VERSION ""

NS_ :

BS_:

BU_: WCM4 WCM3 WCM2 WCM VPM VLM VKM VICM VECM VDM VCU_RTOS_ETH VCU_ENTRY_ETH VCU_AGVM_ETH VCU UVM UPM TIM TEST_TOOL_1 TCP_ETH TCP TCM TCCM SRR_SRR_ETH SRR_SRR SRR_SLR_ETH SRR_SLR SRR_RR SRR_RF_ETH SRR_RF SRR_LR_CR SRR_LF_ETH SRR_LF SIB SDM SCL SBZA_R SBZA_L SBM SAM_RR SAM_RF SAM_LR SAM_LF SAM_BH SADS RadioLow_ETH RadioLow RSI_RTOS_ETH RSI RDCM PTM PLCM PFCM PDR_ETH PDR PCM PA ODS2 ODS NVM MTCM_R MTCM_L MSM_RR MSM_P MSM_LR MSM_D MSB2 MSB1 MRCM_R MRCM_L MFC LRR_RR_ETH LRR_LR_ETH LRR_CF_ETH LRR LRL_CF_ETH LIB_48V LIB1 IPC_INT IPC_GP IPC ICS_Info ICCM HVAC_FP_R HVAC_FP_F HUD_CAN HDLM FPI_RTOS_ETH FPI FOPM FCM_LC FCM EPSb EPS_1 EPSRAb EPSRAa EPS EOCM_HC_Superset EOCM_HCP2 EOCM ELM ECP_X1 ECP_S2 ECP_S ECP_MC ECP_H3 ECP_H2 ECP_H1 ECP_E ECM EBCM DMS DEFC DCM CSM_ETH CSM_AV CSM CGM_OTA_ETH CGM BSM_MH BSM_HEV BSM BCM ARS ARB APA AOS AMP ALC AHS AHL_AFL ADIMb ADIMa ACP2_MCU
VAL_TABLE_ SRRRFODPB4P_VOTk8CnfdStsAuth 0 "Highly Speculative" 1 "Speculative" 2 "Confident" 3 "Highly Confident" ;
VAL_TABLE_ SRRRFODPB4P_VOTk8DynPrpStsAuth 0 "Stopped" 1 "Not Stopped" ;
VAL_TABLE_ SRRRFODPB4P_VOTk8DynPrpAuth 0 "Has Never Moved" 1 "Moving In Same Direction As Host" 2 "Moving In Opposite Direction As Host" 3 "Crossing From Left To Right" 4 "Crossing From Right To Left" ;
VAL_TABLE_ SRRRFODPB4P_VOTk8MStsAuth 0 "No Object" 1 "New Object" 2 "Latent Track Not Detected this Cycle" 3 "Measured this Cycle" ;
VAL_TABLE_ SRRRFODPB4P_VOTk8TypCnfdAuth 0 "Highly Speculative" 1 "Speculative" 2 "Confident" 3 "Highly Confident" ;
VAL_TABLE_ SRRRFODPB4P_VOTk9DynPrpStsAuth 0 "Stopped" 1 "Not Stopped" ;
VAL_TABLE_ SRRRFODPB4P_VOTk9DynPrpAuth 0 "Has Never Moved" 1 "Moving In Same Direction As Host" 2 "Moving In Opposite Direction As Host" 3 "Crossing From Left To Right" 4 "Crossing From Right To Left" ;
VAL_TABLE_ SRRRFODPB4P_VOTk9CnfdStsAuth 0 "Highly Speculative" 1 "Speculative" 2 "Confident" 3 "Highly Confident" ;
VAL_TABLE_ SRRRFODPB4P_VOTk9MStsAuth 0 "No Object" 1 "New Object" 2 "Latent Track Not Detected this Cycle" 3 "Measured this Cycle" ;
VAL_TABLE_ SRRRFODPB4P_VOTk9TypCnfdAuth 0 "Highly Speculative" 1 "Speculative" 2 "Confident" 3 "Highly Confident" ;
VAL_TABLE_ SRRRFODPB5P_IOTk10ElvtnAuth 0 "Not Elevated" 1 "Elevation Speculative" 2 "Elevation Confident" 3 "Elevation Very Confident" ;
VAL_TABLE_ SRRRFODPB5P_IOTk10CnfdStsAuth 0 "Highly Speculative" 1 "Speculative" 2 "Confident" 3 "Highly Confident" ;
VAL_TABLE_ SRRRFODPB5P_IOTk10MStsAuth 0 "No Object" 1 "New Object" 2 "Latent Track Not Detected this Cycle" 3 "Measured this Cycle" ;
VAL_TABLE_ SRRRFODPB5P_IOTk1CnfdStsAuth 0 "Highly Speculative" 1 "Speculative" 2 "Confident" 3 "Highly Confident" ;
VAL_TABLE_ SRRRFODPB5P_IOTk10TypCnfdAuth 0 "Highly Speculative" 1 "Speculative" 2 "Confident" 3 "Highly Confident" ;
VAL_TABLE_ SRRRFODPB5P_IOTk10TypAuth 0 "Unknown" 1 "Guard Rail" 2 "Tunnel" 3 "Traffic Sign" 4 "Bridge" 5 "Pole" ;
VAL_TABLE_ SRRRFODPB5P_IOTk1ElvtnAuth 0 "Not Elevated" 1 "Elevation Speculative" 2 "Elevation Confident" 3 "Elevation Very Confident" ;
VAL_TABLE_ SRRRFODPB5P_IOTk1MStsAuth 0 "No Object" 1 "New Object" 2 "Latent Track Not Detected this Cycle" 3 "Measured this Cycle" ;
VAL_TABLE_ SRRRFODPB5P_IOTk1TypAuth 0 "Unknown" 1 "Guard Rail" 2 "Tunnel" 3 "Traffic Sign" 4 "Bridge" 5 "Pole" ;
VAL_TABLE_ SRRRFODPB5P_IOTk2ElvtnAuth 0 "Not Elevated" 1 "Elevation Speculative" 2 "Elevation Confident" 3 "Elevation Very Confident" ;
VAL_TABLE_ SRRRFODPB5P_IOTk2CnfdStsAuth 0 "Highly Speculative" 1 "Speculative" 2 "Confident" 3 "Highly Confident" ;
VAL_TABLE_ SRRRFODPB5P_IOTk1TypCnfdAuth 0 "Highly Speculative" 1 "Speculative" 2 "Confident" 3 "Highly Confident" ;
VAL_TABLE_ SRRRFODPB5P_IOTk2MStsAuth 0 "No Object" 1 "New Object" 2 "Latent Track Not Detected this Cycle" 3 "Measured this Cycle" ;
VAL_TABLE_ SRRRFODPB5P_IOTk2TypCnfdAuth 0 "Highly Speculative" 1 "Speculative" 2 "Confident" 3 "Highly Confident" ;
VAL_TABLE_ SRRRFODPB5P_IOTk2TypAuth 0 "Unknown" 1 "Guard Rail" 2 "Tunnel" 3 "Traffic Sign" 4 "Bridge" 5 "Pole" ;
VAL_TABLE_ SRRRFODPB5P_IOTk3ElvtnAuth 0 "Not Elevated" 1 "Elevation Speculative" 2 "Elevation Confident" 3 "Elevation Very Confident" ;
VAL_TABLE_ SRRRFODPB5P_IOTk3CnfdStsAuth 0 "Highly Speculative" 1 "Speculative" 2 "Confident" 3 "Highly Confident" ;
VAL_TABLE_ SRRRFODPB5P_IOTk3MStsAuth 0 "No Object" 1 "New Object" 2 "Latent Track Not Detected this Cycle" 3 "Measured this Cycle" ;
VAL_TABLE_ SRRRFODPB5P_IOTk4CnfdStsAuth 0 "Highly Speculative" 1 "Speculative" 2 "Confident" 3 "Highly Confident" ;
VAL_TABLE_ SRRRFODPB5P_IOTk3TypCnfdAuth 0 "Highly Speculative" 1 "Speculative" 2 "Confident" 3 "Highly Confident" ;
VAL_TABLE_ SRRRFODPB5P_IOTk3TypAuth 0 "Unknown" 1 "Guard Rail" 2 "Tunnel" 3 "Traffic Sign" 4 "Bridge" 5 "Pole" ;
VAL_TABLE_ SRRRFODPB5P_IOTk4ElvtnAuth 0 "Not Elevated" 1 "Elevation Speculative" 2 "Elevation Confident" 3 "Elevation Very Confident" ;
VAL_TABLE_ SRRRFODPB5P_IOTk4MStsAuth 0 "No Object" 1 "New Object" 2 "Latent Track Not Detected this Cycle" 3 "Measured this Cycle" ;
VAL_TABLE_ SRRRFODPB5P_IOTk4TypAuth 0 "Unknown" 1 "Guard Rail" 2 "Tunnel" 3 "Traffic Sign" 4 "Bridge" 5 "Pole" ;
VAL_TABLE_ SRRRFODPB5P_IOTk5ElvtnAuth 0 "Not Elevated" 1 "Elevation Speculative" 2 "Elevation Confident" 3 "Elevation Very Confident" ;
VAL_TABLE_ SRRRFODPB5P_IOTk5CnfdStsAuth 0 "Highly Speculative" 1 "Speculative" 2 "Confident" 3 "Highly Confident" ;
VAL_TABLE_ SRRRFODPB5P_IOTk4TypCnfdAuth 0 "Highly Speculative" 1 "Speculative" 2 "Confident" 3 "Highly Confident" ;
VAL_TABLE_ SRRRFODPB5P_IOTk5MStsAuth 0 "No Object" 1 "New Object" 2 "Latent Track Not Detected this Cycle" 3 "Measured this Cycle" ;
VAL_TABLE_ SRRRFODPB5P_IOTk5TypCnfdAuth 0 "Highly Speculative" 1 "Speculative" 2 "Confident" 3 "Highly Confident" ;
VAL_TABLE_ SRRRFODPB5P_IOTk5TypAuth 0 "Unknown" 1 "Guard Rail" 2 "Tunnel" 3 "Traffic Sign" 4 "Bridge" 5 "Pole" ;
VAL_TABLE_ SRRRFODPB5P_IOTk6ElvtnAuth 0 "Not Elevated" 1 "Elevation Speculative" 2 "Elevation Confident" 3 "Elevation Very Confident" ;
VAL_TABLE_ SRRRFODPB5P_IOTk6CnfdStsAuth 0 "Highly Speculative" 1 "Speculative" 2 "Confident" 3 "Highly Confident" ;
VAL_TABLE_ SRRRFODPB5P_IOTk6MStsAuth 0 "No Object" 1 "New Object" 2 "Latent Track Not Detected this Cycle" 3 "Measured this Cycle" ;
VAL_TABLE_ SRRRFODPB5P_IOTk7ElvtnAuth 0 "Not Elevated" 1 "Elevation Speculative" 2 "Elevation Confident" 3 "Elevation Very Confident" ;
VAL_TABLE_ SRRRFODPB5P_IOTk7CnfdStsAuth 0 "Highly Speculative" 1 "Speculative" 2 "Confident" 3 "Highly Confident" ;
VAL_TABLE_ SRRRFODPB5P_IOTk6TypCnfdAuth 0 "Highly Speculative" 1 "Speculative" 2 "Confident" 3 "Highly Confident" ;
VAL_TABLE_ SRRRFODPB5P_IOTk6TypAuth 0 "Unknown" 1 "Guard Rail" 2 "Tunnel" 3 "Traffic Sign" 4 "Bridge" 5 "Pole" ;
VAL_TABLE_ SRRRFODPB5P_IOTk7MStsAuth 0 "No Object" 1 "New Object" 2 "Latent Track Not Detected this Cycle" 3 "Measured this Cycle" ;
VAL_TABLE_ SRRRFODPB5P_IOTk7TypAuth 0 "Unknown" 1 "Guard Rail" 2 "Tunnel" 3 "Traffic Sign" 4 "Bridge" 5 "Pole" ;
VAL_TABLE_ SRRRFODPB5P_IOTk8ElvtnAuth 0 "Not Elevated" 1 "Elevation Speculative" 2 "Elevation Confident" 3 "Elevation Very Confident" ;
VAL_TABLE_ SRRRFODPB5P_IOTk8CnfdStsAuth 0 "Highly Speculative" 1 "Speculative" 2 "Confident" 3 "Highly Confident" ;
VAL_TABLE_ SRRRFODPB5P_IOTk7TypCnfdAuth 0 "Highly Speculative" 1 "Speculative" 2 "Confident" 3 "Highly Confident" ;
VAL_TABLE_ SRRRFODPB5P_IOTk8MStsAuth 0 "No Object" 1 "New Object" 2 "Latent Track Not Detected this Cycle" 3 "Measured this Cycle" ;
VAL_TABLE_ SRRRFODPB5P_IOTk9CnfdStsAuth 0 "Highly Speculative" 1 "Speculative" 2 "Confident" 3 "Highly Confident" ;
VAL_TABLE_ SRRRFODPB5P_IOTk8TypCnfdAuth 0 "Highly Speculative" 1 "Speculative" 2 "Confident" 3 "Highly Confident" ;
VAL_TABLE_ SRRRFODPB5P_IOTk8TypAuth 0 "Unknown" 1 "Guard Rail" 2 "Tunnel" 3 "Traffic Sign" 4 "Bridge" 5 "Pole" ;
VAL_TABLE_ SRRRFODPB5P_IOTk9ElvtnAuth 0 "Not Elevated" 1 "Elevation Speculative" 2 "Elevation Confident" 3 "Elevation Very Confident" ;
VAL_TABLE_ SRRRFODPB5P_IOTk9MStsAuth 0 "No Object" 1 "New Object" 2 "Latent Track Not Detected this Cycle" 3 "Measured this Cycle" ;
VAL_TABLE_ SRRRFODPB5P_IOTk9TypAuth 0 "Unknown" 1 "Guard Rail" 2 "Tunnel" 3 "Traffic Sign" 4 "Bridge" 5 "Pole" ;
VAL_TABLE_ SRRRFODPB5P_IOTk9TypCnfdAuth 0 "Highly Speculative" 1 "Speculative" 2 "Confident" 3 "Highly Confident" ;
VAL_TABLE_ SRRRFODPB1P_ConstrArDtnCnfdAuth 0 "Highly Speculative" 1 "Speculative" 2 "Confident" 3 "Highly Confident" ;
VAL_TABLE_ SRRRFODPB1P_AcqTmStmAuth_Inv 0 "FALSE" 1 "TRUE" ;
VAL_TABLE_ SRRRFODPB1P_POTk1DynPrpAuth 0 "Has Never Moved" 1 "Has Moved But Currently Stopped" 2 "Moving In Same Direction As Host" 3 "Moving In Opposite Direction As Host" 4 "Crossing Path" ;
VAL_TABLE_ SRRRFODPB1P_POTk1CnfdStsAuth 0 "Highly Speculative" 1 "Speculative" 2 "Confident" 3 "Highly Confident" ;
VAL_TABLE_ SRRRFODPB1P_MdCmdStsAuth 0 "Not Radiating" 1 "Reporting Object Data" 2 "Not Reporting Object Data" ;
VAL_TABLE_ SRRRFODPB1P_ConstrArDtnStsAuth 0 "Not Detected" 1 "Detected" 2 "Unknown" ;
VAL_TABLE_ SRRRFODPB1P_POTk1MStsAuth 0 "No Object" 1 "New Object" 2 "Latent Track Not Detected this Cycle" 3 "Measured this Cycle" ;
VAL_TABLE_ SRRRFODPB1P_POTk2CnfdStsAuth 0 "Highly Speculative" 1 "Speculative" 2 "Confident" 3 "Highly Confident" ;
VAL_TABLE_ SRRRFODPB1P_POTk1TypCnfdAuth 0 "Highly Speculative" 1 "Speculative" 2 "Confident" 3 "Highly Confident" ;
VAL_TABLE_ SRRRFODPB1P_POTk1TypAuth 0 "Unknown" 1 "Pedestrian" 2 "Bicycle" ;
VAL_TABLE_ SRRRFODPB1P_POTk2DynPrpAuth 0 "Has Never Moved" 1 "Has Moved But Currently Stopped" 2 "Moving In Same Direction As Host" 3 "Moving In Opposite Direction As Host" 4 "Crossing Path" ;
VAL_TABLE_ SRRRFODPB1P_POTk2MStsAuth 0 "No Object" 1 "New Object" 2 "Latent Track Not Detected this Cycle" 3 "Measured this Cycle" ;
VAL_TABLE_ SRRRFODPB1P_POTk2TypCnfdAuth 0 "Highly Speculative" 1 "Speculative" 2 "Confident" 3 "Highly Confident" ;
VAL_TABLE_ SRRRFODPB1P_POTk2TypAuth 0 "Unknown" 1 "Pedestrian" 2 "Bicycle" ;
VAL_TABLE_ SRRRFODPB1P_SnsrUnvAuth 0 "FALSE" 1 "TRUE" ;
VAL_TABLE_ SRRRFODPB1P_SnsrBlckdAuth 0 "FALSE" 1 "TRUE" ;
VAL_TABLE_ SRRRFODPB1P_ServRqrdAuth 0 "FALSE" 1 "TRUE" ;
VAL_TABLE_ SRRRFODPB1P_RdTypCnfdAuth 0 "Highly Speculative" 1 "Speculative" 2 "Confident" 3 "Highly Confident" ;
VAL_TABLE_ SRRRFODPB1P_RdTypAuth 0 "Unknown" 1 "City" 2 "Secondary Road" 3 "Highway" 4 "Construction Zone Entry" 5 "Construction Zone Exit" ;
VAL_TABLE_ SRRRFODPB1P_SwpBndwdthStsAuth 0 "Mode A" 1 "Mode B" 2 "Mode C" 3 "Mode D" ;
VAL_TABLE_ SRRRFODPB1P_VOTk1DynPrpStsAuth 0 "Stopped" 1 "Not Stopped" ;
VAL_TABLE_ SRRRFODPB1P_VOTk1DynPrpAuth 0 "Has Never Moved" 1 "Moving In Same Direction As Host" 2 "Moving In Opposite Direction As Host" 3 "Crossing From Left To Right" 4 "Crossing From Right To Left" ;
VAL_TABLE_ SRRRFODPB1P_VOTk1CnfdStsAuth 0 "Highly Speculative" 1 "Speculative" 2 "Confident" 3 "Highly Confident" ;
VAL_TABLE_ SRRRFODPB1P_VOTk1MStsAuth 0 "No Object" 1 "New Object" 2 "Latent Track Not Detected this Cycle" 3 "Measured this Cycle" ;
VAL_TABLE_ SRRRFODPB1P_VOTk1TypCnfdAuth 0 "Highly Speculative" 1 "Speculative" 2 "Confident" 3 "Highly Confident" ;
VAL_TABLE_ SRRRFODPB6P_REOTk1CnfdStsAuth 0 "Highly Speculative" 1 "Speculative" 2 "Confident" 3 "Highly Confident" ;
VAL_TABLE_ SRRRFODPB6P_REOTk2CnfdStsAuth 0 "Highly Speculative" 1 "Speculative" 2 "Confident" 3 "Highly Confident" ;
VAL_TABLE_ SRRRFODPB6P_REOTk1TypCnfdAuth 0 "Highly Speculative" 1 "Speculative" 2 "Confident" 3 "Highly Confident" ;
VAL_TABLE_ SRRRFODPB6P_REOTk1TypAuth 0 "Unknown" 1 "Barriers" 2 "Guard Rails" 3 "Bridge Abutments" 4 "Edge of Road" 5 "Open Area" ;
VAL_TABLE_ SRRRFODPB6P_REOTk3CnfdStsAuth 0 "Highly Speculative" 1 "Speculative" 2 "Confident" 3 "Highly Confident" ;
VAL_TABLE_ SRRRFODPB6P_REOTk2TypCnfdAuth 0 "Highly Speculative" 1 "Speculative" 2 "Confident" 3 "Highly Confident" ;
VAL_TABLE_ SRRRFODPB6P_REOTk2TypAuth 0 "Unknown" 1 "Barriers" 2 "Guard Rails" 3 "Bridge Abutments" 4 "Edge of Road" 5 "Open Area" ;
VAL_TABLE_ SRRRFODPB6P_REOTk3TypCnfdAuth 0 "Highly Speculative" 1 "Speculative" 2 "Confident" 3 "Highly Confident" ;
VAL_TABLE_ SRRRFODPB6P_REOTk3TypAuth 0 "Unknown" 1 "Barriers" 2 "Guard Rails" 3 "Bridge Abutments" 4 "Edge of Road" 5 "Open Area" ;
VAL_TABLE_ SRRRRODPB2P_POTk3DynPrpAuth 0 "Has Never Moved" 1 "Has Moved But Currently Stopped" 2 "Moving In Same Direction As Host" 3 "Moving In Opposite Direction As Host" 4 "Crossing Path" ;
VAL_TABLE_ SRRRRODPB2P_POTk3CnfdStsAuth 0 "Highly Speculative" 1 "Speculative" 2 "Confident" 3 "Highly Confident" ;
VAL_TABLE_ SRRRRODPB2P_POTk3MStsAuth 0 "No Object" 1 "New Object" 2 "Latent Track Not Detected this Cycle" 3 "Measured this Cycle" ;
VAL_TABLE_ SRRRRODPB2P_POTk3TypCnfdAuth 0 "Highly Speculative" 1 "Speculative" 2 "Confident" 3 "Highly Confident" ;
VAL_TABLE_ SRRRRODPB2P_POTk3TypAuth 0 "Unknown" 1 "Pedestrian" 2 "Bicycle" ;
VAL_TABLE_ SRRRRODPB2P_VOTk2DynPrpStsAuth 0 "Stopped" 1 "Not Stopped" ;
VAL_TABLE_ SRRRRODPB2P_VOTk2DynPrpAuth 0 "Has Never Moved" 1 "Moving In Same Direction As Host" 2 "Moving In Opposite Direction As Host" 3 "Crossing From Left To Right" 4 "Crossing From Right To Left" ;
VAL_TABLE_ SRRRRODPB2P_VOTk2CnfdStsAuth 0 "Highly Speculative" 1 "Speculative" 2 "Confident" 3 "Highly Confident" ;
VAL_TABLE_ SRRRRODPB2P_VOTk2MStsAuth 0 "No Object" 1 "New Object" 2 "Latent Track Not Detected this Cycle" 3 "Measured this Cycle" ;
VAL_TABLE_ SRRRRODPB2P_VOTk2TypCnfdAuth 0 "Highly Speculative" 1 "Speculative" 2 "Confident" 3 "Highly Confident" ;
VAL_TABLE_ SRRRRODPB2P_VOTk3CnfdStsAuth 0 "Highly Speculative" 1 "Speculative" 2 "Confident" 3 "Highly Confident" ;
VAL_TABLE_ SRRRRODPB2P_VOTk3DynPrpStsAuth 0 "Stopped" 1 "Not Stopped" ;
VAL_TABLE_ SRRRRODPB2P_VOTk3DynPrpAuth 0 "Has Never Moved" 1 "Moving In Same Direction As Host" 2 "Moving In Opposite Direction As Host" 3 "Crossing From Left To Right" 4 "Crossing From Right To Left" ;
VAL_TABLE_ SRRRRODPB2P_VOTk3MStsAuth 0 "No Object" 1 "New Object" 2 "Latent Track Not Detected this Cycle" 3 "Measured this Cycle" ;
VAL_TABLE_ SRRRRODPB2P_VOTk3TypCnfdAuth 0 "Highly Speculative" 1 "Speculative" 2 "Confident" 3 "Highly Confident" ;
VAL_TABLE_ SRRRRODPB2P_VOTk4DynPrpStsAuth 0 "Stopped" 1 "Not Stopped" ;
VAL_TABLE_ SRRRRODPB2P_VOTk4DynPrpAuth 0 "Has Never Moved" 1 "Moving In Same Direction As Host" 2 "Moving In Opposite Direction As Host" 3 "Crossing From Left To Right" 4 "Crossing From Right To Left" ;
VAL_TABLE_ SRRRRODPB2P_VOTk4CnfdStsAuth 0 "Highly Speculative" 1 "Speculative" 2 "Confident" 3 "Highly Confident" ;
VAL_TABLE_ SRRRRODPB2P_VOTk4MStsAuth 0 "No Object" 1 "New Object" 2 "Latent Track Not Detected this Cycle" 3 "Measured this Cycle" ;
VAL_TABLE_ SRRRRODPB2P_VOTk4TypCnfdAuth 0 "Highly Speculative" 1 "Speculative" 2 "Confident" 3 "Highly Confident" ;
VAL_TABLE_ SRRRRODPB3P_POTk4DynPrpAuth 0 "Has Never Moved" 1 "Has Moved But Currently Stopped" 2 "Moving In Same Direction As Host" 3 "Moving In Opposite Direction As Host" 4 "Crossing Path" ;
VAL_TABLE_ SRRRRODPB3P_POTk4CnfdStsAuth 0 "Highly Speculative" 1 "Speculative" 2 "Confident" 3 "Highly Confident" ;
VAL_TABLE_ SRRRRODPB3P_POTk4MStsAuth 0 "No Object" 1 "New Object" 2 "Latent Track Not Detected this Cycle" 3 "Measured this Cycle" ;
VAL_TABLE_ SRRRRODPB3P_POTk4TypCnfdAuth 0 "Highly Speculative" 1 "Speculative" 2 "Confident" 3 "Highly Confident" ;
VAL_TABLE_ SRRRRODPB3P_POTk4TypAuth 0 "Unknown" 1 "Pedestrian" 2 "Bicycle" ;
VAL_TABLE_ SRRRRODPB3P_VOTk5DynPrpStsAuth 0 "Stopped" 1 "Not Stopped" ;
VAL_TABLE_ SRRRRODPB3P_VOTk5DynPrpAuth 0 "Has Never Moved" 1 "Moving In Same Direction As Host" 2 "Moving In Opposite Direction As Host" 3 "Crossing From Left To Right" 4 "Crossing From Right To Left" ;
VAL_TABLE_ SRRRRODPB3P_VOTk5CnfdStsAuth 0 "Highly Speculative" 1 "Speculative" 2 "Confident" 3 "Highly Confident" ;
VAL_TABLE_ SRRRRODPB3P_VOTk5MStsAuth 0 "No Object" 1 "New Object" 2 "Latent Track Not Detected this Cycle" 3 "Measured this Cycle" ;
VAL_TABLE_ SRRRRODPB3P_VOTk5TypCnfdAuth 0 "Highly Speculative" 1 "Speculative" 2 "Confident" 3 "Highly Confident" ;
VAL_TABLE_ SRRRRODPB3P_VOTk6CnfdStsAuth 0 "Highly Speculative" 1 "Speculative" 2 "Confident" 3 "Highly Confident" ;
VAL_TABLE_ SRRRRODPB3P_VOTk6DynPrpStsAuth 0 "Stopped" 1 "Not Stopped" ;
VAL_TABLE_ SRRRRODPB3P_VOTk6DynPrpAuth 0 "Has Never Moved" 1 "Moving In Same Direction As Host" 2 "Moving In Opposite Direction As Host" 3 "Crossing From Left To Right" 4 "Crossing From Right To Left" ;
VAL_TABLE_ SRRRRODPB3P_VOTk6MStsAuth 0 "No Object" 1 "New Object" 2 "Latent Track Not Detected this Cycle" 3 "Measured this Cycle" ;
VAL_TABLE_ SRRRRODPB3P_VOTk6TypCnfdAuth 0 "Highly Speculative" 1 "Speculative" 2 "Confident" 3 "Highly Confident" ;
VAL_TABLE_ SRRRRODPB3P_VOTk7DynPrpStsAuth 0 "Stopped" 1 "Not Stopped" ;
VAL_TABLE_ SRRRRODPB3P_VOTk7DynPrpAuth 0 "Has Never Moved" 1 "Moving In Same Direction As Host" 2 "Moving In Opposite Direction As Host" 3 "Crossing From Left To Right" 4 "Crossing From Right To Left" ;
VAL_TABLE_ SRRRRODPB3P_VOTk7CnfdStsAuth 0 "Highly Speculative" 1 "Speculative" 2 "Confident" 3 "Highly Confident" ;
VAL_TABLE_ SRRRRODPB3P_VOTk7MStsAuth 0 "No Object" 1 "New Object" 2 "Latent Track Not Detected this Cycle" 3 "Measured this Cycle" ;
VAL_TABLE_ SRRRRODPB3P_VOTk7TypCnfdAuth 0 "Highly Speculative" 1 "Speculative" 2 "Confident" 3 "Highly Confident" ;
VAL_TABLE_ SRRRRODPB4P_POTk5DynPrpAuth 0 "Has Never Moved" 1 "Has Moved But Currently Stopped" 2 "Moving In Same Direction As Host" 3 "Moving In Opposite Direction As Host" 4 "Crossing Path" ;
VAL_TABLE_ SRRRRODPB4P_POTk5CnfdStsAuth 0 "Highly Speculative" 1 "Speculative" 2 "Confident" 3 "Highly Confident" ;
VAL_TABLE_ SRRRRODPB4P_POTk5MStsAuth 0 "No Object" 1 "New Object" 2 "Latent Track Not Detected this Cycle" 3 "Measured this Cycle" ;
VAL_TABLE_ SRRRRODPB4P_POTk5TypCnfdAuth 0 "Highly Speculative" 1 "Speculative" 2 "Confident" 3 "Highly Confident" ;
VAL_TABLE_ SRRRRODPB4P_POTk5TypAuth 0 "Unknown" 1 "Pedestrian" 2 "Bicycle" ;
VAL_TABLE_ SRRRRODPB4P_VOTk10DynPrpStsAuth 0 "Stopped" 1 "Not Stopped" ;
VAL_TABLE_ SRRRRODPB4P_VOTk10DynPrpAuth 0 "Has Never Moved" 1 "Moving In Same Direction As Host" 2 "Moving In Opposite Direction As Host" 3 "Crossing From Left To Right" 4 "Crossing From Right To Left" ;
VAL_TABLE_ SRRRRODPB4P_VOTk10CnfdStsAuth 0 "Highly Speculative" 1 "Speculative" 2 "Confident" 3 "Highly Confident" ;
VAL_TABLE_ SRRRRODPB4P_VOTk10MStsAuth 0 "No Object" 1 "New Object" 2 "Latent Track Not Detected this Cycle" 3 "Measured this Cycle" ;
VAL_TABLE_ SRRRRODPB4P_VOTk10TypCnfdAuth 0 "Highly Speculative" 1 "Speculative" 2 "Confident" 3 "Highly Confident" ;
VAL_TABLE_ SRRRRODPB4P_VOTk8CnfdStsAuth 0 "Highly Speculative" 1 "Speculative" 2 "Confident" 3 "Highly Confident" ;
VAL_TABLE_ SRRRRODPB4P_VOTk8DynPrpStsAuth 0 "Stopped" 1 "Not Stopped" ;
VAL_TABLE_ SRRRRODPB4P_VOTk8DynPrpAuth 0 "Has Never Moved" 1 "Moving In Same Direction As Host" 2 "Moving In Opposite Direction As Host" 3 "Crossing From Left To Right" 4 "Crossing From Right To Left" ;
VAL_TABLE_ SRRRRODPB4P_VOTk8MStsAuth 0 "No Object" 1 "New Object" 2 "Latent Track Not Detected this Cycle" 3 "Measured this Cycle" ;
VAL_TABLE_ SRRRRODPB4P_VOTk8TypCnfdAuth 0 "Highly Speculative" 1 "Speculative" 2 "Confident" 3 "Highly Confident" ;
VAL_TABLE_ SRRRRODPB4P_VOTk9DynPrpStsAuth 0 "Stopped" 1 "Not Stopped" ;
VAL_TABLE_ SRRRRODPB4P_VOTk9DynPrpAuth 0 "Has Never Moved" 1 "Moving In Same Direction As Host" 2 "Moving In Opposite Direction As Host" 3 "Crossing From Left To Right" 4 "Crossing From Right To Left" ;
VAL_TABLE_ SRRRRODPB4P_VOTk9CnfdStsAuth 0 "Highly Speculative" 1 "Speculative" 2 "Confident" 3 "Highly Confident" ;
VAL_TABLE_ SRRRRODPB4P_VOTk9MStsAuth 0 "No Object" 1 "New Object" 2 "Latent Track Not Detected this Cycle" 3 "Measured this Cycle" ;
VAL_TABLE_ SRRRRODPB4P_VOTk9TypCnfdAuth 0 "Highly Speculative" 1 "Speculative" 2 "Confident" 3 "Highly Confident" ;
VAL_TABLE_ SRRRRODPB5P_IOTk10ElvtnAuth 0 "Not Elevated" 1 "Elevation Speculative" 2 "Elevation Confident" 3 "Elevation Very Confident" ;
VAL_TABLE_ SRRRRODPB5P_IOTk10CnfdStsAuth 0 "Highly Speculative" 1 "Speculative" 2 "Confident" 3 "Highly Confident" ;
VAL_TABLE_ SRRRRODPB5P_IOTk10MStsAuth 0 "No Object" 1 "New Object" 2 "Latent Track Not Detected this Cycle" 3 "Measured this Cycle" ;
VAL_TABLE_ SRRRRODPB5P_IOTk1CnfdStsAuth 0 "Highly Speculative" 1 "Speculative" 2 "Confident" 3 "Highly Confident" ;
VAL_TABLE_ SRRRRODPB5P_IOTk10TypCnfdAuth 0 "Highly Speculative" 1 "Speculative" 2 "Confident" 3 "Highly Confident" ;
VAL_TABLE_ SRRRRODPB5P_IOTk10TypAuth 0 "Unknown" 1 "Guard Rail" 2 "Tunnel" 3 "Traffic Sign" 4 "Bridge" 5 "Pole" ;
VAL_TABLE_ SRRRRODPB5P_IOTk1ElvtnAuth 0 "Not Elevated" 1 "Elevation Speculative" 2 "Elevation Confident" 3 "Elevation Very Confident" ;
VAL_TABLE_ SRRRRODPB5P_IOTk1MStsAuth 0 "No Object" 1 "New Object" 2 "Latent Track Not Detected this Cycle" 3 "Measured this Cycle" ;
VAL_TABLE_ SRRRRODPB5P_IOTk1TypAuth 0 "Unknown" 1 "Guard Rail" 2 "Tunnel" 3 "Traffic Sign" 4 "Bridge" 5 "Pole" ;
VAL_TABLE_ SRRRRODPB5P_IOTk2ElvtnAuth 0 "Not Elevated" 1 "Elevation Speculative" 2 "Elevation Confident" 3 "Elevation Very Confident" ;
VAL_TABLE_ SRRRRODPB5P_IOTk2CnfdStsAuth 0 "Highly Speculative" 1 "Speculative" 2 "Confident" 3 "Highly Confident" ;
VAL_TABLE_ SRRRRODPB5P_IOTk1TypCnfdAuth 0 "Highly Speculative" 1 "Speculative" 2 "Confident" 3 "Highly Confident" ;
VAL_TABLE_ SRRRRODPB5P_IOTk2MStsAuth 0 "No Object" 1 "New Object" 2 "Latent Track Not Detected this Cycle" 3 "Measured this Cycle" ;
VAL_TABLE_ SRRRRODPB5P_IOTk2TypCnfdAuth 0 "Highly Speculative" 1 "Speculative" 2 "Confident" 3 "Highly Confident" ;
VAL_TABLE_ SRRRRODPB5P_IOTk2TypAuth 0 "Unknown" 1 "Guard Rail" 2 "Tunnel" 3 "Traffic Sign" 4 "Bridge" 5 "Pole" ;
VAL_TABLE_ SRRRRODPB5P_IOTk3ElvtnAuth 0 "Not Elevated" 1 "Elevation Speculative" 2 "Elevation Confident" 3 "Elevation Very Confident" ;
VAL_TABLE_ SRRRRODPB5P_IOTk3CnfdStsAuth 0 "Highly Speculative" 1 "Speculative" 2 "Confident" 3 "Highly Confident" ;
VAL_TABLE_ SRRRRODPB5P_IOTk3MStsAuth 0 "No Object" 1 "New Object" 2 "Latent Track Not Detected this Cycle" 3 "Measured this Cycle" ;
VAL_TABLE_ SRRRRODPB5P_IOTk4CnfdStsAuth 0 "Highly Speculative" 1 "Speculative" 2 "Confident" 3 "Highly Confident" ;
VAL_TABLE_ SRRRRODPB5P_IOTk3TypCnfdAuth 0 "Highly Speculative" 1 "Speculative" 2 "Confident" 3 "Highly Confident" ;
VAL_TABLE_ SRRRRODPB5P_IOTk3TypAuth 0 "Unknown" 1 "Guard Rail" 2 "Tunnel" 3 "Traffic Sign" 4 "Bridge" 5 "Pole" ;
VAL_TABLE_ SRRRRODPB5P_IOTk4ElvtnAuth 0 "Not Elevated" 1 "Elevation Speculative" 2 "Elevation Confident" 3 "Elevation Very Confident" ;
VAL_TABLE_ SRRRRODPB5P_IOTk4MStsAuth 0 "No Object" 1 "New Object" 2 "Latent Track Not Detected this Cycle" 3 "Measured this Cycle" ;
VAL_TABLE_ SRRRRODPB5P_IOTk4TypAuth 0 "Unknown" 1 "Guard Rail" 2 "Tunnel" 3 "Traffic Sign" 4 "Bridge" 5 "Pole" ;
VAL_TABLE_ SRRRRODPB5P_IOTk5ElvtnAuth 0 "Not Elevated" 1 "Elevation Speculative" 2 "Elevation Confident" 3 "Elevation Very Confident" ;
VAL_TABLE_ SRRRRODPB5P_IOTk5CnfdStsAuth 0 "Highly Speculative" 1 "Speculative" 2 "Confident" 3 "Highly Confident" ;
VAL_TABLE_ SRRRRODPB5P_IOTk4TypCnfdAuth 0 "Highly Speculative" 1 "Speculative" 2 "Confident" 3 "Highly Confident" ;
VAL_TABLE_ SRRRRODPB5P_IOTk5MStsAuth 0 "No Object" 1 "New Object" 2 "Latent Track Not Detected this Cycle" 3 "Measured this Cycle" ;
VAL_TABLE_ SRRRRODPB5P_IOTk5TypCnfdAuth 0 "Highly Speculative" 1 "Speculative" 2 "Confident" 3 "Highly Confident" ;
VAL_TABLE_ SRRRRODPB5P_IOTk5TypAuth 0 "Unknown" 1 "Guard Rail" 2 "Tunnel" 3 "Traffic Sign" 4 "Bridge" 5 "Pole" ;
VAL_TABLE_ SRRRRODPB5P_IOTk6ElvtnAuth 0 "Not Elevated" 1 "Elevation Speculative" 2 "Elevation Confident" 3 "Elevation Very Confident" ;
VAL_TABLE_ SRRRRODPB5P_IOTk6CnfdStsAuth 0 "Highly Speculative" 1 "Speculative" 2 "Confident" 3 "Highly Confident" ;
VAL_TABLE_ SRRRRODPB5P_IOTk6MStsAuth 0 "No Object" 1 "New Object" 2 "Latent Track Not Detected this Cycle" 3 "Measured this Cycle" ;
VAL_TABLE_ SRRRRODPB5P_IOTk7ElvtnAuth 0 "Not Elevated" 1 "Elevation Speculative" 2 "Elevation Confident" 3 "Elevation Very Confident" ;
VAL_TABLE_ SRRRRODPB5P_IOTk7CnfdStsAuth 0 "Highly Speculative" 1 "Speculative" 2 "Confident" 3 "Highly Confident" ;
VAL_TABLE_ SRRRRODPB5P_IOTk6TypCnfdAuth 0 "Highly Speculative" 1 "Speculative" 2 "Confident" 3 "Highly Confident" ;
VAL_TABLE_ SRRRRODPB5P_IOTk6TypAuth 0 "Unknown" 1 "Guard Rail" 2 "Tunnel" 3 "Traffic Sign" 4 "Bridge" 5 "Pole" ;
VAL_TABLE_ SRRRRODPB5P_IOTk7MStsAuth 0 "No Object" 1 "New Object" 2 "Latent Track Not Detected this Cycle" 3 "Measured this Cycle" ;
VAL_TABLE_ SRRRRODPB5P_IOTk7TypAuth 0 "Unknown" 1 "Guard Rail" 2 "Tunnel" 3 "Traffic Sign" 4 "Bridge" 5 "Pole" ;
VAL_TABLE_ SRRRRODPB5P_IOTk8ElvtnAuth 0 "Not Elevated" 1 "Elevation Speculative" 2 "Elevation Confident" 3 "Elevation Very Confident" ;
VAL_TABLE_ SRRRRODPB5P_IOTk8CnfdStsAuth 0 "Highly Speculative" 1 "Speculative" 2 "Confident" 3 "Highly Confident" ;
VAL_TABLE_ SRRRRODPB5P_IOTk7TypCnfdAuth 0 "Highly Speculative" 1 "Speculative" 2 "Confident" 3 "Highly Confident" ;
VAL_TABLE_ SRRRRODPB5P_IOTk8MStsAuth 0 "No Object" 1 "New Object" 2 "Latent Track Not Detected this Cycle" 3 "Measured this Cycle" ;
VAL_TABLE_ SRRRRODPB5P_IOTk9CnfdStsAuth 0 "Highly Speculative" 1 "Speculative" 2 "Confident" 3 "Highly Confident" ;
VAL_TABLE_ SRRRRODPB5P_IOTk8TypCnfdAuth 0 "Highly Speculative" 1 "Speculative" 2 "Confident" 3 "Highly Confident" ;
VAL_TABLE_ SRRRRODPB5P_IOTk8TypAuth 0 "Unknown" 1 "Guard Rail" 2 "Tunnel" 3 "Traffic Sign" 4 "Bridge" 5 "Pole" ;
VAL_TABLE_ SRRRRODPB5P_IOTk9ElvtnAuth 0 "Not Elevated" 1 "Elevation Speculative" 2 "Elevation Confident" 3 "Elevation Very Confident" ;
VAL_TABLE_ SRRRRODPB5P_IOTk9MStsAuth 0 "No Object" 1 "New Object" 2 "Latent Track Not Detected this Cycle" 3 "Measured this Cycle" ;
VAL_TABLE_ SRRRRODPB5P_IOTk9TypAuth 0 "Unknown" 1 "Guard Rail" 2 "Tunnel" 3 "Traffic Sign" 4 "Bridge" 5 "Pole" ;
VAL_TABLE_ SRRRRODPB5P_IOTk9TypCnfdAuth 0 "Highly Speculative" 1 "Speculative" 2 "Confident" 3 "Highly Confident" ;
VAL_TABLE_ SRRRRODPB1P_ConstrArDtnCnfdAuth 0 "Highly Speculative" 1 "Speculative" 2 "Confident" 3 "Highly Confident" ;
VAL_TABLE_ SRRRRODPB1P_AcqTmStmAuth_Inv 0 "FALSE" 1 "TRUE" ;
VAL_TABLE_ SRRRRODPB1P_POTk1DynPrpAuth 0 "Has Never Moved" 1 "Has Moved But Currently Stopped" 2 "Moving In Same Direction As Host" 3 "Moving In Opposite Direction As Host" 4 "Crossing Path" ;
VAL_TABLE_ SRRRRODPB1P_POTk1CnfdStsAuth 0 "Highly Speculative" 1 "Speculative" 2 "Confident" 3 "Highly Confident" ;
VAL_TABLE_ SRRRRODPB1P_MdCmdStsAuth 0 "Not Radiating" 1 "Reporting Object Data" 2 "Not Reporting Object Data" ;
VAL_TABLE_ SRRRRODPB1P_ConstrArDtnStsAuth 0 "Not Detected" 1 "Detected" 2 "Unknown" ;
VAL_TABLE_ SRRRRODPB1P_POTk1MStsAuth 0 "No Object" 1 "New Object" 2 "Latent Track Not Detected this Cycle" 3 "Measured this Cycle" ;
VAL_TABLE_ SRRRRODPB1P_POTk2CnfdStsAuth 0 "Highly Speculative" 1 "Speculative" 2 "Confident" 3 "Highly Confident" ;
VAL_TABLE_ SRRRRODPB1P_POTk1TypCnfdAuth 0 "Highly Speculative" 1 "Speculative" 2 "Confident" 3 "Highly Confident" ;
VAL_TABLE_ SRRRRODPB1P_POTk1TypAuth 0 "Unknown" 1 "Pedestrian" 2 "Bicycle" ;
VAL_TABLE_ SRRRRODPB1P_POTk2DynPrpAuth 0 "Has Never Moved" 1 "Has Moved But Currently Stopped" 2 "Moving In Same Direction As Host" 3 "Moving In Opposite Direction As Host" 4 "Crossing Path" ;
VAL_TABLE_ SRRRRODPB1P_POTk2MStsAuth 0 "No Object" 1 "New Object" 2 "Latent Track Not Detected this Cycle" 3 "Measured this Cycle" ;
VAL_TABLE_ SRRRRODPB1P_POTk2TypCnfdAuth 0 "Highly Speculative" 1 "Speculative" 2 "Confident" 3 "Highly Confident" ;
VAL_TABLE_ SRRRRODPB1P_POTk2TypAuth 0 "Unknown" 1 "Pedestrian" 2 "Bicycle" ;
VAL_TABLE_ SRRRRODPB1P_SnsrUnvAuth 0 "FALSE" 1 "TRUE" ;
VAL_TABLE_ SRRRRODPB1P_SnsrBlckdAuth 0 "FALSE" 1 "TRUE" ;
VAL_TABLE_ SRRRRODPB1P_ServRqrdAuth 0 "FALSE" 1 "TRUE" ;
VAL_TABLE_ SRRRRODPB1P_RdTypCnfdAuth 0 "Highly Speculative" 1 "Speculative" 2 "Confident" 3 "Highly Confident" ;
VAL_TABLE_ SRRRRODPB1P_RdTypAuth 0 "Unknown" 1 "City" 2 "Secondary Road" 3 "Highway" 4 "Construction Zone Entry" 5 "Construction Zone Exit" ;
VAL_TABLE_ SRRRRODPB1P_SwpBndwdthStsAuth 0 "Mode A" 1 "Mode B" 2 "Mode C" 3 "Mode D" ;
VAL_TABLE_ SRRRRODPB1P_VOTk1DynPrpStsAuth 0 "Stopped" 1 "Not Stopped" ;
VAL_TABLE_ SRRRRODPB1P_VOTk1DynPrpAuth 0 "Has Never Moved" 1 "Moving In Same Direction As Host" 2 "Moving In Opposite Direction As Host" 3 "Crossing From Left To Right" 4 "Crossing From Right To Left" ;
VAL_TABLE_ SRRRRODPB1P_VOTk1CnfdStsAuth 0 "Highly Speculative" 1 "Speculative" 2 "Confident" 3 "Highly Confident" ;
VAL_TABLE_ SRRRRODPB1P_VOTk1MStsAuth 0 "No Object" 1 "New Object" 2 "Latent Track Not Detected this Cycle" 3 "Measured this Cycle" ;
VAL_TABLE_ SRRRRODPB1P_VOTk1TypCnfdAuth 0 "Highly Speculative" 1 "Speculative" 2 "Confident" 3 "Highly Confident" ;
VAL_TABLE_ SRRRRODPB6P_REOTk1CnfdStsAuth 0 "Highly Speculative" 1 "Speculative" 2 "Confident" 3 "Highly Confident" ;
VAL_TABLE_ SRRRRODPB6P_REOTk2CnfdStsAuth 0 "Highly Speculative" 1 "Speculative" 2 "Confident" 3 "Highly Confident" ;
VAL_TABLE_ SRRRRODPB6P_REOTk1TypCnfdAuth 0 "Highly Speculative" 1 "Speculative" 2 "Confident" 3 "Highly Confident" ;
VAL_TABLE_ SRRRRODPB6P_REOTk1TypAuth 0 "Unknown" 1 "Barriers" 2 "Guard Rails" 3 "Bridge Abutments" 4 "Edge of Road" 5 "Open Area" ;
VAL_TABLE_ SRRRRODPB6P_REOTk3CnfdStsAuth 0 "Highly Speculative" 1 "Speculative" 2 "Confident" 3 "Highly Confident" ;
VAL_TABLE_ SRRRRODPB6P_REOTk2TypCnfdAuth 0 "Highly Speculative" 1 "Speculative" 2 "Confident" 3 "Highly Confident" ;
VAL_TABLE_ SRRRRODPB6P_REOTk2TypAuth 0 "Unknown" 1 "Barriers" 2 "Guard Rails" 3 "Bridge Abutments" 4 "Edge of Road" 5 "Open Area" ;
VAL_TABLE_ SRRRRODPB6P_REOTk3TypCnfdAuth 0 "Highly Speculative" 1 "Speculative" 2 "Confident" 3 "Highly Confident" ;
VAL_TABLE_ SRRRRODPB6P_REOTk3TypAuth 0 "Unknown" 1 "Barriers" 2 "Guard Rails" 3 "Bridge Abutments" 4 "Edge of Road" 5 "Open Area" ;
VAL_TABLE_ SRRSLRODPB2P_POTk3DynPrpAuth 0 "Has Never Moved" 1 "Has Moved But Currently Stopped" 2 "Moving In Same Direction As Host" 3 "Moving In Opposite Direction As Host" 4 "Crossing Path" ;
VAL_TABLE_ SRRSLRODPB2P_POTk3CnfdStsAuth 0 "Highly Speculative" 1 "Speculative" 2 "Confident" 3 "Highly Confident" ;
VAL_TABLE_ SRRSLRODPB2P_POTk3MStsAuth 0 "No Object" 1 "New Object" 2 "Latent Track Not Detected this Cycle" 3 "Measured this Cycle" ;
VAL_TABLE_ SRRSLRODPB2P_POTk3TypCnfdAuth 0 "Highly Speculative" 1 "Speculative" 2 "Confident" 3 "Highly Confident" ;
VAL_TABLE_ SRRSLRODPB2P_POTk3TypAuth 0 "Unknown" 1 "Pedestrian" 2 "Bicycle" ;
VAL_TABLE_ SRRSLRODPB2P_VOTk2DynPrpStsAuth 0 "Stopped" 1 "Not Stopped" ;
VAL_TABLE_ SRRSLRODPB2P_VOTk2DynPrpAuth 0 "Has Never Moved" 1 "Moving In Same Direction As Host" 2 "Moving In Opposite Direction As Host" 3 "Crossing From Left To Right" 4 "Crossing From Right To Left" ;
VAL_TABLE_ SRRSLRODPB2P_VOTk2CnfdStsAuth 0 "Highly Speculative" 1 "Speculative" 2 "Confident" 3 "Highly Confident" ;
VAL_TABLE_ SRRSLRODPB2P_VOTk2MStsAuth 0 "No Object" 1 "New Object" 2 "Latent Track Not Detected this Cycle" 3 "Measured this Cycle" ;
VAL_TABLE_ SRRSLRODPB2P_VOTk2TypCnfdAuth 0 "Highly Speculative" 1 "Speculative" 2 "Confident" 3 "Highly Confident" ;
VAL_TABLE_ SRRSLRODPB2P_VOTk3CnfdStsAuth 0 "Highly Speculative" 1 "Speculative" 2 "Confident" 3 "Highly Confident" ;
VAL_TABLE_ SRRSLRODPB2P_VOTk3DynPrpStsAuth 0 "Stopped" 1 "Not Stopped" ;
VAL_TABLE_ SRRSLRODPB2P_VOTk3DynPrpAuth 0 "Has Never Moved" 1 "Moving In Same Direction As Host" 2 "Moving In Opposite Direction As Host" 3 "Crossing From Left To Right" 4 "Crossing From Right To Left" ;
VAL_TABLE_ SRRSLRODPB2P_VOTk3MStsAuth 0 "No Object" 1 "New Object" 2 "Latent Track Not Detected this Cycle" 3 "Measured this Cycle" ;
VAL_TABLE_ SRRSLRODPB2P_VOTk3TypCnfdAuth 0 "Highly Speculative" 1 "Speculative" 2 "Confident" 3 "Highly Confident" ;
VAL_TABLE_ SRRSLRODPB2P_VOTk4DynPrpStsAuth 0 "Stopped" 1 "Not Stopped" ;
VAL_TABLE_ SRRSLRODPB2P_VOTk4DynPrpAuth 0 "Has Never Moved" 1 "Moving In Same Direction As Host" 2 "Moving In Opposite Direction As Host" 3 "Crossing From Left To Right" 4 "Crossing From Right To Left" ;
VAL_TABLE_ SRRSLRODPB2P_VOTk4CnfdStsAuth 0 "Highly Speculative" 1 "Speculative" 2 "Confident" 3 "Highly Confident" ;
VAL_TABLE_ SRRSLRODPB2P_VOTk4MStsAuth 0 "No Object" 1 "New Object" 2 "Latent Track Not Detected this Cycle" 3 "Measured this Cycle" ;
VAL_TABLE_ SRRSLRODPB2P_VOTk4TypCnfdAuth 0 "Highly Speculative" 1 "Speculative" 2 "Confident" 3 "Highly Confident" ;
VAL_TABLE_ SRRSLRODPB3P_POTk4DynPrpAuth 0 "Has Never Moved" 1 "Has Moved But Currently Stopped" 2 "Moving In Same Direction As Host" 3 "Moving In Opposite Direction As Host" 4 "Crossing Path" ;
VAL_TABLE_ SRRSLRODPB3P_POTk4CnfdStsAuth 0 "Highly Speculative" 1 "Speculative" 2 "Confident" 3 "Highly Confident" ;
VAL_TABLE_ SRRSLRODPB3P_POTk4MStsAuth 0 "No Object" 1 "New Object" 2 "Latent Track Not Detected this Cycle" 3 "Measured this Cycle" ;
VAL_TABLE_ SRRSLRODPB3P_POTk4TypCnfdAuth 0 "Highly Speculative" 1 "Speculative" 2 "Confident" 3 "Highly Confident" ;
VAL_TABLE_ SRRSLRODPB3P_POTk4TypAuth 0 "Unknown" 1 "Pedestrian" 2 "Bicycle" ;
VAL_TABLE_ SRRSLRODPB3P_VOTk5DynPrpStsAuth 0 "Stopped" 1 "Not Stopped" ;
VAL_TABLE_ SRRSLRODPB3P_VOTk5DynPrpAuth 0 "Has Never Moved" 1 "Moving In Same Direction As Host" 2 "Moving In Opposite Direction As Host" 3 "Crossing From Left To Right" 4 "Crossing From Right To Left" ;
VAL_TABLE_ SRRSLRODPB3P_VOTk5CnfdStsAuth 0 "Highly Speculative" 1 "Speculative" 2 "Confident" 3 "Highly Confident" ;
VAL_TABLE_ SRRSLRODPB3P_VOTk5MStsAuth 0 "No Object" 1 "New Object" 2 "Latent Track Not Detected this Cycle" 3 "Measured this Cycle" ;
VAL_TABLE_ SRRSLRODPB3P_VOTk5TypCnfdAuth 0 "Highly Speculative" 1 "Speculative" 2 "Confident" 3 "Highly Confident" ;
VAL_TABLE_ SRRSLRODPB3P_VOTk6CnfdStsAuth 0 "Highly Speculative" 1 "Speculative" 2 "Confident" 3 "Highly Confident" ;
VAL_TABLE_ SRRSLRODPB3P_VOTk6DynPrpStsAuth 0 "Stopped" 1 "Not Stopped" ;
VAL_TABLE_ SRRSLRODPB3P_VOTk6DynPrpAuth 0 "Has Never Moved" 1 "Moving In Same Direction As Host" 2 "Moving In Opposite Direction As Host" 3 "Crossing From Left To Right" 4 "Crossing From Right To Left" ;
VAL_TABLE_ SRRSLRODPB3P_VOTk6MStsAuth 0 "No Object" 1 "New Object" 2 "Latent Track Not Detected this Cycle" 3 "Measured this Cycle" ;
VAL_TABLE_ SRRSLRODPB3P_VOTk6TypCnfdAuth 0 "Highly Speculative" 1 "Speculative" 2 "Confident" 3 "Highly Confident" ;
VAL_TABLE_ SRRSLRODPB3P_VOTk7DynPrpStsAuth 0 "Stopped" 1 "Not Stopped" ;
VAL_TABLE_ SRRSLRODPB3P_VOTk7DynPrpAuth 0 "Has Never Moved" 1 "Moving In Same Direction As Host" 2 "Moving In Opposite Direction As Host" 3 "Crossing From Left To Right" 4 "Crossing From Right To Left" ;
VAL_TABLE_ SRRSLRODPB3P_VOTk7CnfdStsAuth 0 "Highly Speculative" 1 "Speculative" 2 "Confident" 3 "Highly Confident" ;
VAL_TABLE_ SRRSLRODPB3P_VOTk7MStsAuth 0 "No Object" 1 "New Object" 2 "Latent Track Not Detected this Cycle" 3 "Measured this Cycle" ;
VAL_TABLE_ SRRSLRODPB3P_VOTk7TypCnfdAuth 0 "Highly Speculative" 1 "Speculative" 2 "Confident" 3 "Highly Confident" ;
VAL_TABLE_ SRRSLRODPB4P_POTk5DynPrpAuth 0 "Has Never Moved" 1 "Has Moved But Currently Stopped" 2 "Moving In Same Direction As Host" 3 "Moving In Opposite Direction As Host" 4 "Crossing Path" ;
VAL_TABLE_ SRRSLRODPB4P_POTk5CnfdStsAuth 0 "Highly Speculative" 1 "Speculative" 2 "Confident" 3 "Highly Confident" ;
VAL_TABLE_ SRRSLRODPB4P_POTk5MStsAuth 0 "No Object" 1 "New Object" 2 "Latent Track Not Detected this Cycle" 3 "Measured this Cycle" ;
VAL_TABLE_ SRRSLRODPB4P_POTk5TypCnfdAuth 0 "Highly Speculative" 1 "Speculative" 2 "Confident" 3 "Highly Confident" ;
VAL_TABLE_ SRRSLRODPB4P_POTk5TypAuth 0 "Unknown" 1 "Pedestrian" 2 "Bicycle" ;
VAL_TABLE_ SRRSLRODPB4P_VOTk10DynPrpStAuth 0 "Stopped" 1 "Not Stopped" ;
VAL_TABLE_ SRRSLRODPB4P_VOTk10DynPrpAuth 0 "Has Never Moved" 1 "Moving In Same Direction As Host" 2 "Moving In Opposite Direction As Host" 3 "Crossing From Left To Right" 4 "Crossing From Right To Left" ;
VAL_TABLE_ SRRSLRODPB4P_VOTk10CnfdStsAuth 0 "Highly Speculative" 1 "Speculative" 2 "Confident" 3 "Highly Confident" ;
VAL_TABLE_ SRRSLRODPB4P_VOTk10MStsAuth 0 "No Object" 1 "New Object" 2 "Latent Track Not Detected this Cycle" 3 "Measured this Cycle" ;
VAL_TABLE_ SRRSLRODPB4P_VOTk10TypCnfdAuth 0 "Highly Speculative" 1 "Speculative" 2 "Confident" 3 "Highly Confident" ;
VAL_TABLE_ SRRSLRODPB4P_VOTk8CnfdStsAuth 0 "Highly Speculative" 1 "Speculative" 2 "Confident" 3 "Highly Confident" ;
VAL_TABLE_ SRRSLRODPB4P_VOTk8DynPrpStsAuth 0 "Stopped" 1 "Not Stopped" ;
VAL_TABLE_ SRRSLRODPB4P_VOTk8DynPrpAuth 0 "Has Never Moved" 1 "Moving In Same Direction As Host" 2 "Moving In Opposite Direction As Host" 3 "Crossing From Left To Right" 4 "Crossing From Right To Left" ;
VAL_TABLE_ SRRSLRODPB4P_VOTk8MStsAuth 0 "No Object" 1 "New Object" 2 "Latent Track Not Detected this Cycle" 3 "Measured this Cycle" ;
VAL_TABLE_ SRRSLRODPB4P_VOTk8TypCnfdAuth 0 "Highly Speculative" 1 "Speculative" 2 "Confident" 3 "Highly Confident" ;
VAL_TABLE_ SRRSLRODPB4P_VOTk9DynPrpStsAuth 0 "Stopped" 1 "Not Stopped" ;
VAL_TABLE_ SRRSLRODPB4P_VOTk9DynPrpAuth 0 "Has Never Moved" 1 "Moving In Same Direction As Host" 2 "Moving In Opposite Direction As Host" 3 "Crossing From Left To Right" 4 "Crossing From Right To Left" ;
VAL_TABLE_ SRRSLRODPB4P_VOTk9CnfdStsAuth 0 "Highly Speculative" 1 "Speculative" 2 "Confident" 3 "Highly Confident" ;
VAL_TABLE_ SRRSLRODPB4P_VOTk9MStsAuth 0 "No Object" 1 "New Object" 2 "Latent Track Not Detected this Cycle" 3 "Measured this Cycle" ;
VAL_TABLE_ SRRSLRODPB4P_VOTk9TypCnfdAuth 0 "Highly Speculative" 1 "Speculative" 2 "Confident" 3 "Highly Confident" ;
VAL_TABLE_ SRRSLRODPB5P_IOTk10ElvtnAuth 0 "Not Elevated Elevation" 1 "Speculative Elevation" 2 "Confident Elevation" 3 "Very Confident" ;
VAL_TABLE_ SRRSLRODPB5P_IOTk10CnfdStsAuth 0 "Highly Speculative" 1 "Speculative" 2 "Confident" 3 "Highly Confident" ;
VAL_TABLE_ SRRSLRODPB5P_IOTk10MStsAuth 0 "No Object" 1 "New Object" 2 "Latent Track Not Detected this Cycle" 3 "Measured this Cycle" ;
VAL_TABLE_ SRRSLRODPB5P_IOTk1CnfdStsAuth 0 "Highly Speculative" 1 "Speculative" 2 "Confident" 3 "Highly Confident" ;
VAL_TABLE_ SRRSLRODPB5P_IOTk10TypCnfdAuth 0 "Highly Speculative" 1 "Speculative" 2 "Confident" 3 "Highly Confident" ;
VAL_TABLE_ SRRSLRODPB5P_IOTk10TypAuth 0 "Unknown" 1 "Guard Rail" 2 "Tunnel" 3 "Traffic Sign" 4 "Bridge" 5 "Pole" ;
VAL_TABLE_ SRRSLRODPB5P_IOTk1ElvtnAuth 0 "Not Elevated Elevation" 1 "Speculative Elevation" 2 "Confident Elevation" 3 "Very Confident" ;
VAL_TABLE_ SRRSLRODPB5P_IOTk1MStsAuth 0 "No Object" 1 "New Object" 2 "Latent Track Not Detected this Cycle" 3 "Measured this Cycle" ;
VAL_TABLE_ SRRSLRODPB5P_IOTk1TypAuth 0 "Unknown" 1 "Guard Rail" 2 "Tunnel" 3 "Traffic Sign" 4 "Bridge" 5 "Pole" ;
VAL_TABLE_ SRRSLRODPB5P_IOTk2ElvtnAuth 0 "Not Elevated Elevation" 1 "Speculative Elevation" 2 "Confident Elevation" 3 "Very Confident" ;
VAL_TABLE_ SRRSLRODPB5P_IOTk2CnfdStsAuth 0 "Highly Speculative" 1 "Speculative" 2 "Confident" 3 "Highly Confident" ;
VAL_TABLE_ SRRSLRODPB5P_IOTk1TypCnfdAuth 0 "Highly Speculative" 1 "Speculative" 2 "Confident" 3 "Highly Confident" ;
VAL_TABLE_ SRRSLRODPB5P_IOTk2MStsAuth 0 "No Object" 1 "New Object" 2 "Latent Track Not Detected this Cycle" 3 "Measured this Cycle" ;
VAL_TABLE_ SRRSLRODPB5P_IOTk2TypCnfdAuth 0 "Highly Speculative" 1 "Speculative" 2 "Confident" 3 "Highly Confident" ;
VAL_TABLE_ SRRSLRODPB5P_IOTk2TypAuth 0 "Unknown" 1 "Guard Rail" 2 "Tunnel" 3 "Traffic Sign" 4 "Bridge" 5 "Pole" ;
VAL_TABLE_ SRRSLRODPB5P_IOTk3ElvtnAuth 0 "Not Elevated Elevation" 1 "Speculative Elevation" 2 "Confident Elevation" 3 "Very Confident" ;
VAL_TABLE_ SRRSLRODPB5P_IOTk3CnfdStsAuth 0 "Highly Speculative" 1 "Speculative" 2 "Confident" 3 "Highly Confident" ;
VAL_TABLE_ SRRSLRODPB5P_IOTk3MStsAuth 0 "No Object" 1 "New Object" 2 "Latent Track Not Detected this Cycle" 3 "Measured this Cycle" ;
VAL_TABLE_ SRRSLRODPB5P_IOTk4CnfdStsAuth 0 "Highly Speculative" 1 "Speculative" 2 "Confident" 3 "Highly Confident" ;
VAL_TABLE_ SRRSLRODPB5P_IOTk3TypCnfdAuth 0 "Highly Speculative" 1 "Speculative" 2 "Confident" 3 "Highly Confident" ;
VAL_TABLE_ SRRSLRODPB5P_IOTk3TypAuth 0 "Unknown" 1 "Guard Rail" 2 "Tunnel" 3 "Traffic Sign" 4 "Bridge" 5 "Pole" ;
VAL_TABLE_ SRRSLRODPB5P_IOTk4ElvtnAuth 0 "Not Elevated Elevation" 1 "Speculative Elevation" 2 "Confident Elevation" 3 "Very Confident" ;
VAL_TABLE_ SRRSLRODPB5P_IOTk4MStsAuth 0 "No Object" 1 "New Object" 2 "Latent Track Not Detected this Cycle" 3 "Measured this Cycle" ;
VAL_TABLE_ SRRSLRODPB5P_IOTk4TypAuth 0 "Unknown" 1 "Guard Rail" 2 "Tunnel" 3 "Traffic Sign" 4 "Bridge" 5 "Pole" ;
VAL_TABLE_ SRRSLRODPB5P_IOTk5ElvtnAuth 0 "Not Elevated Elevation" 1 "Speculative Elevation" 2 "Confident Elevation" 3 "Very Confident" ;
VAL_TABLE_ SRRSLRODPB5P_IOTk5CnfdStsAuth 0 "Highly Speculative" 1 "Speculative" 2 "Confident" 3 "Highly Confident" ;
VAL_TABLE_ SRRSLRODPB5P_IOTk4TypCnfdAuth 0 "Highly Speculative" 1 "Speculative" 2 "Confident" 3 "Highly Confident" ;
VAL_TABLE_ SRRSLRODPB5P_IOTk5MStsAuth 0 "No Object" 1 "New Object" 2 "Latent Track Not Detected this Cycle" 3 "Measured this Cycle" ;
VAL_TABLE_ SRRSLRODPB5P_IOTk5TypCnfdAuth 0 "Highly Speculative" 1 "Speculative" 2 "Confident" 3 "Highly Confident" ;
VAL_TABLE_ SRRSLRODPB5P_IOTk5TypAuth 0 "Unknown" 1 "Guard Rail" 2 "Tunnel" 3 "Traffic Sign" 4 "Bridge" 5 "Pole" ;
VAL_TABLE_ SRRSLRODPB5P_IOTk6ElvtnAuth 0 "Not Elevated Elevation" 1 "Speculative Elevation" 2 "Confident Elevation" 3 "Very Confident" ;
VAL_TABLE_ SRRSLRODPB5P_IOTk6CnfdStsAuth 0 "Highly Speculative" 1 "Speculative" 2 "Confident" 3 "Highly Confident" ;
VAL_TABLE_ SRRSLRODPB5P_IOTk6MStsAuth 0 "No Object" 1 "New Object" 2 "Latent Track Not Detected this Cycle" 3 "Measured this Cycle" ;
VAL_TABLE_ SRRSLRODPB5P_IOTk7ElvtnAuth 0 "Not Elevated Elevation" 1 "Speculative Elevation" 2 "Confident Elevation" 3 "Very Confident" ;
VAL_TABLE_ SRRSLRODPB5P_IOTk7CnfdStsAuth 0 "Highly Speculative" 1 "Speculative" 2 "Confident" 3 "Highly Confident" ;
VAL_TABLE_ SRRSLRODPB5P_IOTk6TypCnfdAuth 0 "Highly Speculative" 1 "Speculative" 2 "Confident" 3 "Highly Confident" ;
VAL_TABLE_ SRRSLRODPB5P_IOTk6TypAuth 0 "Unknown" 1 "Guard Rail" 2 "Tunnel" 3 "Traffic Sign" 4 "Bridge" 5 "Pole" ;
VAL_TABLE_ SRRSLRODPB5P_IOTk7MStsAuth 0 "No Object" 1 "New Object" 2 "Latent Track Not Detected this Cycle" 3 "Measured this Cycle" ;
VAL_TABLE_ SRRSLRODPB5P_IOTk7TypAuth 0 "Unknown" 1 "Guard Rail" 2 "Tunnel" 3 "Traffic Sign" 4 "Bridge" 5 "Pole" ;
VAL_TABLE_ SRRSLRODPB5P_IOTk8ElvtnAuth 0 "Not Elevated Elevation" 1 "Speculative Elevation" 2 "Confident Elevation" 3 "Very Confident" ;
VAL_TABLE_ SRRSLRODPB5P_IOTk8CnfdStsAuth 0 "Highly Speculative" 1 "Speculative" 2 "Confident" 3 "Highly Confident" ;
VAL_TABLE_ SRRSLRODPB5P_IOTk7TypCnfdAuth 0 "Highly Speculative" 1 "Speculative" 2 "Confident" 3 "Highly Confident" ;
VAL_TABLE_ SRRSLRODPB5P_IOTk8MStsAuth 0 "No Object" 1 "New Object" 2 "Latent Track Not Detected this Cycle" 3 "Measured this Cycle" ;
VAL_TABLE_ SRRSLRODPB5P_IOTk9CnfdStsAuth 0 "Highly Speculative" 1 "Speculative" 2 "Confident" 3 "Highly Confident" ;
VAL_TABLE_ SRRSLRODPB5P_IOTk8TypCnfdAuth 0 "Highly Speculative" 1 "Speculative" 2 "Confident" 3 "Highly Confident" ;
VAL_TABLE_ SRRSLRODPB5P_IOTk8TypAuth 0 "Unknown" 1 "Guard Rail" 2 "Tunnel" 3 "Traffic Sign" 4 "Bridge" 5 "Pole" ;
VAL_TABLE_ SRRSLRODPB5P_IOTk9ElvtnAuth 0 "Not Elevated Elevation" 1 "Speculative Elevation" 2 "Confident Elevation" 3 "Very Confident" ;
VAL_TABLE_ SRRSLRODPB5P_IOTk9MStsAuth 0 "No Object" 1 "New Object" 2 "Latent Track Not Detected this Cycle" 3 "Measured this Cycle" ;
VAL_TABLE_ SRRSLRODPB5P_IOTk9TypAuth 0 "Unknown" 1 "Guard Rail" 2 "Tunnel" 3 "Traffic Sign" 4 "Bridge" 5 "Pole" ;
VAL_TABLE_ SRRSLRODPB5P_IOTk9TypCnfdAuth 0 "Highly Speculative" 1 "Speculative" 2 "Confident" 3 "Highly Confident" ;
VAL_TABLE_ SRRSLRODPB1P_CnstrArDtnCnfdAuth 0 "Highly Speculative" 1 "Speculative" 2 "Confident" 3 "Highly Confident" ;
VAL_TABLE_ SRRSLRODPB1P_AcqTmStmAuth_Inv 0 "FALSE" 1 "TRUE" ;
VAL_TABLE_ SRRSLRODPB1P_POTk1DynPrpAuth 0 "Has Never Moved" 1 "Has Moved But Currently Stopped" 2 "Moving In Same Direction As Host" 3 "Moving In Opposite Direction As Host" 4 "Crossing Path" ;
VAL_TABLE_ SRRSLRODPB1P_POTk1CnfdStsAuth 0 "Highly Speculative" 1 "Speculative" 2 "Confident" 3 "Highly Confident" ;
VAL_TABLE_ SRRSLRODPB1P_MdCmdStsAuth 0 "Not Radiating" 1 "Reporting Object Data" 2 "Not Reporting Object Data" ;
VAL_TABLE_ SRRSLRODPB1P_CnstrArDtnStsAuth 0 "Not Detected" 1 "Detected" 2 "Unknown" ;
VAL_TABLE_ SRRSLRODPB1P_POTk1MStsAuth 0 "No Object" 1 "New Object" 2 "Latent Track Not Detected this Cycle" 3 "Measured this Cycle" ;
VAL_TABLE_ SRRSLRODPB1P_POTk2CnfdStsAuth 0 "Highly Speculative" 1 "Speculative" 2 "Confident" 3 "Highly Confident" ;
VAL_TABLE_ SRRSLRODPB1P_POTk1TypCnfdAuth 0 "Highly Speculative" 1 "Speculative" 2 "Confident" 3 "Highly Confident" ;
VAL_TABLE_ SRRSLRODPB1P_POTk1TypAuth 0 "Unknown" 1 "Pedestrian" 2 "Bicycle" ;
VAL_TABLE_ SRRSLRODPB1P_POTk2DynPrpAuth 0 "Has Never Moved" 1 "Has Moved But Currently Stopped" 2 "Moving In Same Direction As Host" 3 "Moving In Opposite Direction As Host" 4 "Crossing Path" ;
VAL_TABLE_ SRRSLRODPB1P_POTk2MStsAuth 0 "No Object" 1 "New Object" 2 "Latent Track Not Detected this Cycle" 3 "Measured this Cycle" ;
VAL_TABLE_ SRRSLRODPB1P_POTk2TypCnfdAuth 0 "Highly Speculative" 1 "Speculative" 2 "Confident" 3 "Highly Confident" ;
VAL_TABLE_ SRRSLRODPB1P_POTk2TypAuth 0 "Unknown" 1 "Pedestrian" 2 "Bicycle" ;
VAL_TABLE_ SRRSLRODPB1P_SnsrUnvAuth 0 "FALSE" 1 "TRUE" ;
VAL_TABLE_ SRRSLRODPB1P_SnsrBlckdAuth 0 "FALSE" 1 "TRUE" ;
VAL_TABLE_ SRRSLRODPB1P_ServRqrdAuth 0 "FALSE" 1 "TRUE" ;
VAL_TABLE_ SRRSLRODPB1P_RdTypCnfdAuth 0 "Highly Speculative" 1 "Speculative" 2 "Confident" 3 "Highly Confident" ;
VAL_TABLE_ SRRSLRODPB1P_RdTypAuth 0 "Unknown" 1 "City" 2 "Secondary Road" 3 "Highway" 4 "Construction" 5 "Zone Entry" 6 "Construction" 7 "Zone Exit" ;
VAL_TABLE_ SRRSLRODPB1P_SwpBndwdthStsAuth 0 "Mode A" 1 "Mode B" 2 "Mode C" 3 "Mode D" ;
VAL_TABLE_ SRRSLRODPB1P_VOTk1DynPrpStsAuth 0 "Stopped" 1 "Not Stopped" ;
VAL_TABLE_ SRRSLRODPB1P_VOTk1DynPrpAuth 0 "Has Never Moved" 1 "Moving In Same Direction As Host" 2 "Moving In Opposite Direction As Host" 3 "Crossing From Left To Right" 4 "Crossing From Right To Left" ;
VAL_TABLE_ SRRSLRODPB1P_VOTk1CnfdStsAuth 0 "Highly Speculative" 1 "Speculative" 2 "Confident" 3 "Highly Confident" ;
VAL_TABLE_ SRRSLRODPB1P_VOTk1MStsAuth 0 "No Object" 1 "New Object" 2 "Latent Track Not Detected this Cycle" 3 "Measured this Cycle" ;
VAL_TABLE_ SRRSLRODPB1P_VOTk1TypCnfdAuth 0 "Highly Speculative" 1 "Speculative" 2 "Confident" 3 "Highly Confident" ;
VAL_TABLE_ SRRSLRODPB6P_REOTk1CnfdStsAuth 0 "Highly Speculative" 1 "Speculative" 2 "Confident" 3 "Highly Confident" ;
VAL_TABLE_ SRRSLRODPB6P_REOTk2CnfdStsAuth 0 "Highly Speculative" 1 "Speculative" 2 "Confident" 3 "Highly Confident" ;
VAL_TABLE_ SRRSLRODPB6P_REOTk1TypCnfdAuth 0 "Highly Speculative" 1 "Speculative" 2 "Confident" 3 "Highly Confident" ;
VAL_TABLE_ SRRSLRODPB6P_REOTk1TypAuth 0 "Unknown" 1 "Barriers" 2 "Guard Rails" 3 "Bridge Abutments" 4 "Edge of Road" 5 "Open Area" ;
VAL_TABLE_ SRRSLRODPB6P_REOTk3CnfdStsAuth 0 "Highly Speculative" 1 "Speculative" 2 "Confident" 3 "Highly Confident" ;
VAL_TABLE_ SRRSLRODPB6P_REOTk2TypCnfdAuth 0 "Highly Speculative" 1 "Speculative" 2 "Confident" 3 "Highly Confident" ;
VAL_TABLE_ SRRSLRODPB6P_REOTk2TypAuth 0 "Unknown" 1 "Barriers" 2 "Guard Rails" 3 "Bridge Abutments" 4 "Edge of Road" 5 "Open Area" ;
VAL_TABLE_ SRRSLRODPB6P_REOTk3TypCnfdAuth 0 "Highly Speculative" 1 "Speculative" 2 "Confident" 3 "Highly Confident" ;
VAL_TABLE_ SRRSLRODPB6P_REOTk3TypAuth 0 "Unknown" 1 "Barriers" 2 "Guard Rails" 3 "Bridge Abutments" 4 "Edge of Road" 5 "Open Area" ;
VAL_TABLE_ SRRSRRODPB2P_POTk3DynPrpAuth 0 "Has Never Moved" 1 "Has Moved But Currently Stopped" 2 "Moving In Same Direction As Host" 3 "Moving In Opposite Direction As Host" 4 "Crossing Path" ;
VAL_TABLE_ SRRSRRODPB2P_POTk3CnfdStsAuth 0 "Highly Speculative" 1 "Speculative" 2 "Confident" 3 "Highly Confident" ;
VAL_TABLE_ SRRSRRODPB2P_POTk3MStsAuth 0 "No Object" 1 "New Object" 2 "Latent Track Not Detected this Cycle" 3 "Measured this Cycle" ;
VAL_TABLE_ SRRSRRODPB2P_POTk3TypCnfdAuth 0 "Highly Speculative" 1 "Speculative" 2 "Confident" 3 "Highly Confident" ;
VAL_TABLE_ SRRSRRODPB2P_POTk3TypAuth 0 "Unknown" 1 "Pedestrian" 2 "Bicycle" ;
VAL_TABLE_ SRRSRRODPB2P_VOTk2DynPrpStsAuth 0 "Stopped" 1 "Not Stopped" ;
VAL_TABLE_ SRRSRRODPB2P_VOTk2DynPrpAuth 0 "Has Never Moved" 1 "Moving In Same Direction As Host" 2 "Moving In Opposite Direction As Host" 3 "Crossing From Left To Right" 4 "Crossing From Right To Left" ;
VAL_TABLE_ SRRSRRODPB2P_VOTk2CnfdStsAuth 0 "Highly Speculative" 1 "Speculative" 2 "Confident" 3 "Highly Confident" ;
VAL_TABLE_ SRRSRRODPB2P_VOTk2MStsAuth 0 "No Object" 1 "New Object" 2 "Latent Track Not Detected this Cycle" 3 "Measured this Cycle" ;
VAL_TABLE_ SRRSRRODPB2P_VOTk2TypCnfdAuth 0 "Highly Speculative" 1 "Speculative" 2 "Confident" 3 "Highly Confident" ;
VAL_TABLE_ SRRSRRODPB2P_VOTk3CnfdStsAuth 0 "Highly Speculative" 1 "Speculative" 2 "Confident" 3 "Highly Confident" ;
VAL_TABLE_ SRRSRRODPB2P_VOTk3DynPrpStsAuth 0 "Stopped" 1 "Not Stopped" ;
VAL_TABLE_ SRRSRRODPB2P_VOTk3DynPrpAuth 0 "Has Never Moved" 1 "Moving In Same Direction As Host" 2 "Moving In Opposite Direction As Host" 3 "Crossing From Left To Right" 4 "Crossing From Right To Left" ;
VAL_TABLE_ SRRSRRODPB2P_VOTk3MStsAuth 0 "No Object" 1 "New Object" 2 "Latent Track Not Detected this Cycle" 3 "Measured this Cycle" ;
VAL_TABLE_ SRRSRRODPB2P_VOTk3TypCnfdAuth 0 "Highly Speculative" 1 "Speculative" 2 "Confident" 3 "Highly Confident" ;
VAL_TABLE_ SRRSRRODPB2P_VOTk4DynPrpStsAuth 0 "Stopped" 1 "Not Stopped" ;
VAL_TABLE_ SRRSRRODPB2P_VOTk4DynPrpAuth 0 "Has Never Moved" 1 "Moving In Same Direction As Host" 2 "Moving In Opposite Direction As Host" 3 "Crossing From Left To Right" 4 "Crossing From Right To Left" ;
VAL_TABLE_ SRRSRRODPB2P_VOTk4CnfdStsAuth 0 "Highly Speculative" 1 "Speculative" 2 "Confident" 3 "Highly Confident" ;
VAL_TABLE_ SRRSRRODPB2P_VOTk4MStsAuth 0 "No Object" 1 "New Object" 2 "Latent Track Not Detected this Cycle" 3 "Measured this Cycle" ;
VAL_TABLE_ SRRSRRODPB2P_VOTk4TypCnfdAuth 0 "Highly Speculative" 1 "Speculative" 2 "Confident" 3 "Highly Confident" ;
VAL_TABLE_ SRRSRRODPB3P_POTk4DynPrpAuth 0 "Has Never Moved" 1 "Has Moved But Currently Stopped" 2 "Moving In Same Direction As Host" 3 "Moving In Opposite Direction As Host" 4 "Crossing Path" ;
VAL_TABLE_ SRRSRRODPB3P_POTk4CnfdStsAuth 0 "Highly Speculative" 1 "Speculative" 2 "Confident" 3 "Highly Confident" ;
VAL_TABLE_ SRRSRRODPB3P_POTk4MStsAuth 0 "No Object" 1 "New Object" 2 "Latent Track Not Detected this Cycle" 3 "Measured this Cycle" ;
VAL_TABLE_ SRRSRRODPB3P_POTk4TypCnfdAuth 0 "Highly Speculative" 1 "Speculative" 2 "Confident" 3 "Highly Confident" ;
VAL_TABLE_ SRRSRRODPB3P_POTk4TypAuth 0 "Unknown" 1 "Pedestrian" 2 "Bicycle" ;
VAL_TABLE_ SRRSRRODPB3P_VOTk5DynPrpStsAuth 0 "Stopped" 1 "Not Stopped" ;
VAL_TABLE_ SRRSRRODPB3P_VOTk5DynPrpAuth 0 "Has Never Moved" 1 "Moving In Same Direction As Host" 2 "Moving In Opposite Direction As Host" 3 "Crossing From Left To Right" 4 "Crossing From Right To Left" ;
VAL_TABLE_ SRRSRRODPB3P_VOTk5CnfdStsAuth 0 "Highly Speculative" 1 "Speculative" 2 "Confident" 3 "Highly Confident" ;
VAL_TABLE_ SRRSRRODPB3P_VOTk5MStsAuth 0 "No Object" 1 "New Object" 2 "Latent Track Not Detected this Cycle" 3 "Measured this Cycle" ;
VAL_TABLE_ SRRSRRODPB3P_VOTk5TypCnfdAuth 0 "Highly Speculative" 1 "Speculative" 2 "Confident" 3 "Highly Confident" ;
VAL_TABLE_ SRRSRRODPB3P_VOTk6CnfdStsAuth 0 "Highly Speculative" 1 "Speculative" 2 "Confident" 3 "Highly Confident" ;
VAL_TABLE_ SRRSRRODPB3P_VOTk6DynPrpStsAuth 0 "Stopped" 1 "Not Stopped" ;
VAL_TABLE_ SRRSRRODPB3P_VOTk6DynPrpAuth 0 "Has Never Moved" 1 "Moving In Same Direction As Host" 2 "Moving In Opposite Direction As Host" 3 "Crossing From Left To Right" 4 "Crossing From Right To Left" ;
VAL_TABLE_ SRRSRRODPB3P_VOTk6MStsAuth 0 "No Object" 1 "New Object" 2 "Latent Track Not Detected this Cycle" 3 "Measured this Cycle" ;
VAL_TABLE_ SRRSRRODPB3P_VOTk6TypCnfdAuth 0 "Highly Speculative" 1 "Speculative" 2 "Confident" 3 "Highly Confident" ;
VAL_TABLE_ SRRSRRODPB3P_VOTk7DynPrpStsAuth 0 "Stopped" 1 "Not Stopped" ;
VAL_TABLE_ SRRSRRODPB3P_VOTk7DynPrpAuth 0 "Has Never Moved" 1 "Moving In Same Direction As Host" 2 "Moving In Opposite Direction As Host" 3 "Crossing From Left To Right" 4 "Crossing From Right To Left" ;
VAL_TABLE_ SRRSRRODPB3P_VOTk7CnfdStsAuth 0 "Highly Speculative" 1 "Speculative" 2 "Confident" 3 "Highly Confident" ;
VAL_TABLE_ SRRSRRODPB3P_VOTk7MStsAuth 0 "No Object" 1 "New Object" 2 "Latent Track Not Detected this Cycle" 3 "Measured this Cycle" ;
VAL_TABLE_ SRRSRRODPB3P_VOTk7TypCnfdAuth 0 "Highly Speculative" 1 "Speculative" 2 "Confident" 3 "Highly Confident" ;
VAL_TABLE_ SRRSRRODPB4P_POTk5DynPrpAuth 0 "Has Never Moved" 1 "Has Moved But Currently Stopped" 2 "Moving In Same Direction As Host" 3 "Moving In Opposite Direction As Host" 4 "Crossing Path" ;
VAL_TABLE_ SRRSRRODPB4P_POTk5CnfdStsAuth 0 "Highly Speculative" 1 "Speculative" 2 "Confident" 3 "Highly Confident" ;
VAL_TABLE_ SRRSRRODPB4P_POTk5MStsAuth 0 "No Object" 1 "New Object" 2 "Latent Track Not Detected this Cycle" 3 "Measured this Cycle" ;
VAL_TABLE_ SRRSRRODPB4P_POTk5TypCnfdAuth 0 "Highly Speculative" 1 "Speculative" 2 "Confident" 3 "Highly Confident" ;
VAL_TABLE_ SRRSRRODPB4P_POTk5TypAuth 0 "Unknown" 1 "Pedestrian" 2 "Bicycle" ;
VAL_TABLE_ SRRSRRODPB4P_VOTk10DynPrpStAuth 0 "Stopped" 1 "Not Stopped" ;
VAL_TABLE_ SRRSRRODPB4P_VOTk10DynPrpAuth 0 "Has Never Moved" 1 "Moving In Same Direction As Host" 2 "Moving In Opposite Direction As Host" 3 "Crossing From Left To Right" 4 "Crossing From Right To Left" ;
VAL_TABLE_ SRRSRRODPB4P_VOTk10CnfdStsAuth 0 "Highly Speculative" 1 "Speculative" 2 "Confident" 3 "Highly Confident" ;
VAL_TABLE_ SRRSRRODPB4P_VOTk10MStsAuth 0 "No Object" 1 "New Object" 2 "Latent Track Not Detected this Cycle" 3 "Measured this Cycle" ;
VAL_TABLE_ SRRSRRODPB4P_VOTk10TypCnfdAuth 0 "Highly Speculative" 1 "Speculative" 2 "Confident" 3 "Highly Confident" ;
VAL_TABLE_ SRRSRRODPB4P_VOTk8CnfdStsAuth 0 "Highly Speculative" 1 "Speculative" 2 "Confident" 3 "Highly Confident" ;
VAL_TABLE_ SRRSRRODPB4P_VOTk8DynPrpStsAuth 0 "Stopped" 1 "Not Stopped" ;
VAL_TABLE_ SRRSRRODPB4P_VOTk8DynPrpAuth 0 "Has Never Moved" 1 "Moving In Same Direction As Host" 2 "Moving In Opposite Direction As Host" 3 "Crossing From Left To Right" 4 "Crossing From Right To Left" ;
VAL_TABLE_ SRRSRRODPB4P_VOTk8MStsAuth 0 "No Object" 1 "New Object" 2 "Latent Track Not Detected this Cycle" 3 "Measured this Cycle" ;
VAL_TABLE_ SRRSRRODPB4P_VOTk8TypCnfdAuth 0 "Highly Speculative" 1 "Speculative" 2 "Confident" 3 "Highly Confident" ;
VAL_TABLE_ SRRSRRODPB4P_VOTk9DynPrpStsAuth 0 "Stopped" 1 "Not Stopped" ;
VAL_TABLE_ SRRSRRODPB4P_VOTk9DynPrpAuth 0 "Has Never Moved" 1 "Moving In Same Direction As Host" 2 "Moving In Opposite Direction As Host" 3 "Crossing From Left To Right" 4 "Crossing From Right To Left" ;
VAL_TABLE_ SRRSRRODPB4P_VOTk9CnfdStsAuth 0 "Highly Speculative" 1 "Speculative" 2 "Confident" 3 "Highly Confident" ;
VAL_TABLE_ SRRSRRODPB4P_VOTk9MStsAuth 0 "No Object" 1 "New Object" 2 "Latent Track Not Detected this Cycle" 3 "Measured this Cycle" ;
VAL_TABLE_ SRRSRRODPB4P_VOTk9TypCnfdAuth 0 "Highly Speculative" 1 "Speculative" 2 "Confident" 3 "Highly Confident" ;
VAL_TABLE_ SRRSRRODPB5P_IOTk10ElvtnAuth 0 "Not Elevated Elevation" 1 "Speculative Elevation" 2 "Confident Elevation" 3 "Very Confident" ;
VAL_TABLE_ SRRSRRODPB5P_IOTk10CnfdStsAuth 0 "Highly Speculative" 1 "Speculative" 2 "Confident" 3 "Highly Confident" ;
VAL_TABLE_ SRRSRRODPB5P_IOTk10MStsAuth 0 "No Object" 1 "New Object" 2 "Latent Track Not Detected this Cycle" 3 "Measured this Cycle" ;
VAL_TABLE_ SRRSRRODPB5P_IOTk1CnfdStsAuth 0 "Highly Speculative" 1 "Speculative" 2 "Confident" 3 "Highly Confident" ;
VAL_TABLE_ SRRSRRODPB5P_IOTk10TypCnfdAuth 0 "Highly Speculative" 1 "Speculative" 2 "Confident" 3 "Highly Confident" ;
VAL_TABLE_ SRRSRRODPB5P_IOTk10TypAuth 0 "Unknown" 1 "Guard Rail" 2 "Tunnel" 3 "Traffic Sign" 4 "Bridge" 5 "Pole" ;
VAL_TABLE_ SRRSRRODPB5P_IOTk1ElvtnAuth 0 "Not Elevated Elevation" 1 "Speculative Elevation" 2 "Confident Elevation" 3 "Very Confident" ;
VAL_TABLE_ SRRSRRODPB5P_IOTk1MStsAuth 0 "No Object" 1 "New Object" 2 "Latent Track Not Detected this Cycle" 3 "Measured this Cycle" ;
VAL_TABLE_ SRRSRRODPB5P_IOTk1TypAuth 0 "Unknown" 1 "Guard Rail" 2 "Tunnel" 3 "Traffic Sign" 4 "Bridge" 5 "Pole" ;
VAL_TABLE_ SRRSRRODPB5P_IOTk2ElvtnAuth 0 "Not Elevated Elevation" 1 "Speculative Elevation" 2 "Confident Elevation" 3 "Very Confident" ;
VAL_TABLE_ SRRSRRODPB5P_IOTk2CnfdStsAuth 0 "Highly Speculative" 1 "Speculative" 2 "Confident" 3 "Highly Confident" ;
VAL_TABLE_ SRRSRRODPB5P_IOTk1TypCnfdAuth 0 "Highly Speculative" 1 "Speculative" 2 "Confident" 3 "Highly Confident" ;
VAL_TABLE_ SRRSRRODPB5P_IOTk2MStsAuth 0 "No Object" 1 "New Object" 2 "Latent Track Not Detected this Cycle" 3 "Measured this Cycle" ;
VAL_TABLE_ SRRSRRODPB5P_IOTk2TypCnfdAuth 0 "Highly Speculative" 1 "Speculative" 2 "Confident" 3 "Highly Confident" ;
VAL_TABLE_ SRRSRRODPB5P_IOTk2TypAuth 0 "Unknown" 1 "Guard Rail" 2 "Tunnel" 3 "Traffic Sign" 4 "Bridge" 5 "Pole" ;
VAL_TABLE_ SRRSRRODPB5P_IOTk3ElvtnAuth 0 "Not Elevated Elevation" 1 "Speculative Elevation" 2 "Confident Elevation" 3 "Very Confident" ;
VAL_TABLE_ SRRSRRODPB5P_IOTk3CnfdStsAuth 0 "Highly Speculative" 1 "Speculative" 2 "Confident" 3 "Highly Confident" ;
VAL_TABLE_ SRRSRRODPB5P_IOTk3MStsAuth 0 "No Object" 1 "New Object" 2 "Latent Track Not Detected this Cycle" 3 "Measured this Cycle" ;
VAL_TABLE_ SRRSRRODPB5P_IOTk4CnfdStsAuth 0 "Highly Speculative" 1 "Speculative" 2 "Confident" 3 "Highly Confident" ;
VAL_TABLE_ SRRSRRODPB5P_IOTk3TypCnfdAuth 0 "Highly Speculative" 1 "Speculative" 2 "Confident" 3 "Highly Confident" ;
VAL_TABLE_ SRRSRRODPB5P_IOTk3TypAuth 0 "Unknown" 1 "Guard Rail" 2 "Tunnel" 3 "Traffic Sign" 4 "Bridge" 5 "Pole" ;
VAL_TABLE_ SRRSRRODPB5P_IOTk4ElvtnAuth 0 "Not Elevated Elevation" 1 "Speculative Elevation" 2 "Confident Elevation" 3 "Very Confident" ;
VAL_TABLE_ SRRSRRODPB5P_IOTk4MStsAuth 0 "No Object" 1 "New Object" 2 "Latent Track Not Detected this Cycle" 3 "Measured this Cycle" ;
VAL_TABLE_ SRRSRRODPB5P_IOTk4TypAuth 0 "Unknown" 1 "Guard Rail" 2 "Tunnel" 3 "Traffic Sign" 4 "Bridge" 5 "Pole" ;
VAL_TABLE_ SRRSRRODPB5P_IOTk5ElvtnAuth 0 "Not Elevated Elevation" 1 "Speculative Elevation" 2 "Confident Elevation" 3 "Very Confident" ;
VAL_TABLE_ SRRSRRODPB5P_IOTk5CnfdStsAuth 0 "Highly Speculative" 1 "Speculative" 2 "Confident" 3 "Highly Confident" ;
VAL_TABLE_ SRRSRRODPB5P_IOTk4TypCnfdAuth 0 "Highly Speculative" 1 "Speculative" 2 "Confident" 3 "Highly Confident" ;
VAL_TABLE_ SRRSRRODPB5P_IOTk5MStsAuth 0 "No Object" 1 "New Object" 2 "Latent Track Not Detected this Cycle" 3 "Measured this Cycle" ;
VAL_TABLE_ SRRSRRODPB5P_IOTk5TypCnfdAuth 0 "Highly Speculative" 1 "Speculative" 2 "Confident" 3 "Highly Confident" ;
VAL_TABLE_ SRRSRRODPB5P_IOTk5TypAuth 0 "Unknown" 1 "Guard Rail" 2 "Tunnel" 3 "Traffic Sign" 4 "Bridge" 5 "Pole" ;
VAL_TABLE_ SRRSRRODPB5P_IOTk6ElvtnAuth 0 "Not Elevated Elevation" 1 "Speculative Elevation" 2 "Confident Elevation" 3 "Very Confident" ;
VAL_TABLE_ SRRSRRODPB5P_IOTk6CnfdStsAuth 0 "Highly Speculative" 1 "Speculative" 2 "Confident" 3 "Highly Confident" ;
VAL_TABLE_ SRRSRRODPB5P_IOTk6MStsAuth 0 "No Object" 1 "New Object" 2 "Latent Track Not Detected this Cycle" 3 "Measured this Cycle" ;
VAL_TABLE_ SRRSRRODPB5P_IOTk7ElvtnAuth 0 "Not Elevated Elevation" 1 "Speculative Elevation" 2 "Confident Elevation" 3 "Very Confident" ;
VAL_TABLE_ SRRSRRODPB5P_IOTk7CnfdStsAuth 0 "Highly Speculative" 1 "Speculative" 2 "Confident" 3 "Highly Confident" ;
VAL_TABLE_ SRRSRRODPB5P_IOTk6TypCnfdAuth 0 "Highly Speculative" 1 "Speculative" 2 "Confident" 3 "Highly Confident" ;
VAL_TABLE_ SRRSRRODPB5P_IOTk6TypAuth 0 "Unknown" 1 "Guard Rail" 2 "Tunnel" 3 "Traffic Sign" 4 "Bridge" 5 "Pole" ;
VAL_TABLE_ SRRSRRODPB5P_IOTk7MStsAuth 0 "No Object" 1 "New Object" 2 "Latent Track Not Detected this Cycle" 3 "Measured this Cycle" ;
VAL_TABLE_ SRRSRRODPB5P_IOTk7TypAuth 0 "Unknown" 1 "Guard Rail" 2 "Tunnel" 3 "Traffic Sign" 4 "Bridge" 5 "Pole" ;
VAL_TABLE_ SRRSRRODPB5P_IOTk8ElvtnAuth 0 "Not Elevated Elevation" 1 "Speculative Elevation" 2 "Confident Elevation" 3 "Very Confident" ;
VAL_TABLE_ SRRSRRODPB5P_IOTk8CnfdStsAuth 0 "Highly Speculative" 1 "Speculative" 2 "Confident" 3 "Highly Confident" ;
VAL_TABLE_ SRRSRRODPB5P_IOTk7TypCnfdAuth 0 "Highly Speculative" 1 "Speculative" 2 "Confident" 3 "Highly Confident" ;
VAL_TABLE_ SRRSRRODPB5P_IOTk8MStsAuth 0 "No Object" 1 "New Object" 2 "Latent Track Not Detected this Cycle" 3 "Measured this Cycle" ;
VAL_TABLE_ SRRSRRODPB5P_IOTk9CnfdStsAuth 0 "Highly Speculative" 1 "Speculative" 2 "Confident" 3 "Highly Confident" ;
VAL_TABLE_ SRRSRRODPB5P_IOTk8TypCnfdAuth 0 "Highly Speculative" 1 "Speculative" 2 "Confident" 3 "Highly Confident" ;
VAL_TABLE_ SRRSRRODPB5P_IOTk8TypAuth 0 "Unknown" 1 "Guard Rail" 2 "Tunnel" 3 "Traffic Sign" 4 "Bridge" 5 "Pole" ;
VAL_TABLE_ SRRSRRODPB5P_IOTk9ElvtnAuth 0 "Not Elevated Elevation" 1 "Speculative Elevation" 2 "Confident Elevation" 3 "Very Confident" ;
VAL_TABLE_ SRRSRRODPB5P_IOTk9MStsAuth 0 "No Object" 1 "New Object" 2 "Latent Track Not Detected this Cycle" 3 "Measured this Cycle" ;
VAL_TABLE_ SRRSRRODPB5P_IOTk9TypAuth 0 "Unknown" 1 "Guard Rail" 2 "Tunnel" 3 "Traffic Sign" 4 "Bridge" 5 "Pole" ;
VAL_TABLE_ SRRSRRODPB5P_IOTk9TypCnfdAuth 0 "Highly Speculative" 1 "Speculative" 2 "Confident" 3 "Highly Confident" ;
VAL_TABLE_ SRRSRRODPB1P_CnstrArDtnCnfdAuth 0 "Highly Speculative" 1 "Speculative" 2 "Confident" 3 "Highly Confident" ;
VAL_TABLE_ SRRSRRODPB1P_AcqTmStmAuth_Inv 0 "FALSE" 1 "TRUE" ;
VAL_TABLE_ SRRSRRODPB1P_POTk1DynPrpAuth 0 "Has Never Moved" 1 "Has Moved But Currently Stopped" 2 "Moving In Same Direction As Host" 3 "Moving In Opposite Direction As Host" 4 "Crossing Path" ;
VAL_TABLE_ SRRSRRODPB1P_POTk1CnfdStsAuth 0 "Highly Speculative" 1 "Speculative" 2 "Confident" 3 "Highly Confident" ;
VAL_TABLE_ SRRSRRODPB1P_MdCmdStsAuth 0 "Not Radiating" 1 "Reporting Object Data" 2 "Not Reporting Object Data" ;
VAL_TABLE_ SRRSRRODPB1P_CnstrArDtnStsAuth 0 "Not Detected" 1 "Detected" 2 "Unknown" ;
VAL_TABLE_ SRRSRRODPB1P_POTk1MStsAuth 0 "No Object" 1 "New Object" 2 "Latent Track Not Detected this Cycle" 3 "Measured this Cycle" ;
VAL_TABLE_ SRRSRRODPB1P_POTk2CnfdStsAuth 0 "Highly Speculative" 1 "Speculative" 2 "Confident" 3 "Highly Confident" ;
VAL_TABLE_ SRRSRRODPB1P_POTk1TypCnfdAuth 0 "Highly Speculative" 1 "Speculative" 2 "Confident" 3 "Highly Confident" ;
VAL_TABLE_ SRRSRRODPB1P_POTk1TypAuth 0 "Unknown" 1 "Pedestrian" 2 "Bicycle" ;
VAL_TABLE_ SRRSRRODPB1P_POTk2DynPrpAuth 0 "Has Never Moved" 1 "Has Moved But Currently Stopped" 2 "Moving In Same Direction As Host" 3 "Moving In Opposite Direction As Host" 4 "Crossing Path" ;
VAL_TABLE_ SRRSRRODPB1P_POTk2MStsAuth 0 "No Object" 1 "New Object" 2 "Latent Track Not Detected this Cycle" 3 "Measured this Cycle" ;
VAL_TABLE_ SRRSRRODPB1P_POTk2TypCnfdAuth 0 "Highly Speculative" 1 "Speculative" 2 "Confident" 3 "Highly Confident" ;
VAL_TABLE_ SRRSRRODPB1P_POTk2TypAuth 0 "Unknown" 1 "Pedestrian" 2 "Bicycle" ;
VAL_TABLE_ SRRSRRODPB1P_SnsrUnvAuth 0 "FALSE" 1 "TRUE" ;
VAL_TABLE_ SRRSRRODPB1P_SnsrBlckdAuth 0 "FALSE" 1 "TRUE" ;
VAL_TABLE_ SRRSRRODPB1P_ServRqrdAuth 0 "FALSE" 1 "TRUE" ;
VAL_TABLE_ SRRSRRODPB1P_RdTypCnfdAuth 0 "Highly Speculative" 1 "Speculative" 2 "Confident" 3 "Highly Confident" ;
VAL_TABLE_ SRRSRRODPB1P_RdTypAuth 0 "Unknown" 1 "City" 2 "Secondary Road" 3 "Highway" 4 "Construction" 5 "Zone Entry" 6 "Construction" 7 "Zone Exit" ;
VAL_TABLE_ SRRSRRODPB1P_SwpBndwdthStsAuth 0 "Mode A" 1 "Mode B" 2 "Mode C" 3 "Mode D" ;
VAL_TABLE_ SRRSRRODPB1P_VOTk1DynPrpStsAuth 0 "Stopped" 1 "Not Stopped" ;
VAL_TABLE_ SRRSRRODPB1P_VOTk1DynPrpAuth 0 "Has Never Moved" 1 "Moving In Same Direction As Host" 2 "Moving In Opposite Direction As Host" 3 "Crossing From Left To Right" 4 "Crossing From Right To Left" ;
VAL_TABLE_ SRRSRRODPB1P_VOTk1CnfdStsAuth 0 "Highly Speculative" 1 "Speculative" 2 "Confident" 3 "Highly Confident" ;
VAL_TABLE_ SRRSRRODPB1P_VOTk1MStsAuth 0 "No Object" 1 "New Object" 2 "Latent Track Not Detected this Cycle" 3 "Measured this Cycle" ;
VAL_TABLE_ SRRSRRODPB1P_VOTk1TypCnfdAuth 0 "Highly Speculative" 1 "Speculative" 2 "Confident" 3 "Highly Confident" ;
VAL_TABLE_ SRRSRRODPB6P_REOTk1CnfdStsAuth 0 "Highly Speculative" 1 "Speculative" 2 "Confident" 3 "Highly Confident" ;
VAL_TABLE_ SRRSRRODPB6P_REOTk2CnfdStsAuth 0 "Highly Speculative" 1 "Speculative" 2 "Confident" 3 "Highly Confident" ;
VAL_TABLE_ SRRSRRODPB6P_REOTk1TypCnfdAuth 0 "Highly Speculative" 1 "Speculative" 2 "Confident" 3 "Highly Confident" ;
VAL_TABLE_ SRRSRRODPB6P_REOTk1TypAuth 0 "Unknown" 1 "Barriers" 2 "Guard Rails" 3 "Bridge Abutments" 4 "Edge of Road" 5 "Open Area" ;
VAL_TABLE_ SRRSRRODPB6P_REOTk3CnfdStsAuth 0 "Highly Speculative" 1 "Speculative" 2 "Confident" 3 "Highly Confident" ;
VAL_TABLE_ SRRSRRODPB6P_REOTk2TypCnfdAuth 0 "Highly Speculative" 1 "Speculative" 2 "Confident" 3 "Highly Confident" ;
VAL_TABLE_ SRRSRRODPB6P_REOTk2TypAuth 0 "Unknown" 1 "Barriers" 2 "Guard Rails" 3 "Bridge Abutments" 4 "Edge of Road" 5 "Open Area" ;
VAL_TABLE_ SRRSRRODPB6P_REOTk3TypCnfdAuth 0 "Highly Speculative" 1 "Speculative" 2 "Confident" 3 "Highly Confident" ;
VAL_TABLE_ SRRSRRODPB6P_REOTk3TypAuth 0 "Unknown" 1 "Barriers" 2 "Guard Rails" 3 "Bridge Abutments" 4 "Edge of Road" 5 "Open Area" ;
VAL_TABLE_ SRR_LF_CAN8_ClscCANHrtBtActv 0 "FALSE" 1 "TRUE" ;
VAL_TABLE_ SRR_LR_CR_CAN8_ClscCANHrtBtActv 0 "FALSE" 1 "TRUE" ;
VAL_TABLE_ SRR_RF_CAN8_ClscCANHrtBtActv 0 "FALSE" 1 "TRUE" ;
VAL_TABLE_ SRR_RR_CAN8_ClscCANHrtBtActv 0 "FALSE" 1 "TRUE" ;
VAL_TABLE_ SRR_SLR_CAN8_ClscCANHrtBtActv 0 "FALSE" 1 "TRUE" ;
VAL_TABLE_ SRR_SRR_CAN8_ClscCANHrtBtActv 0 "FALSE" 1 "TRUE" ;
VAL_TABLE_ SLVFSP_SpdLimVsnFsdSpdUntAuth 0 "km/h" 1 "mph" ;
VAL_TABLE_ SLVFSP_SpdLimVsnFsdSpdNwDtdAuth 0 "FALSE" 1 "TRUE" ;
VAL_TABLE_ SLVFSP_SpdLimVsnFsdSpdAuth_DuD 0 "FALSE" 1 "TRUE" ;
VAL_TABLE_ SGI2P_AirSpnsnRdHghtLwrActnAuth 0 "None" 1 "Slow" 2 "Medium (Exhaust)" 3 "Fast" ;
VAL_TABLE_ SGI2P_AirSpnsnRdHghtActvAxlAuth 0 "None" 1 "Front" 2 "Rear" 3 "Both" 4 "Pending" ;
VAL_TABLE_ SGI2P_AirSpnsnRdHghtActlStsAuth 0 "Faulted" 1 "Entry/Exit" 2 "Lowered 3" 3 "Lowered 2" 4 "Lowered 1" 5 "Showroom" 6 "Normal" 7 "Raised 1" 8 "Raised 2" 9 "Raised 3" 10 "Cargo" 11 "Trailer Low" 12 "Trailer High" 13 "Car Show" ;
VAL_TABLE_ SGI2P_AirSpnsnRdHghtTgtStsAuth 0 "Faulted" 1 "Entry/Exit" 2 "Lowered 3" 3 "Lowered 2" 4 "Lowered 1" 5 "Showroom" 6 "Normal" 7 "Raised 1" 8 "Raised 2" 9 "Raised 3" 10 "Cargo" 11 "Trailer Low" 12 "Trailer High" 13 "Car Show" ;
VAL_TABLE_ SGI2P_AirSpnsnRdHghtRseActnAuth 0 "None" 1 "Slow(i.e. compressor)" 2 "Medium (i.e. Boost)" 3 "Fast (i.e. Reservoir)" ;
VAL_TABLE_ FsdLoclzdRdTyp 0 "Unknown" 1 "Limited Access Road" 2 "Not Limited Access Road" ;
VAL_TABLE_ UODPFrtEchoAcqTmStm_Inv 0 "FALSE" 1 "TRUE" ;
VAL_TABLE_ UODPFrtSnsr1EchoSnsrMode 0 "Unknown" 1 "Transmit Receive" 2 "Receive" ;
VAL_TABLE_ UODPFrtSnsr1EchoSnsrDatUsg 0 "Don't Use Data" 1 "Use Data" ;
VAL_TABLE_ UODPFrtSnsr2EchoSnsrMode 0 "Unknown" 1 "Transmit Receive" 2 "Receive" ;
VAL_TABLE_ UODPFrtSnsr2EchoSnsrDatUsg 0 "Don't Use Data" 1 "Use Data" ;
VAL_TABLE_ UODPFrtSnsr3EchoSnsrMode 0 "Unknown" 1 "Transmit Receive" 2 "Receive" ;
VAL_TABLE_ UODPFrtSnsr3EchoSnsrDatUsg 0 "Don't Use Data" 1 "Use Data" ;
VAL_TABLE_ UODPFrtSnsr4EchoSnsrMode 0 "Unknown" 1 "Transmit Receive" 2 "Receive" ;
VAL_TABLE_ UODPFrtSnsr4EchoSnsrDatUsg 0 "Don't Use Data" 1 "Use Data" ;
VAL_TABLE_ UODPFrtSnsr5EchoSnsrMode 0 "Unknown" 1 "Transmit Receive" 2 "Receive" ;
VAL_TABLE_ UODPFrtSnsr5EchoSnsrDatUsg 0 "Don't Use Data" 1 "Use Data" ;
VAL_TABLE_ UODPFrtModSts 0 "Unknown" 1 "Internal Failure" 2 "External Failure" 3 "Environmental Disablement" 4 "Unavailable" 5 "Functioning" ;
VAL_TABLE_ UODPSnsAutoPrkAval 0 "FALSE" 1 "TRUE" ;
VAL_TABLE_ UODPFrtSnsr6EchoSnsrMode 0 "Unknown" 1 "Transmit Receive" 2 "Receive" ;
VAL_TABLE_ UODPFrtSnsr6EchoSnsrDatUsg 0 "Don't Use Data" 1 "Use Data" ;
VAL_TABLE_ UODPRrEchoAcqTmStm_Inv 0 "FALSE" 1 "TRUE" ;
VAL_TABLE_ UODPRrSnsr1EchoSnsrMode 0 "Unknown" 1 "Transmit Receive" 2 "Receive" ;
VAL_TABLE_ UODPRrSnsr1EchoSnsrDatUsg 0 "Don't Use Data" 1 "Use Data" ;
VAL_TABLE_ UODPRrSnsr2EchoSnsrMode 0 "Unknown" 1 "Transmit Receive" 2 "Receive" ;
VAL_TABLE_ UODPRrSnsr2EchoSnsrDatUsg 0 "Don't Use Data" 1 "Use Data" ;
VAL_TABLE_ UODPRrSnsr3EchoSnsrMode 0 "Unknown" 1 "Transmit Receive" 2 "Receive" ;
VAL_TABLE_ UODPRrSnsr3EchoSnsrDatUsg 0 "Don't Use Data" 1 "Use Data" ;
VAL_TABLE_ UODPRrSnsr4EchoSnsrMode 0 "Unknown" 1 "Transmit Receive" 2 "Receive" ;
VAL_TABLE_ UODPRrSnsr4EchoSnsrDatUsg 0 "Don't Use Data" 1 "Use Data" ;
VAL_TABLE_ UODPRrSnsr5EchoSnsrMode 0 "Unknown" 1 "Transmit Receive" 2 "Receive" ;
VAL_TABLE_ UODPRrSnsr5EchoSnsrDatUsg 0 "Don't Use Data" 1 "Use Data" ;
VAL_TABLE_ UODPRrModSts 0 "Unknown" 1 "Internal Failure" 2 "External Failure" 3 "Environmental Disablement" 4 "Unavailable" 5 "Functioning" ;
VAL_TABLE_ UODPRrSnsr6EchoSnsrMode 0 "Unknown" 1 "Transmit Receive" 2 "Receive" ;
VAL_TABLE_ UODPRrSnsr6EchoSnsrDatUsg 0 "Don't Use Data" 1 "Use Data" ;
VAL_TABLE_ UODPLoclzdObj10Hght 0 "Unknown" 1 "Traversable" 2 "High Object" 3 "Low Object" ;
VAL_TABLE_ UODPLoclzdObj1Hght 0 "Unknown" 1 "Traversable" 2 "High Object" 3 "Low Object" ;
VAL_TABLE_ UODPLoclzdObj2Hght 0 "Unknown" 1 "Traversable" 2 "High Object" 3 "Low Object" ;
VAL_TABLE_ UODPLoclzdObj3Hght 0 "Unknown" 1 "Traversable" 2 "High Object" 3 "Low Object" ;
VAL_TABLE_ UODPLoclzdObj4Hght 0 "Unknown" 1 "Traversable" 2 "High Object" 3 "Low Object" ;
VAL_TABLE_ UODPLoclzdObj5Hght 0 "Unknown" 1 "Traversable" 2 "High Object" 3 "Low Object" ;
VAL_TABLE_ UODPLoclzdObj6Hght 0 "Unknown" 1 "Traversable" 2 "High Object" 3 "Low Object" ;
VAL_TABLE_ UODPLoclzdObj7Hght 0 "Unknown" 1 "Traversable" 2 "High Object" 3 "Low Object" ;
VAL_TABLE_ UODPLoclzdObj8Hght 0 "Unknown" 1 "Traversable" 2 "High Object" 3 "Low Object" ;
VAL_TABLE_ UODPLoclzdObj9Hght 0 "Unknown" 1 "Traversable" 2 "High Object" 3 "Low Object" ;
VAL_TABLE_ UODPLoclzdObj10Typ 0 "No Object" 1 "Straight 0 Corner" 2 "Straight 1 Corner" 3 "Straight 2 Corners" 4 "Point" 5 "Curbstone" ;
VAL_TABLE_ UODPLoclzdObj1Typ 0 "No Object" 1 "Straight 0 Corner" 2 "Straight 1 Corner" 3 "Straight 2 Corners" 4 "Point" 5 "Curbstone" ;
VAL_TABLE_ UODPLoclzdObj2Typ 0 "No Object" 1 "Straight 0 Corner" 2 "Straight 1 Corner" 3 "Straight 2 Corners" 4 "Point" 5 "Curbstone" ;
VAL_TABLE_ UODPLoclzdObj3Typ 0 "No Object" 1 "Straight 0 Corner" 2 "Straight 1 Corner" 3 "Straight 2 Corners" 4 "Point" 5 "Curbstone" ;
VAL_TABLE_ UODPLoclzdObj4Typ 0 "No Object" 1 "Straight 0 Corner" 2 "Straight 1 Corner" 3 "Straight 2 Corners" 4 "Point" 5 "Curbstone" ;
VAL_TABLE_ UODPLoclzdObj5Typ 0 "No Object" 1 "Straight 0 Corner" 2 "Straight 1 Corner" 3 "Straight 2 Corners" 4 "Point" 5 "Curbstone" ;
VAL_TABLE_ UODPLoclzdObj6Typ 0 "No Object" 1 "Straight 0 Corner" 2 "Straight 1 Corner" 3 "Straight 2 Corners" 4 "Point" 5 "Curbstone" ;
VAL_TABLE_ UODPLoclzdObj7Typ 0 "No Object" 1 "Straight 0 Corner" 2 "Straight 1 Corner" 3 "Straight 2 Corners" 4 "Point" 5 "Curbstone" ;
VAL_TABLE_ UODPLoclzdObj8Typ 0 "No Object" 1 "Straight 0 Corner" 2 "Straight 1 Corner" 3 "Straight 2 Corners" 4 "Point" 5 "Curbstone" ;
VAL_TABLE_ UODPLoclzdObj9Typ 0 "No Object" 1 "Straight 0 Corner" 2 "Straight 1 Corner" 3 "Straight 2 Corners" 4 "Point" 5 "Curbstone" ;
VAL_TABLE_ SuprRmtPrkFirngModeReq 0 "Unknown" 1 "Mode 1" 2 "Mode 2" 3 "Mode 3" 4 "Mode 4" 5 "Custom Mode" ;
VAL_TABLE_ AutoPrkUltrsncObjSnsActvnReqd 0 "FALSE" 1 "TRUE" ;
VAL_TABLE_ SRRLRCRODPTrObjStatInfo 0 "Off" 1 "Passive" 2 "Active" 3 "Restricted" 4 "Invalid" ;
VAL_TABLE_ SRRLRCRODPTOPDtnPrblty_Inv 0 "FALSE" 1 "TRUE" ;
VAL_TABLE_ SRRLRCRODPTOEExistPrblty_Inv 0 "FALSE" 1 "TRUE" ;
VAL_TABLE_ SRRLRCRODPTODVhFrtAxVhHtch_Inv 0 "FALSE" 1 "TRUE" ;
VAL_TABLE_ SRRLRCRODPTODTrHtchTrFrt_Inv 0 "FALSE" 1 "TRUE" ;
VAL_TABLE_ SRRLRCRODPTODTrHtchTrAx_Inv 0 "FALSE" 1 "TRUE" ;
VAL_TABLE_ SRRLRCRODPTrAtchdInfo 0 "Not Attached" 1 "Attached" 2 "Unknown" 3 "Invalid" ;
VAL_TABLE_ SRRLRCRODPTrObjExtrnInfo_Inv 0 "FALSE" 1 "TRUE" ;
VAL_TABLE_ SRRLRCRODPTOVYawRate_Inv 0 "FALSE" 1 "TRUE" ;
VAL_TABLE_ SRRLRCRODPTOVWdth_Inv 0 "FALSE" 1 "TRUE" ;
VAL_TABLE_ SRRLRCRODPTOVOrntn_Inv 0 "FALSE" 1 "TRUE" ;
VAL_TABLE_ SRRLRCRODPTOVLgth_Inv 0 "FALSE" 1 "TRUE" ;
VAL_TABLE_ SRRLRCRODPTOVDVhFrtAxVhHtch_Inv 0 "FALSE" 1 "TRUE" ;
VAL_TABLE_ SRRLRCRODPTOVDTrHtchTrFrt_Inv 0 "FALSE" 1 "TRUE" ;
VAL_TABLE_ SRRLRCRODPTOVDTrHtchTrAx_Inv 0 "FALSE" 1 "TRUE" ;
VAL_TABLE_ SRRLRCRODPTrObjYawRate_Inv 0 "FALSE" 1 "TRUE" ;
VAL_TABLE_ SRRLRCRODPTrObjWdth_Inv 0 "FALSE" 1 "TRUE" ;
VAL_TABLE_ SRRLRCRODPTrObjQlty_Inv 0 "FALSE" 1 "TRUE" ;
VAL_TABLE_ SRRLRCRODPTrObjOrntn_Inv 0 "FALSE" 1 "TRUE" ;
VAL_TABLE_ SRRLRCRODPTrObjLgth_Inv 0 "FALSE" 1 "TRUE" ;
VAL_TABLE_ SRRSLRODPTrObjStatInfo 0 "Off" 1 "Passive" 2 "Active" 3 "Restricted" 4 "Invalid" ;
VAL_TABLE_ SRRSLRODPTOPDtnPrblty_Inv 0 "FALSE" 1 "TRUE" ;
VAL_TABLE_ SRRSLRODPTOEExistPrblty_Inv 0 "FALSE" 1 "TRUE" ;
VAL_TABLE_ SRRSLRODPTODVhFrtAxVhHtch_Inv 0 "FALSE" 1 "TRUE" ;
VAL_TABLE_ SRRSLRODPTODTrHtchTrFrt_Inv 0 "FALSE" 1 "TRUE" ;
VAL_TABLE_ SRRSLRODPTODTrHtchTrAx_Inv 0 "FALSE" 1 "TRUE" ;
VAL_TABLE_ SRRSLRODPTrAtchdInfo 0 "Not Attached" 1 "Attached" 2 "Unknown" 3 "Invalid" ;
VAL_TABLE_ SRRSLRODPTrObjExtrnInfo_Inv 0 "FALSE" 1 "TRUE" ;
VAL_TABLE_ SRRSLRODPTOVYawRate_Inv 0 "FALSE" 1 "TRUE" ;
VAL_TABLE_ SRRSLRODPTOVWdth_Inv 0 "FALSE" 1 "TRUE" ;
VAL_TABLE_ SRRSLRODPTOVOrntn_Inv 0 "FALSE" 1 "TRUE" ;
VAL_TABLE_ SRRSLRODPTOVLgth_Inv 0 "FALSE" 1 "TRUE" ;
VAL_TABLE_ SRRSLRODPTOVDVhFrtAxVhHtch_Inv 0 "FALSE" 1 "TRUE" ;
VAL_TABLE_ SRRSLRODPTOVDTrHtchTrFrt_Inv 0 "FALSE" 1 "TRUE" ;
VAL_TABLE_ SRRSLRODPTOVDTrHtchTrAx_Inv 0 "FALSE" 1 "TRUE" ;
VAL_TABLE_ SRRSLRODPTrObjYawRate_Inv 0 "FALSE" 1 "TRUE" ;
VAL_TABLE_ SRRSLRODPTrObjWdth_Inv 0 "FALSE" 1 "TRUE" ;
VAL_TABLE_ SRRSLRODPTrObjQlty_Inv 0 "FALSE" 1 "TRUE" ;
VAL_TABLE_ SRRSLRODPTrObjOrntn_Inv 0 "FALSE" 1 "TRUE" ;
VAL_TABLE_ SRRSLRODPTrObjLgth_Inv 0 "FALSE" 1 "TRUE" ;
VAL_TABLE_ SRRSRRODPTrObjStatInfo 0 "Off" 1 "Passive" 2 "Active" 3 "Restricted" 4 "Invalid" ;
VAL_TABLE_ SRRSRRODPTOPDtnPrblty_Inv 0 "FALSE" 1 "TRUE" ;
VAL_TABLE_ SRRSRRODPTOEExistPrblty_Inv 0 "FALSE" 1 "TRUE" ;
VAL_TABLE_ SRRSRRODPTODVhFrtAxVhHtch_Inv 0 "FALSE" 1 "TRUE" ;
VAL_TABLE_ SRRSRRODPTODTrHtchTrFrt_Inv 0 "FALSE" 1 "TRUE" ;
VAL_TABLE_ SRRSRRODPTODTrHtchTrAx_Inv 0 "FALSE" 1 "TRUE" ;
VAL_TABLE_ SRRSRRODPTrAtchdInfo 0 "Not Attached" 1 "Attached" 2 "Unknown" 3 "Invalid" ;
VAL_TABLE_ SRRSRRODPTrObjExtrnInfo_Inv 0 "FALSE" 1 "TRUE" ;
VAL_TABLE_ SRRSRRODPTOVYawRate_Inv 0 "FALSE" 1 "TRUE" ;
VAL_TABLE_ SRRSRRODPTOVWdth_Inv 0 "FALSE" 1 "TRUE" ;
VAL_TABLE_ SRRSRRODPTOVOrntn_Inv 0 "FALSE" 1 "TRUE" ;
VAL_TABLE_ SRRSRRODPTOVLgth_Inv 0 "FALSE" 1 "TRUE" ;
VAL_TABLE_ SRRSRRODPTOVDVhFrtAxVhHtch_Inv 0 "FALSE" 1 "TRUE" ;
VAL_TABLE_ SRRSRRODPTOVDTrHtchTrFrt_Inv 0 "FALSE" 1 "TRUE" ;
VAL_TABLE_ SRRSRRODPTOVDTrHtchTrAx_Inv 0 "FALSE" 1 "TRUE" ;
VAL_TABLE_ SRRSRRODPTrObjYawRate_Inv 0 "FALSE" 1 "TRUE" ;
VAL_TABLE_ SRRSRRODPTrObjWdth_Inv 0 "FALSE" 1 "TRUE" ;
VAL_TABLE_ SRRSRRODPTrObjQlty_Inv 0 "FALSE" 1 "TRUE" ;
VAL_TABLE_ SRRSRRODPTrObjOrntn_Inv 0 "FALSE" 1 "TRUE" ;
VAL_TABLE_ SRRSRRODPTrObjLgth_Inv 0 "FALSE" 1 "TRUE" ;
VAL_TABLE_ SRRRRODPTrObjStatInfo 0 "Off" 1 "Passive" 2 "Active" 3 "Restricted" 4 "Invalid" ;
VAL_TABLE_ SRRRRODPTOPDtnPrblty_Inv 0 "FALSE" 1 "TRUE" ;
VAL_TABLE_ SRRRRODPTOEExistPrblty_Inv 0 "FALSE" 1 "TRUE" ;
VAL_TABLE_ SRRRRODPTODVhFrtAxVhHtch_Inv 0 "FALSE" 1 "TRUE" ;
VAL_TABLE_ SRRRRODPTODTrHtchTrFrt_Inv 0 "FALSE" 1 "TRUE" ;
VAL_TABLE_ SRRRRODPTODTrHtchTrAx_Inv 0 "FALSE" 1 "TRUE" ;
VAL_TABLE_ SRRRRODPTrAtchdInfo 0 "Not Attached" 1 "Attached" 2 "Unknown" 3 "Invalid" ;
VAL_TABLE_ SRRRRODPTrObjExtrnInfo_Inv 0 "FALSE" 1 "TRUE" ;
VAL_TABLE_ SRRRRODPTOVYawRate_Inv 0 "FALSE" 1 "TRUE" ;
VAL_TABLE_ SRRRRODPTOVWdth_Inv 0 "FALSE" 1 "TRUE" ;
VAL_TABLE_ SRRRRODPTOVOrntn_Inv 0 "FALSE" 1 "TRUE" ;
VAL_TABLE_ SRRRRODPTOVLgth_Inv 0 "FALSE" 1 "TRUE" ;
VAL_TABLE_ SRRRRODPTOVDVhFrtAxVhHtch_Inv 0 "FALSE" 1 "TRUE" ;
VAL_TABLE_ SRRRRODPTOVDTrHtchTrFrt_Inv 0 "FALSE" 1 "TRUE" ;
VAL_TABLE_ SRRRRODPTOVDTrHtchTrAx_Inv 0 "FALSE" 1 "TRUE" ;
VAL_TABLE_ SRRRRODPTrObjYawRate_Inv 0 "FALSE" 1 "TRUE" ;
VAL_TABLE_ SRRRRODPTrObjWdth_Inv 0 "FALSE" 1 "TRUE" ;
VAL_TABLE_ SRRRRODPTrObjQlty_Inv 0 "FALSE" 1 "TRUE" ;
VAL_TABLE_ SRRRRODPTrObjOrntn_Inv 0 "FALSE" 1 "TRUE" ;
VAL_TABLE_ SRRRRODPTrObjLgth_Inv 0 "FALSE" 1 "TRUE" ;
VAL_TABLE_ DIATMNP_DrvrIntdAxlTqMnAuth_Inv 0 "FALSE" 1 "TRUE" ;
VAL_TABLE_ DIATMXP_DrvrIntdAxlTqMxAuth_Inv 0 "FALSE" 1 "TRUE" ;
VAL_TABLE_ DITP_DrvrIntndAxlTrqAuth_Inv 0 "FALSE" 1 "TRUE" ;
VAL_TABLE_ VMI1P_AccelPedOvrrdActvAuth 0 "FALSE" 1 "TRUE" ;
VAL_TABLE_ VMI1P_AccelActlPstnAuth_Inv 0 "FALSE" 1 "TRUE" ;
VAL_TABLE_ VMI1P_VehTopSpdLimModeActvAuth 0 "FALSE" 1 "TRUE" ;
VAL_TABLE_ VehSpdAvgNDrvn_Inv 0 "FALSE" 1 "TRUE" ;
VAL_TABLE_ EGI3P_CnvtTpSpLimRspTypAuth 0 "Inactive" 1 "Faulted" 2 "Safety_woBrake" 3 "Safety_wBrake" 4 "OBD" 5 "nonOBD" 6 "Legislated" ;
VAL_TABLE_ PSP_PrkNeutSwStatAuth_Inv 0 "FALSE" 1 "TRUE" ;
VAL_TABLE_ PSP_PrkNeutSwStatAuth 0 "Park/Neutral" 1 "Not Park/Neutral" ;
VAL_TABLE_ PSP_EngRnngAuth 0 "FALSE" 1 "TRUE" ;
VAL_TABLE_ PSP_ClchBtmTrvlAchvdAuth_Inv 0 "FALSE" 1 "TRUE" ;
VAL_TABLE_ PSP_ClchBtmTrvlAchvdAuth 0 "FALSE" 1 "TRUE" ;
VAL_TABLE_ PSP_VehTheftImbChlgRespStsAuth 0 "Undetermined" 1 "Pass" 2 "Fail" ;
VAL_TABLE_ PSP_RmtVehStrtEngRnngAuth 0 "FALSE" 1 "TRUE" ;
VAL_TABLE_ PSP_PwrtrnCrnkAbrtdAuth 0 "FALSE" 1 "TRUE" ;
VAL_TABLE_ PSP_PrplSysStlActvAuth 0 "FALSE" 1 "TRUE" ;
VAL_TABLE_ PSP_PrplSysActvAuth 0 "FALSE" 1 "TRUE" ;
VAL_TABLE_ PrplBrkThrotOvrrdReqd 0 "FALSE" 1 "TRUE" ;
VAL_TABLE_ TGIP_TrnsEgdPrFlwStAuth 0 "Unavailable" 1 "No Powerflow" 2 "Drive Engaged" 3 "Reverse Engaged" ;
VAL_TABLE_ TARSP_TransActlRngAuth_Inv 0 "FALSE" 1 "TRUE" ;
VAL_TABLE_ TARSP_TransActlRngAuth_DuD 0 "FALSE" 1 "TRUE" ;
VAL_TABLE_ TARSP_TransActlRngAuth 0 "Unknown Position" 1 "Park Position" 2 "Between Park and Reverse" 3 "Reverse Position" 4 "Between Reverse and Neutral" 5 "Neutral Position" 6 "Between Neutral and First Drive Position" 7 "First Drive Position" 8 "Between First and Second Drive Position" 9 "Second Drive Position" 10 "Between Second and Third Position" 11 "Third Drive Position" 12 "Between Third and Fourth Position" 13 "Fourth Drive Position" ;
VAL_TABLE_ TRDP_TrnsPkRgDgLtFltAuth 0 "FALSE" 1 "TRUE" ;
VAL_TABLE_ TRDP_TrnsPkRgDgCtFltAuth 0 "FALSE" 1 "TRUE" ;
VAL_TABLE_ TRDP_TrnsNtRgDgLtFltAuth 0 "FALSE" 1 "TRUE" ;
VAL_TABLE_ TRDP_TrnsNtRgDgCtFltAuth 0 "FALSE" 1 "TRUE" ;
VAL_TABLE_ TRDP_TrnsFwDrvRDLFltAuth 0 "FALSE" 1 "TRUE" ;
VAL_TABLE_ TRDP_TrnsFwDrvRDCFltAuth 0 "FALSE" 1 "TRUE" ;
VAL_TABLE_ TGIP_TrnsEgdPrFlwStAuth_Inv 0 "FALSE" 1 "TRUE" ;
VAL_TABLE_ TSP_TmpDrvrShfCtlActvAuth 0 "FALSE" 1 "TRUE" ;
VAL_TABLE_ TSP_ElecRngSeltnInDrvActvAuth 0 "FALSE" 1 "TRUE" ;
VAL_TABLE_ TRDP_TrnsRvRgDgLtFltAuth 0 "FALSE" 1 "TRUE" ;
VAL_TABLE_ TRDP_TrnsRvRgDgCtFltAuth 0 "FALSE" 1 "TRUE" ;
VAL_TABLE_ LatAccelSnsrCorrStsAuth 0 "Unknown" 1 "NA" 2 "Correlated" 3 "Uncorellated" ;
VAL_TABLE_ LatAccelAuth_Inv 0 "FALSE" 1 "TRUE" ;
VAL_TABLE_ LongAccelAuth_Inv 0 "FALSE" 1 "TRUE" ;
VAL_TABLE_ VehAccelCalAuth 0 "FALSE" 1 "TRUE" ;
VAL_TABLE_ LongAccelSnsrCorrStsAuth 0 "Unknown" 1 "NA" 2 "Correlated" 3 "Uncorellated" ;
VAL_TABLE_ YRP_RollRateAuth_Inv 0 "FALSE" 1 "TRUE" ;
VAL_TABLE_ YRP_RollRateAuth_DuD 0 "FALSE" 1 "TRUE" ;
VAL_TABLE_ YawRateAuth_DuD 0 "FALSE" 1 "TRUE" ;
VAL_TABLE_ YawRateCorrAuth 0 "Unknown" 1 "NA" 2 "Correlated" 3 "Uncorellated" ;
VAL_TABLE_ YawRateAuth_Inv 0 "FALSE" 1 "TRUE" ;
VAL_TABLE_ VehAccelAuth_DuD 0 "FALSE" 1 "TRUE" ;
VAL_TABLE_ RIP_PreRelAllwdAuth 0 "FALSE" 1 "TRUE" ;
VAL_TABLE_ RIP_ElecStrgColUnlckAllwdAuth 0 "FALSE" 1 "TRUE" ;
VAL_TABLE_ BGI1P_RmtVehStrtReqAuth 0 "FALSE" 1 "TRUE" ;
VAL_TABLE_ BGI1P_RmtStrtStsAuth 0 "Inactive" 1 "Active" ;
VAL_TABLE_ SPMP_PriRunCrnkCmdActvAuth 0 "FALSE" 1 "TRUE" ;
VAL_TABLE_ RIP_StrtStopIgnSwPrssdAuth 0 "FALSE" 1 "TRUE" ;
VAL_TABLE_ RIP_StrtStopIgnSwPrssdAuth_Inv 0 "FALSE" 1 "TRUE" ;
VAL_TABLE_ SPMP_SysPwrModeAuth_Inv 0 "FALSE" 1 "TRUE" ;
VAL_TABLE_ SPMP_SysPwrModeAuth 0 "Off" 1 "Accessory" 2 "Run" 3 "Start Request" 4 "Propulsion" ;
VAL_TABLE_ SPMP_PriRunCrnkCmdActvAuth_Inv 0 "FALSE" 1 "TRUE" ;
VAL_TABLE_ SRRLRCODPIOTk10TypAuth 0 "Unknown" 1 "Guard Rail" 2 "Tunnel" 3 "Traffic Sign" 4 "Bridge" 5 "Pole" ;
VAL_TABLE_ SRRLRCODPIOTk1TypAuth 0 "Unknown" 1 "Guard Rail" 2 "Tunnel" 3 "Traffic Sign" 4 "Bridge" 5 "Pole" ;
VAL_TABLE_ SRRLRCODPIOTk2TypAuth 0 "Unknown" 1 "Guard Rail" 2 "Tunnel" 3 "Traffic Sign" 4 "Bridge" 5 "Pole" ;
VAL_TABLE_ SRRLRCODPIOTk3TypAuth 0 "Unknown" 1 "Guard Rail" 2 "Tunnel" 3 "Traffic Sign" 4 "Bridge" 5 "Pole" ;
VAL_TABLE_ SRRLRCODPIOTk4TypAuth 0 "Unknown" 1 "Guard Rail" 2 "Tunnel" 3 "Traffic Sign" 4 "Bridge" 5 "Pole" ;
VAL_TABLE_ SRRLRCODPIOTk5TypAuth 0 "Unknown" 1 "Guard Rail" 2 "Tunnel" 3 "Traffic Sign" 4 "Bridge" 5 "Pole" ;
VAL_TABLE_ SRRLRCODPIOTk6TypAuth 0 "Unknown" 1 "Guard Rail" 2 "Tunnel" 3 "Traffic Sign" 4 "Bridge" 5 "Pole" ;
VAL_TABLE_ SRRLRCODPIOTk7TypAuth 0 "Unknown" 1 "Guard Rail" 2 "Tunnel" 3 "Traffic Sign" 4 "Bridge" 5 "Pole" ;
VAL_TABLE_ SRRLRCODPIOTk8TypAuth 0 "Unknown" 1 "Guard Rail" 2 "Tunnel" 3 "Traffic Sign" 4 "Bridge" 5 "Pole" ;
VAL_TABLE_ SRRLRCODPIOTk9TypAuth 0 "Unknown" 1 "Guard Rail" 2 "Tunnel" 3 "Traffic Sign" 4 "Bridge" 5 "Pole" ;
VAL_TABLE_ SRRLRCODPPOTk1DynPrpAuth 0 "Has Never Moved" 1 "Has Moved But Currently Stopped" 2 "Moving In Same Direction As Host" 3 "Moving In Opposite Direction As Host" 4 "Crossing Path" ;
VAL_TABLE_ SRRLRCODPPOTk2DynPrpAuth 0 "Has Never Moved" 1 "Has Moved But Currently Stopped" 2 "Moving In Same Direction As Host" 3 "Moving In Opposite Direction As Host" 4 "Crossing Path" ;
VAL_TABLE_ SRRLRCODPPOTk3DynPrpAuth 0 "Has Never Moved" 1 "Has Moved But Currently Stopped" 2 "Moving In Same Direction As Host" 3 "Moving In Opposite Direction As Host" 4 "Crossing Path" ;
VAL_TABLE_ SRRLRCODPPOTk4DynPrpAuth 0 "Has Never Moved" 1 "Has Moved But Currently Stopped" 2 "Moving In Same Direction As Host" 3 "Moving In Opposite Direction As Host" 4 "Crossing Path" ;
VAL_TABLE_ SRRLRCODPPOTk5DynPrpAuth 0 "Has Never Moved" 1 "Has Moved But Currently Stopped" 2 "Moving In Same Direction As Host" 3 "Moving In Opposite Direction As Host" 4 "Crossing Path" ;
VAL_TABLE_ SRRLRCODPREOTk1TypAuth 0 "Unknown" 1 "Barriers" 2 "Guard Rails" 3 "Bridge Abutments" 4 "Edge of Road" 5 "Open Area" ;
VAL_TABLE_ SRRLRCODPREOTk2TypAuth 0 "Unknown" 1 "Barriers" 2 "Guard Rails" 3 "Bridge Abutments" 4 "Edge of Road" 5 "Open Area" ;
VAL_TABLE_ SRRLRCODPREOTk3TypAuth 0 "Unknown" 1 "Barriers" 2 "Guard Rails" 3 "Bridge Abutments" 4 "Edge of Road" 5 "Open Area" ;
VAL_TABLE_ SRRLRCODPRdTypAuth 0 "Unknown" 1 "City" 2 "Secondary Road" 3 "Highway" 4 "Construction Zone Entry" 5 "Construction Zone Exit" ;
VAL_TABLE_ SRRLRCODPVOTk10DynPrpAuth 0 "Has Never Moved" 1 "Moving In Same Direction As Host" 2 "Moving In Opposite Direction As Host" 3 "Crossing From Left To Right" 4 "Crossing From Right To Left" ;
VAL_TABLE_ SRRLRCODPVOTk1DynPrpAuth 0 "Has Never Moved" 1 "Moving In Same Direction As Host" 2 "Moving In Opposite Direction As Host" 3 "Crossing From Left To Right" 4 "Crossing From Right To Left" ;
VAL_TABLE_ SRRLRCODPVOTk2DynPrpAuth 0 "Has Never Moved" 1 "Moving In Same Direction As Host" 2 "Moving In Opposite Direction As Host" 3 "Crossing From Left To Right" 4 "Crossing From Right To Left" ;
VAL_TABLE_ SRRLRCODPVOTk3DynPrpAuth 0 "Has Never Moved" 1 "Moving In Same Direction As Host" 2 "Moving In Opposite Direction As Host" 3 "Crossing From Left To Right" 4 "Crossing From Right To Left" ;
VAL_TABLE_ SRRLRCODPVOTk4DynPrpAuth 0 "Has Never Moved" 1 "Moving In Same Direction As Host" 2 "Moving In Opposite Direction As Host" 3 "Crossing From Left To Right" 4 "Crossing From Right To Left" ;
VAL_TABLE_ SRRLRCODPVOTk5DynPrpAuth 0 "Has Never Moved" 1 "Moving In Same Direction As Host" 2 "Moving In Opposite Direction As Host" 3 "Crossing From Left To Right" 4 "Crossing From Right To Left" ;
VAL_TABLE_ SRRLRCODPVOTk6DynPrpAuth 0 "Has Never Moved" 1 "Moving In Same Direction As Host" 2 "Moving In Opposite Direction As Host" 3 "Crossing From Left To Right" 4 "Crossing From Right To Left" ;
VAL_TABLE_ SRRLRCODPVOTk7DynPrpAuth 0 "Has Never Moved" 1 "Moving In Same Direction As Host" 2 "Moving In Opposite Direction As Host" 3 "Crossing From Left To Right" 4 "Crossing From Right To Left" ;
VAL_TABLE_ SRRLRCODPVOTk8DynPrpAuth 0 "Has Never Moved" 1 "Moving In Same Direction As Host" 2 "Moving In Opposite Direction As Host" 3 "Crossing From Left To Right" 4 "Crossing From Right To Left" ;
VAL_TABLE_ SRRLRCODPVOTk9DynPrpAuth 0 "Has Never Moved" 1 "Moving In Same Direction As Host" 2 "Moving In Opposite Direction As Host" 3 "Crossing From Left To Right" 4 "Crossing From Right To Left" ;
VAL_TABLE_ SRRLRCODPConstrArDtnCnfdAuth 0 "Highly Speculative" 1 "Speculative" 2 "Confident" 3 "Highly Confident" ;
VAL_TABLE_ SRRLRCODPConstrArDtnStsAuth 0 "Not Detected" 1 "Detected" 2 "Unknown" ;
VAL_TABLE_ SRRLRCODPIOTk10CnfdStsAuth 0 "Highly Speculative" 1 "Speculative" 2 "Confident" 3 "Highly Confident" ;
VAL_TABLE_ SRRLRCODPIOTk10ElvtnAuth 0 "Not Elevated" 1 "Elevation Speculative" 2 "Elevation Confident" 3 "Elevation Very Confident" ;
VAL_TABLE_ SRRLRCODPIOTk10MStsAuth 0 "No Object" 1 "New Object" 2 "Latent Track Not Detected this Cycle" 3 "Measured this Cycle" ;
VAL_TABLE_ SRRLRCODPIOTk10TypCnfdAuth 0 "Highly Speculative" 1 "Speculative" 2 "Confident" 3 "Highly Confident" ;
VAL_TABLE_ SRRLRCODPIOTk1CnfdStsAuth 0 "Highly Speculative" 1 "Speculative" 2 "Confident" 3 "Highly Confident" ;
VAL_TABLE_ SRRLRCODPIOTk1ElvtnAuth 0 "Not Elevated" 1 "Elevation Speculative" 2 "Elevation Confident" 3 "Elevation Very Confident" ;
VAL_TABLE_ SRRLRCODPIOTk1MStsAuth 0 "No Object" 1 "New Object" 2 "Latent Track Not Detected this Cycle" 3 "Measured this Cycle" ;
VAL_TABLE_ SRRLRCODPIOTk1TypCnfdAuth 0 "Highly Speculative" 1 "Speculative" 2 "Confident" 3 "Highly Confident" ;
VAL_TABLE_ SRRLRCODPIOTk2CnfdStsAuth 0 "Highly Speculative" 1 "Speculative" 2 "Confident" 3 "Highly Confident" ;
VAL_TABLE_ SRRLRCODPIOTk2ElvtnAuth 0 "Not Elevated" 1 "Elevation Speculative" 2 "Elevation Confident" 3 "Elevation Very Confident" ;
VAL_TABLE_ SRRLRCODPIOTk2MStsAuth 0 "No Object" 1 "New Object" 2 "Latent Track Not Detected this Cycle" 3 "Measured this Cycle" ;
VAL_TABLE_ SRRLRCODPIOTk2TypCnfdAuth 0 "Highly Speculative" 1 "Speculative" 2 "Confident" 3 "Highly Confident" ;
VAL_TABLE_ SRRLRCODPIOTk3CnfdStsAuth 0 "Highly Speculative" 1 "Speculative" 2 "Confident" 3 "Highly Confident" ;
VAL_TABLE_ SRRLRCODPIOTk3ElvtnAuth 0 "Not Elevated" 1 "Elevation Speculative" 2 "Elevation Confident" 3 "Elevation Very Confident" ;
VAL_TABLE_ SRRLRCODPIOTk3MStsAuth 0 "No Object" 1 "New Object" 2 "Latent Track Not Detected this Cycle" 3 "Measured this Cycle" ;
VAL_TABLE_ SRRLRCODPIOTk3TypCnfdAuth 0 "Highly Speculative" 1 "Speculative" 2 "Confident" 3 "Highly Confident" ;
VAL_TABLE_ SRRLRCODPIOTk4CnfdStsAuth 0 "Highly Speculative" 1 "Speculative" 2 "Confident" 3 "Highly Confident" ;
VAL_TABLE_ SRRLRCODPIOTk4ElvtnAuth 0 "Not Elevated" 1 "Elevation Speculative" 2 "Elevation Confident" 3 "Elevation Very Confident" ;
VAL_TABLE_ SRRLRCODPIOTk4MStsAuth 0 "No Object" 1 "New Object" 2 "Latent Track Not Detected this Cycle" 3 "Measured this Cycle" ;
VAL_TABLE_ SRRLRCODPIOTk4TypCnfdAuth 0 "Highly Speculative" 1 "Speculative" 2 "Confident" 3 "Highly Confident" ;
VAL_TABLE_ SRRLRCODPIOTk5CnfdStsAuth 0 "Highly Speculative" 1 "Speculative" 2 "Confident" 3 "Highly Confident" ;
VAL_TABLE_ SRRLRCODPIOTk5ElvtnAuth 0 "Not Elevated" 1 "Elevation Speculative" 2 "Elevation Confident" 3 "Elevation Very Confident" ;
VAL_TABLE_ SRRLRCODPIOTk5MStsAuth 0 "No Object" 1 "New Object" 2 "Latent Track Not Detected this Cycle" 3 "Measured this Cycle" ;
VAL_TABLE_ SRRLRCODPIOTk5TypCnfdAuth 0 "Highly Speculative" 1 "Speculative" 2 "Confident" 3 "Highly Confident" ;
VAL_TABLE_ SRRLRCODPIOTk6CnfdStsAuth 0 "Highly Speculative" 1 "Speculative" 2 "Confident" 3 "Highly Confident" ;
VAL_TABLE_ SRRLRCODPIOTk6ElvtnAuth 0 "Not Elevated" 1 "Elevation Speculative" 2 "Elevation Confident" 3 "Elevation Very Confident" ;
VAL_TABLE_ SRRLRCODPIOTk6MStsAuth 0 "No Object" 1 "New Object" 2 "Latent Track Not Detected this Cycle" 3 "Measured this Cycle" ;
VAL_TABLE_ SRRLRCODPIOTk6TypCnfdAuth 0 "Highly Speculative" 1 "Speculative" 2 "Confident" 3 "Highly Confident" ;
VAL_TABLE_ SRRLRCODPIOTk7CnfdStsAuth 0 "Highly Speculative" 1 "Speculative" 2 "Confident" 3 "Highly Confident" ;
VAL_TABLE_ SRRLRCODPIOTk7ElvtnAuth 0 "Not Elevated" 1 "Elevation Speculative" 2 "Elevation Confident" 3 "Elevation Very Confident" ;
VAL_TABLE_ SRRLRCODPIOTk7MStsAuth 0 "No Object" 1 "New Object" 2 "Latent Track Not Detected this Cycle" 3 "Measured this Cycle" ;
VAL_TABLE_ SRRLRCODPIOTk7TypCnfdAuth 0 "Highly Speculative" 1 "Speculative" 2 "Confident" 3 "Highly Confident" ;
VAL_TABLE_ SRRLRCODPIOTk8CnfdStsAuth 0 "Highly Speculative" 1 "Speculative" 2 "Confident" 3 "Highly Confident" ;
VAL_TABLE_ SRRLRCODPIOTk8ElvtnAuth 0 "Not Elevated" 1 "Elevation Speculative" 2 "Elevation Confident" 3 "Elevation Very Confident" ;
VAL_TABLE_ SRRLRCODPIOTk8MStsAuth 0 "No Object" 1 "New Object" 2 "Latent Track Not Detected this Cycle" 3 "Measured this Cycle" ;
VAL_TABLE_ SRRLRCODPIOTk8TypCnfdAuth 0 "Highly Speculative" 1 "Speculative" 2 "Confident" 3 "Highly Confident" ;
VAL_TABLE_ SRRLRCODPIOTk9CnfdStsAuth 0 "Highly Speculative" 1 "Speculative" 2 "Confident" 3 "Highly Confident" ;
VAL_TABLE_ SRRLRCODPIOTk9ElvtnAuth 0 "Not Elevated" 1 "Elevation Speculative" 2 "Elevation Confident" 3 "Elevation Very Confident" ;
VAL_TABLE_ SRRLRCODPIOTk9MStsAuth 0 "No Object" 1 "New Object" 2 "Latent Track Not Detected this Cycle" 3 "Measured this Cycle" ;
VAL_TABLE_ SRRLRCODPIOTk9TypCnfdAuth 0 "Highly Speculative" 1 "Speculative" 2 "Confident" 3 "Highly Confident" ;
VAL_TABLE_ SRRLRCODPMdCmdStsAuth 0 "Not Radiating" 1 "Reporting Object Data" 2 "Not Reporting Object Data" ;
VAL_TABLE_ SRRLRCODPPOTk1CnfdStsAuth 0 "Highly Speculative" 1 "Speculative" 2 "Confident" 3 "Highly Confident" ;
VAL_TABLE_ SRRLRCODPPOTk1MStsAuth 0 "No Object" 1 "New Object" 2 "Latent Track Not Detected this Cycle" 3 "Measured this Cycle" ;
VAL_TABLE_ SRRLRCODPPOTk1TypAuth 0 "Unknown" 1 "Pedestrian" 2 "Bicycle" ;
VAL_TABLE_ SRRLRCODPPOTk1TypCnfdAuth 0 "Highly Speculative" 1 "Speculative" 2 "Confident" 3 "Highly Confident" ;
VAL_TABLE_ SRRLRCODPPOTk2CnfdStsAuth 0 "Highly Speculative" 1 "Speculative" 2 "Confident" 3 "Highly Confident" ;
VAL_TABLE_ SRRLRCODPPOTk2MStsAuth 0 "No Object" 1 "New Object" 2 "Latent Track Not Detected this Cycle" 3 "Measured this Cycle" ;
VAL_TABLE_ SRRLRCODPPOTk2TypAuth 0 "Unknown" 1 "Pedestrian" 2 "Bicycle" ;
VAL_TABLE_ SRRLRCODPPOTk2TypCnfdAuth 0 "Highly Speculative" 1 "Speculative" 2 "Confident" 3 "Highly Confident" ;
VAL_TABLE_ SRRLRCODPPOTk3CnfdStsAuth 0 "Highly Speculative" 1 "Speculative" 2 "Confident" 3 "Highly Confident" ;
VAL_TABLE_ SRRLRCODPPOTk3MStsAuth 0 "No Object" 1 "New Object" 2 "Latent Track Not Detected this Cycle" 3 "Measured this Cycle" ;
VAL_TABLE_ SRRLRCODPPOTk3TypAuth 0 "Unknown" 1 "Pedestrian" 2 "Bicycle" ;
VAL_TABLE_ SRRLRCODPPOTk3TypCnfdAuth 0 "Highly Speculative" 1 "Speculative" 2 "Confident" 3 "Highly Confident" ;
VAL_TABLE_ SRRLRCODPPOTk4CnfdStsAuth 0 "Highly Speculative" 1 "Speculative" 2 "Confident" 3 "Highly Confident" ;
VAL_TABLE_ SRRLRCODPPOTk4MStsAuth 0 "No Object" 1 "New Object" 2 "Latent Track Not Detected this Cycle" 3 "Measured this Cycle" ;
VAL_TABLE_ SRRLRCODPPOTk4TypAuth 0 "Unknown" 1 "Pedestrian" 2 "Bicycle" ;
VAL_TABLE_ SRRLRCODPPOTk4TypCnfdAuth 0 "Highly Speculative" 1 "Speculative" 2 "Confident" 3 "Highly Confident" ;
VAL_TABLE_ SRRLRCODPPOTk5CnfdStsAuth 0 "Highly Speculative" 1 "Speculative" 2 "Confident" 3 "Highly Confident" ;
VAL_TABLE_ SRRLRCODPPOTk5MStsAuth 0 "No Object" 1 "New Object" 2 "Latent Track Not Detected this Cycle" 3 "Measured this Cycle" ;
VAL_TABLE_ SRRLRCODPPOTk5TypAuth 0 "Unknown" 1 "Pedestrian" 2 "Bicycle" ;
VAL_TABLE_ SRRLRCODPPOTk5TypCnfdAuth 0 "Highly Speculative" 1 "Speculative" 2 "Confident" 3 "Highly Confident" ;
VAL_TABLE_ SRRLRCODPREOTk1CnfdStsAuth 0 "Highly Speculative" 1 "Speculative" 2 "Confident" 3 "Highly Confident" ;
VAL_TABLE_ SRRLRCODPREOTk1TypCnfdAuth 0 "Highly Speculative" 1 "Speculative" 2 "Confident" 3 "Highly Confident" ;
VAL_TABLE_ SRRLRCODPREOTk2CnfdStsAuth 0 "Highly Speculative" 1 "Speculative" 2 "Confident" 3 "Highly Confident" ;
VAL_TABLE_ SRRLRCODPREOTk2TypCnfdAuth 0 "Highly Speculative" 1 "Speculative" 2 "Confident" 3 "Highly Confident" ;
VAL_TABLE_ SRRLRCODPREOTk3CnfdStsAuth 0 "Highly Speculative" 1 "Speculative" 2 "Confident" 3 "Highly Confident" ;
VAL_TABLE_ SRRLRCODPREOTk3TypCnfdAuth 0 "Highly Speculative" 1 "Speculative" 2 "Confident" 3 "Highly Confident" ;
VAL_TABLE_ SRRLRCODPRdTypCnfdAuth 0 "Highly Speculative" 1 "Speculative" 2 "Confident" 3 "Highly Confident" ;
VAL_TABLE_ SRRLRCODPSwpBndwdthStsAuth 0 "Mode A" 1 "Mode B" 2 "Mode C" 3 "Mode D" ;
VAL_TABLE_ SRRLRCODPVOTk10CnfdStsAuth 0 "Highly Speculative" 1 "Speculative" 2 "Confident" 3 "Highly Confident" ;
VAL_TABLE_ SRRLRCODPVOTk10MStsAuth 0 "No Object" 1 "New Object" 2 "Latent Track Not Detected this Cycle" 3 "Measured this Cycle" ;
VAL_TABLE_ SRRLRCODPVOTk10TypCnfdAuth 0 "Highly Speculative" 1 "Speculative" 2 "Confident" 3 "Highly Confident" ;
VAL_TABLE_ SRRLRCODPVOTk1CnfdStsAuth 0 "Highly Speculative" 1 "Speculative" 2 "Confident" 3 "Highly Confident" ;
VAL_TABLE_ SRRLRCODPVOTk1MStsAuth 0 "No Object" 1 "New Object" 2 "Latent Track Not Detected this Cycle" 3 "Measured this Cycle" ;
VAL_TABLE_ SRRLRCODPVOTk1TypCnfdAuth 0 "Highly Speculative" 1 "Speculative" 2 "Confident" 3 "Highly Confident" ;
VAL_TABLE_ SRRLRCODPVOTk2CnfdStsAuth 0 "Highly Speculative" 1 "Speculative" 2 "Confident" 3 "Highly Confident" ;
VAL_TABLE_ SRRLRCODPVOTk2MStsAuth 0 "No Object" 1 "New Object" 2 "Latent Track Not Detected this Cycle" 3 "Measured this Cycle" ;
VAL_TABLE_ SRRLRCODPVOTk2TypCnfdAuth 0 "Highly Speculative" 1 "Speculative" 2 "Confident" 3 "Highly Confident" ;
VAL_TABLE_ SRRLRCODPVOTk3CnfdStsAuth 0 "Highly Speculative" 1 "Speculative" 2 "Confident" 3 "Highly Confident" ;
VAL_TABLE_ SRRLRCODPVOTk3MStsAuth 0 "No Object" 1 "New Object" 2 "Latent Track Not Detected this Cycle" 3 "Measured this Cycle" ;
VAL_TABLE_ SRRLRCODPVOTk3TypCnfdAuth 0 "Highly Speculative" 1 "Speculative" 2 "Confident" 3 "Highly Confident" ;
VAL_TABLE_ SRRLRCODPVOTk4CnfdStsAuth 0 "Highly Speculative" 1 "Speculative" 2 "Confident" 3 "Highly Confident" ;
VAL_TABLE_ SRRLRCODPVOTk4MStsAuth 0 "No Object" 1 "New Object" 2 "Latent Track Not Detected this Cycle" 3 "Measured this Cycle" ;
VAL_TABLE_ SRRLRCODPVOTk4TypCnfdAuth 0 "Highly Speculative" 1 "Speculative" 2 "Confident" 3 "Highly Confident" ;
VAL_TABLE_ SRRLRCODPVOTk5CnfdStsAuth 0 "Highly Speculative" 1 "Speculative" 2 "Confident" 3 "Highly Confident" ;
VAL_TABLE_ SRRLRCODPVOTk5MStsAuth 0 "No Object" 1 "New Object" 2 "Latent Track Not Detected this Cycle" 3 "Measured this Cycle" ;
VAL_TABLE_ SRRLRCODPVOTk5TypCnfdAuth 0 "Highly Speculative" 1 "Speculative" 2 "Confident" 3 "Highly Confident" ;
VAL_TABLE_ SRRLRCODPVOTk6CnfdStsAuth 0 "Highly Speculative" 1 "Speculative" 2 "Confident" 3 "Highly Confident" ;
VAL_TABLE_ SRRLRCODPVOTk6MStsAuth 0 "No Object" 1 "New Object" 2 "Latent Track Not Detected this Cycle" 3 "Measured this Cycle" ;
VAL_TABLE_ SRRLRCODPVOTk6TypCnfdAuth 0 "Highly Speculative" 1 "Speculative" 2 "Confident" 3 "Highly Confident" ;
VAL_TABLE_ SRRLRCODPVOTk7CnfdStsAuth 0 "Highly Speculative" 1 "Speculative" 2 "Confident" 3 "Highly Confident" ;
VAL_TABLE_ SRRLRCODPVOTk7MStsAuth 0 "No Object" 1 "New Object" 2 "Latent Track Not Detected this Cycle" 3 "Measured this Cycle" ;
VAL_TABLE_ SRRLRCODPVOTk7TypCnfdAuth 0 "Highly Speculative" 1 "Speculative" 2 "Confident" 3 "Highly Confident" ;
VAL_TABLE_ SRRLRCODPVOTk8CnfdStsAuth 0 "Highly Speculative" 1 "Speculative" 2 "Confident" 3 "Highly Confident" ;
VAL_TABLE_ SRRLRCODPVOTk8MStsAuth 0 "No Object" 1 "New Object" 2 "Latent Track Not Detected this Cycle" 3 "Measured this Cycle" ;
VAL_TABLE_ SRRLRCODPVOTk8TypCnfdAuth 0 "Highly Speculative" 1 "Speculative" 2 "Confident" 3 "Highly Confident" ;
VAL_TABLE_ SRRLRCODPVOTk9CnfdStsAuth 0 "Highly Speculative" 1 "Speculative" 2 "Confident" 3 "Highly Confident" ;
VAL_TABLE_ SRRLRCODPVOTk9MStsAuth 0 "No Object" 1 "New Object" 2 "Latent Track Not Detected this Cycle" 3 "Measured this Cycle" ;
VAL_TABLE_ SRRLRCODPVOTk9TypCnfdAuth 0 "Highly Speculative" 1 "Speculative" 2 "Confident" 3 "Highly Confident" ;
VAL_TABLE_ SRRLRCODPAcqTmStmAuth_Inv 0 "FALSE" 1 "TRUE" ;
VAL_TABLE_ SRRLRCODPServRqrdAuth 0 "FALSE" 1 "TRUE" ;
VAL_TABLE_ SRRLRCODPSnsrBlckdAuth 0 "FALSE" 1 "TRUE" ;
VAL_TABLE_ SRRLRCODPSnsrUnvAuth 0 "FALSE" 1 "TRUE" ;
VAL_TABLE_ SRRLRCODPVOTk10DynPrpStsAuth 0 "Stopped" 1 "Not Stopped" ;
VAL_TABLE_ SRRLRCODPVOTk1DynPrpStsAuth 0 "Stopped" 1 "Not Stopped" ;
VAL_TABLE_ SRRLRCODPVOTk2DynPrpStsAuth 0 "Stopped" 1 "Not Stopped" ;
VAL_TABLE_ SRRLRCODPVOTk3DynPrpStsAuth 0 "Stopped" 1 "Not Stopped" ;
VAL_TABLE_ SRRLRCODPVOTk4DynPrpStsAuth 0 "Stopped" 1 "Not Stopped" ;
VAL_TABLE_ SRRLRCODPVOTk5DynPrpStsAuth 0 "Stopped" 1 "Not Stopped" ;
VAL_TABLE_ SRRLRCODPVOTk6DynPrpStsAuth 0 "Stopped" 1 "Not Stopped" ;
VAL_TABLE_ SRRLRCODPVOTk7DynPrpStsAuth 0 "Stopped" 1 "Not Stopped" ;
VAL_TABLE_ SRRLRCODPVOTk8DynPrpStsAuth 0 "Stopped" 1 "Not Stopped" ;
VAL_TABLE_ SRRLRCODPVOTk9DynPrpStsAuth 0 "Stopped" 1 "Not Stopped" ;
VAL_TABLE_ SRRRRODPIOTk10TypAuth 0 "Unknown" 1 "Guard Rail" 2 "Tunnel" 3 "Traffic Sign" 4 "Bridge" 5 "Pole" ;
VAL_TABLE_ SRRRRODPIOTk1TypAuth 0 "Unknown" 1 "Guard Rail" 2 "Tunnel" 3 "Traffic Sign" 4 "Bridge" 5 "Pole" ;
VAL_TABLE_ SRRRRODPIOTk2TypAuth 0 "Unknown" 1 "Guard Rail" 2 "Tunnel" 3 "Traffic Sign" 4 "Bridge" 5 "Pole" ;
VAL_TABLE_ SRRRRODPIOTk3TypAuth 0 "Unknown" 1 "Guard Rail" 2 "Tunnel" 3 "Traffic Sign" 4 "Bridge" 5 "Pole" ;
VAL_TABLE_ SRRRRODPIOTk4TypAuth 0 "Unknown" 1 "Guard Rail" 2 "Tunnel" 3 "Traffic Sign" 4 "Bridge" 5 "Pole" ;
VAL_TABLE_ SRRRRODPIOTk5TypAuth 0 "Unknown" 1 "Guard Rail" 2 "Tunnel" 3 "Traffic Sign" 4 "Bridge" 5 "Pole" ;
VAL_TABLE_ SRRRRODPIOTk6TypAuth 0 "Unknown" 1 "Guard Rail" 2 "Tunnel" 3 "Traffic Sign" 4 "Bridge" 5 "Pole" ;
VAL_TABLE_ SRRRRODPIOTk7TypAuth 0 "Unknown" 1 "Guard Rail" 2 "Tunnel" 3 "Traffic Sign" 4 "Bridge" 5 "Pole" ;
VAL_TABLE_ SRRRRODPIOTk8TypAuth 0 "Unknown" 1 "Guard Rail" 2 "Tunnel" 3 "Traffic Sign" 4 "Bridge" 5 "Pole" ;
VAL_TABLE_ SRRRRODPIOTk9TypAuth 0 "Unknown" 1 "Guard Rail" 2 "Tunnel" 3 "Traffic Sign" 4 "Bridge" 5 "Pole" ;
VAL_TABLE_ SRRRRODPPOTk1DynPrpAuth 0 "Has Never Moved" 1 "Has Moved But Currently Stopped" 2 "Moving In Same Direction As Host" 3 "Moving In Opposite Direction As Host" 4 "Crossing Path" ;
VAL_TABLE_ SRRRRODPPOTk2DynPrpAuth 0 "Has Never Moved" 1 "Has Moved But Currently Stopped" 2 "Moving In Same Direction As Host" 3 "Moving In Opposite Direction As Host" 4 "Crossing Path" ;
VAL_TABLE_ SRRRRODPPOTk3DynPrpAuth 0 "Has Never Moved" 1 "Has Moved But Currently Stopped" 2 "Moving In Same Direction As Host" 3 "Moving In Opposite Direction As Host" 4 "Crossing Path" ;
VAL_TABLE_ SRRRRODPPOTk4DynPrpAuth 0 "Has Never Moved" 1 "Has Moved But Currently Stopped" 2 "Moving In Same Direction As Host" 3 "Moving In Opposite Direction As Host" 4 "Crossing Path" ;
VAL_TABLE_ SRRRRODPPOTk5DynPrpAuth 0 "Has Never Moved" 1 "Has Moved But Currently Stopped" 2 "Moving In Same Direction As Host" 3 "Moving In Opposite Direction As Host" 4 "Crossing Path" ;
VAL_TABLE_ SRRRRODPREOTk1TypAuth 0 "Unknown" 1 "Barriers" 2 "Guard Rails" 3 "Bridge Abutments" 4 "Edge of Road" 5 "Open Area" ;
VAL_TABLE_ SRRRRODPREOTk2TypAuth 0 "Unknown" 1 "Barriers" 2 "Guard Rails" 3 "Bridge Abutments" 4 "Edge of Road" 5 "Open Area" ;
VAL_TABLE_ SRRRRODPREOTk3TypAuth 0 "Unknown" 1 "Barriers" 2 "Guard Rails" 3 "Bridge Abutments" 4 "Edge of Road" 5 "Open Area" ;
VAL_TABLE_ SRRRRODPRdTypAuth 0 "Unknown" 1 "City" 2 "Secondary Road" 3 "Highway" 4 "Construction Zone Entry" 5 "Construction Zone Exit" ;
VAL_TABLE_ SRRRRODPVOTk10DynPrpAuth 0 "Has Never Moved" 1 "Moving In Same Direction As Host" 2 "Moving In Opposite Direction As Host" 3 "Crossing From Left To Right" 4 "Crossing From Right To Left" ;
VAL_TABLE_ SRRRRODPVOTk1DynPrpAuth 0 "Has Never Moved" 1 "Moving In Same Direction As Host" 2 "Moving In Opposite Direction As Host" 3 "Crossing From Left To Right" 4 "Crossing From Right To Left" ;
VAL_TABLE_ SRRRRODPVOTk2DynPrpAuth 0 "Has Never Moved" 1 "Moving In Same Direction As Host" 2 "Moving In Opposite Direction As Host" 3 "Crossing From Left To Right" 4 "Crossing From Right To Left" ;
VAL_TABLE_ SRRRRODPVOTk3DynPrpAuth 0 "Has Never Moved" 1 "Moving In Same Direction As Host" 2 "Moving In Opposite Direction As Host" 3 "Crossing From Left To Right" 4 "Crossing From Right To Left" ;
VAL_TABLE_ SRRRRODPVOTk4DynPrpAuth 0 "Has Never Moved" 1 "Moving In Same Direction As Host" 2 "Moving In Opposite Direction As Host" 3 "Crossing From Left To Right" 4 "Crossing From Right To Left" ;
VAL_TABLE_ SRRRRODPVOTk5DynPrpAuth 0 "Has Never Moved" 1 "Moving In Same Direction As Host" 2 "Moving In Opposite Direction As Host" 3 "Crossing From Left To Right" 4 "Crossing From Right To Left" ;
VAL_TABLE_ SRRRRODPVOTk6DynPrpAuth 0 "Has Never Moved" 1 "Moving In Same Direction As Host" 2 "Moving In Opposite Direction As Host" 3 "Crossing From Left To Right" 4 "Crossing From Right To Left" ;
VAL_TABLE_ SRRRRODPVOTk7DynPrpAuth 0 "Has Never Moved" 1 "Moving In Same Direction As Host" 2 "Moving In Opposite Direction As Host" 3 "Crossing From Left To Right" 4 "Crossing From Right To Left" ;
VAL_TABLE_ SRRRRODPVOTk8DynPrpAuth 0 "Has Never Moved" 1 "Moving In Same Direction As Host" 2 "Moving In Opposite Direction As Host" 3 "Crossing From Left To Right" 4 "Crossing From Right To Left" ;
VAL_TABLE_ SRRRRODPVOTk9DynPrpAuth 0 "Has Never Moved" 1 "Moving In Same Direction As Host" 2 "Moving In Opposite Direction As Host" 3 "Crossing From Left To Right" 4 "Crossing From Right To Left" ;
VAL_TABLE_ SRRRRODPConstrArDtnCnfdAuth 0 "Highly Speculative" 1 "Speculative" 2 "Confident" 3 "Highly Confident" ;
VAL_TABLE_ SRRRRODPConstrArDtnStsAuth 0 "Not Detected" 1 "Detected" 2 "Unknown" ;
VAL_TABLE_ SRRRRODPIOTk10CnfdStsAuth 0 "Highly Speculative" 1 "Speculative" 2 "Confident" 3 "Highly Confident" ;
VAL_TABLE_ SRRRRODPIOTk10ElvtnAuth 0 "Not Elevated" 1 "Elevation Speculative" 2 "Elevation Confident" 3 "Elevation Very Confident" ;
VAL_TABLE_ SRRRRODPIOTk10MStsAuth 0 "No Object" 1 "New Object" 2 "Latent Track Not Detected this Cycle" 3 "Measured this Cycle" ;
VAL_TABLE_ SRRRRODPIOTk10TypCnfdAuth 0 "Highly Speculative" 1 "Speculative" 2 "Confident" 3 "Highly Confident" ;
VAL_TABLE_ SRRRRODPIOTk1CnfdStsAuth 0 "Highly Speculative" 1 "Speculative" 2 "Confident" 3 "Highly Confident" ;
VAL_TABLE_ SRRRRODPIOTk1ElvtnAuth 0 "Not Elevated" 1 "Elevation Speculative" 2 "Elevation Confident" 3 "Elevation Very Confident" ;
VAL_TABLE_ SRRRRODPIOTk1MStsAuth 0 "No Object" 1 "New Object" 2 "Latent Track Not Detected this Cycle" 3 "Measured this Cycle" ;
VAL_TABLE_ SRRRRODPIOTk1TypCnfdAuth 0 "Highly Speculative" 1 "Speculative" 2 "Confident" 3 "Highly Confident" ;
VAL_TABLE_ SRRRRODPIOTk2CnfdStsAuth 0 "Highly Speculative" 1 "Speculative" 2 "Confident" 3 "Highly Confident" ;
VAL_TABLE_ SRRRRODPIOTk2ElvtnAuth 0 "Not Elevated" 1 "Elevation Speculative" 2 "Elevation Confident" 3 "Elevation Very Confident" ;
VAL_TABLE_ SRRRRODPIOTk2MStsAuth 0 "No Object" 1 "New Object" 2 "Latent Track Not Detected this Cycle" 3 "Measured this Cycle" ;
VAL_TABLE_ SRRRRODPIOTk2TypCnfdAuth 0 "Highly Speculative" 1 "Speculative" 2 "Confident" 3 "Highly Confident" ;
VAL_TABLE_ SRRRRODPIOTk3CnfdStsAuth 0 "Highly Speculative" 1 "Speculative" 2 "Confident" 3 "Highly Confident" ;
VAL_TABLE_ SRRRRODPIOTk3ElvtnAuth 0 "Not Elevated" 1 "Elevation Speculative" 2 "Elevation Confident" 3 "Elevation Very Confident" ;
VAL_TABLE_ SRRRRODPIOTk3MStsAuth 0 "No Object" 1 "New Object" 2 "Latent Track Not Detected this Cycle" 3 "Measured this Cycle" ;
VAL_TABLE_ SRRRRODPIOTk3TypCnfdAuth 0 "Highly Speculative" 1 "Speculative" 2 "Confident" 3 "Highly Confident" ;
VAL_TABLE_ SRRRRODPIOTk4CnfdStsAuth 0 "Highly Speculative" 1 "Speculative" 2 "Confident" 3 "Highly Confident" ;
VAL_TABLE_ SRRRRODPIOTk4ElvtnAuth 0 "Not Elevated" 1 "Elevation Speculative" 2 "Elevation Confident" 3 "Elevation Very Confident" ;
VAL_TABLE_ SRRRRODPIOTk4MStsAuth 0 "No Object" 1 "New Object" 2 "Latent Track Not Detected this Cycle" 3 "Measured this Cycle" ;
VAL_TABLE_ SRRRRODPIOTk4TypCnfdAuth 0 "Highly Speculative" 1 "Speculative" 2 "Confident" 3 "Highly Confident" ;
VAL_TABLE_ SRRRRODPIOTk5CnfdStsAuth 0 "Highly Speculative" 1 "Speculative" 2 "Confident" 3 "Highly Confident" ;
VAL_TABLE_ SRRRRODPIOTk5ElvtnAuth 0 "Not Elevated" 1 "Elevation Speculative" 2 "Elevation Confident" 3 "Elevation Very Confident" ;
VAL_TABLE_ SRRRRODPIOTk5MStsAuth 0 "No Object" 1 "New Object" 2 "Latent Track Not Detected this Cycle" 3 "Measured this Cycle" ;
VAL_TABLE_ SRRRRODPIOTk5TypCnfdAuth 0 "Highly Speculative" 1 "Speculative" 2 "Confident" 3 "Highly Confident" ;
VAL_TABLE_ SRRRRODPIOTk6CnfdStsAuth 0 "Highly Speculative" 1 "Speculative" 2 "Confident" 3 "Highly Confident" ;
VAL_TABLE_ SRRRRODPIOTk6ElvtnAuth 0 "Not Elevated" 1 "Elevation Speculative" 2 "Elevation Confident" 3 "Elevation Very Confident" ;
VAL_TABLE_ SRRRRODPIOTk6MStsAuth 0 "No Object" 1 "New Object" 2 "Latent Track Not Detected this Cycle" 3 "Measured this Cycle" ;
VAL_TABLE_ SRRRRODPIOTk6TypCnfdAuth 0 "Highly Speculative" 1 "Speculative" 2 "Confident" 3 "Highly Confident" ;
VAL_TABLE_ SRRRRODPIOTk7CnfdStsAuth 0 "Highly Speculative" 1 "Speculative" 2 "Confident" 3 "Highly Confident" ;
VAL_TABLE_ SRRRRODPIOTk7ElvtnAuth 0 "Not Elevated" 1 "Elevation Speculative" 2 "Elevation Confident" 3 "Elevation Very Confident" ;
VAL_TABLE_ SRRRRODPIOTk7MStsAuth 0 "No Object" 1 "New Object" 2 "Latent Track Not Detected this Cycle" 3 "Measured this Cycle" ;
VAL_TABLE_ SRRRRODPIOTk7TypCnfdAuth 0 "Highly Speculative" 1 "Speculative" 2 "Confident" 3 "Highly Confident" ;
VAL_TABLE_ SRRRRODPIOTk8CnfdStsAuth 0 "Highly Speculative" 1 "Speculative" 2 "Confident" 3 "Highly Confident" ;
VAL_TABLE_ SRRRRODPIOTk8ElvtnAuth 0 "Not Elevated" 1 "Elevation Speculative" 2 "Elevation Confident" 3 "Elevation Very Confident" ;
VAL_TABLE_ SRRRRODPIOTk8MStsAuth 0 "No Object" 1 "New Object" 2 "Latent Track Not Detected this Cycle" 3 "Measured this Cycle" ;
VAL_TABLE_ SRRRRODPIOTk8TypCnfdAuth 0 "Highly Speculative" 1 "Speculative" 2 "Confident" 3 "Highly Confident" ;
VAL_TABLE_ SRRRRODPIOTk9CnfdStsAuth 0 "Highly Speculative" 1 "Speculative" 2 "Confident" 3 "Highly Confident" ;
VAL_TABLE_ SRRRRODPIOTk9ElvtnAuth 0 "Not Elevated" 1 "Elevation Speculative" 2 "Elevation Confident" 3 "Elevation Very Confident" ;
VAL_TABLE_ SRRRRODPIOTk9MStsAuth 0 "No Object" 1 "New Object" 2 "Latent Track Not Detected this Cycle" 3 "Measured this Cycle" ;
VAL_TABLE_ SRRRRODPIOTk9TypCnfdAuth 0 "Highly Speculative" 1 "Speculative" 2 "Confident" 3 "Highly Confident" ;
VAL_TABLE_ SRRRRODPMdCmdStsAuth 0 "Not Radiating" 1 "Reporting Object Data" 2 "Not Reporting Object Data" ;
VAL_TABLE_ SRRRRODPPOTk1CnfdStsAuth 0 "Highly Speculative" 1 "Speculative" 2 "Confident" 3 "Highly Confident" ;
VAL_TABLE_ SRRRRODPPOTk1MStsAuth 0 "No Object" 1 "New Object" 2 "Latent Track Not Detected this Cycle" 3 "Measured this Cycle" ;
VAL_TABLE_ SRRRRODPPOTk1TypAuth 0 "Unknown" 1 "Pedestrian" 2 "Bicycle" ;
VAL_TABLE_ SRRRRODPPOTk1TypCnfdAuth 0 "Highly Speculative" 1 "Speculative" 2 "Confident" 3 "Highly Confident" ;
VAL_TABLE_ SRRRRODPPOTk2CnfdStsAuth 0 "Highly Speculative" 1 "Speculative" 2 "Confident" 3 "Highly Confident" ;
VAL_TABLE_ SRRRRODPPOTk2MStsAuth 0 "No Object" 1 "New Object" 2 "Latent Track Not Detected this Cycle" 3 "Measured this Cycle" ;
VAL_TABLE_ SRRRRODPPOTk2TypAuth 0 "Unknown" 1 "Pedestrian" 2 "Bicycle" ;
VAL_TABLE_ SRRRRODPPOTk2TypCnfdAuth 0 "Highly Speculative" 1 "Speculative" 2 "Confident" 3 "Highly Confident" ;
VAL_TABLE_ SRRRRODPPOTk3CnfdStsAuth 0 "Highly Speculative" 1 "Speculative" 2 "Confident" 3 "Highly Confident" ;
VAL_TABLE_ SRRRRODPPOTk3MStsAuth 0 "No Object" 1 "New Object" 2 "Latent Track Not Detected this Cycle" 3 "Measured this Cycle" ;
VAL_TABLE_ SRRRRODPPOTk3TypAuth 0 "Unknown" 1 "Pedestrian" 2 "Bicycle" ;
VAL_TABLE_ SRRRRODPPOTk3TypCnfdAuth 0 "Highly Speculative" 1 "Speculative" 2 "Confident" 3 "Highly Confident" ;
VAL_TABLE_ SRRRRODPPOTk4CnfdStsAuth 0 "Highly Speculative" 1 "Speculative" 2 "Confident" 3 "Highly Confident" ;
VAL_TABLE_ SRRRRODPPOTk4MStsAuth 0 "No Object" 1 "New Object" 2 "Latent Track Not Detected this Cycle" 3 "Measured this Cycle" ;
VAL_TABLE_ SRRRRODPPOTk4TypAuth 0 "Unknown" 1 "Pedestrian" 2 "Bicycle" ;
VAL_TABLE_ SRRRRODPPOTk4TypCnfdAuth 0 "Highly Speculative" 1 "Speculative" 2 "Confident" 3 "Highly Confident" ;
VAL_TABLE_ SRRRRODPPOTk5CnfdStsAuth 0 "Highly Speculative" 1 "Speculative" 2 "Confident" 3 "Highly Confident" ;
VAL_TABLE_ SRRRRODPPOTk5MStsAuth 0 "No Object" 1 "New Object" 2 "Latent Track Not Detected this Cycle" 3 "Measured this Cycle" ;
VAL_TABLE_ SRRRRODPPOTk5TypAuth 0 "Unknown" 1 "Pedestrian" 2 "Bicycle" ;
VAL_TABLE_ SRRRRODPPOTk5TypCnfdAuth 0 "Highly Speculative" 1 "Speculative" 2 "Confident" 3 "Highly Confident" ;
VAL_TABLE_ SRRRRODPREOTk1CnfdStsAuth 0 "Highly Speculative" 1 "Speculative" 2 "Confident" 3 "Highly Confident" ;
VAL_TABLE_ SRRRRODPREOTk1TypCnfdAuth 0 "Highly Speculative" 1 "Speculative" 2 "Confident" 3 "Highly Confident" ;
VAL_TABLE_ SRRRRODPREOTk2CnfdStsAuth 0 "Highly Speculative" 1 "Speculative" 2 "Confident" 3 "Highly Confident" ;
VAL_TABLE_ SRRRRODPREOTk2TypCnfdAuth 0 "Highly Speculative" 1 "Speculative" 2 "Confident" 3 "Highly Confident" ;
VAL_TABLE_ SRRRRODPREOTk3CnfdStsAuth 0 "Highly Speculative" 1 "Speculative" 2 "Confident" 3 "Highly Confident" ;
VAL_TABLE_ SRRRRODPREOTk3TypCnfdAuth 0 "Highly Speculative" 1 "Speculative" 2 "Confident" 3 "Highly Confident" ;
VAL_TABLE_ SRRRRODPRdTypCnfdAuth 0 "Highly Speculative" 1 "Speculative" 2 "Confident" 3 "Highly Confident" ;
VAL_TABLE_ SRRRRODPSwpBndwdthStsAuth 0 "Mode A" 1 "Mode B" 2 "Mode C" 3 "Mode D" ;
VAL_TABLE_ SRRRRODPVOTk10CnfdStsAuth 0 "Highly Speculative" 1 "Speculative" 2 "Confident" 3 "Highly Confident" ;
VAL_TABLE_ SRRRRODPVOTk10MStsAuth 0 "No Object" 1 "New Object" 2 "Latent Track Not Detected this Cycle" 3 "Measured this Cycle" ;
VAL_TABLE_ SRRRRODPVOTk10TypCnfdAuth 0 "Highly Speculative" 1 "Speculative" 2 "Confident" 3 "Highly Confident" ;
VAL_TABLE_ SRRRRODPVOTk1CnfdStsAuth 0 "Highly Speculative" 1 "Speculative" 2 "Confident" 3 "Highly Confident" ;
VAL_TABLE_ SRRRRODPVOTk1MStsAuth 0 "No Object" 1 "New Object" 2 "Latent Track Not Detected this Cycle" 3 "Measured this Cycle" ;
VAL_TABLE_ SRRRRODPVOTk1TypCnfdAuth 0 "Highly Speculative" 1 "Speculative" 2 "Confident" 3 "Highly Confident" ;
VAL_TABLE_ SRRRRODPVOTk2CnfdStsAuth 0 "Highly Speculative" 1 "Speculative" 2 "Confident" 3 "Highly Confident" ;
VAL_TABLE_ SRRRRODPVOTk2MStsAuth 0 "No Object" 1 "New Object" 2 "Latent Track Not Detected this Cycle" 3 "Measured this Cycle" ;
VAL_TABLE_ SRRRRODPVOTk2TypCnfdAuth 0 "Highly Speculative" 1 "Speculative" 2 "Confident" 3 "Highly Confident" ;
VAL_TABLE_ SRRRRODPVOTk3CnfdStsAuth 0 "Highly Speculative" 1 "Speculative" 2 "Confident" 3 "Highly Confident" ;
VAL_TABLE_ SRRRRODPVOTk3MStsAuth 0 "No Object" 1 "New Object" 2 "Latent Track Not Detected this Cycle" 3 "Measured this Cycle" ;
VAL_TABLE_ SRRRRODPVOTk3TypCnfdAuth 0 "Highly Speculative" 1 "Speculative" 2 "Confident" 3 "Highly Confident" ;
VAL_TABLE_ SRRRRODPVOTk4CnfdStsAuth 0 "Highly Speculative" 1 "Speculative" 2 "Confident" 3 "Highly Confident" ;
VAL_TABLE_ SRRRRODPVOTk4MStsAuth 0 "No Object" 1 "New Object" 2 "Latent Track Not Detected this Cycle" 3 "Measured this Cycle" ;
VAL_TABLE_ SRRRRODPVOTk4TypCnfdAuth 0 "Highly Speculative" 1 "Speculative" 2 "Confident" 3 "Highly Confident" ;
VAL_TABLE_ SRRRRODPVOTk5CnfdStsAuth 0 "Highly Speculative" 1 "Speculative" 2 "Confident" 3 "Highly Confident" ;
VAL_TABLE_ SRRRRODPVOTk5MStsAuth 0 "No Object" 1 "New Object" 2 "Latent Track Not Detected this Cycle" 3 "Measured this Cycle" ;
VAL_TABLE_ SRRRRODPVOTk5TypCnfdAuth 0 "Highly Speculative" 1 "Speculative" 2 "Confident" 3 "Highly Confident" ;
VAL_TABLE_ SRRRRODPVOTk6CnfdStsAuth 0 "Highly Speculative" 1 "Speculative" 2 "Confident" 3 "Highly Confident" ;
VAL_TABLE_ SRRRRODPVOTk6MStsAuth 0 "No Object" 1 "New Object" 2 "Latent Track Not Detected this Cycle" 3 "Measured this Cycle" ;
VAL_TABLE_ SRRRRODPVOTk6TypCnfdAuth 0 "Highly Speculative" 1 "Speculative" 2 "Confident" 3 "Highly Confident" ;
VAL_TABLE_ SRRRRODPVOTk7CnfdStsAuth 0 "Highly Speculative" 1 "Speculative" 2 "Confident" 3 "Highly Confident" ;
VAL_TABLE_ SRRRRODPVOTk7MStsAuth 0 "No Object" 1 "New Object" 2 "Latent Track Not Detected this Cycle" 3 "Measured this Cycle" ;
VAL_TABLE_ SRRRRODPVOTk7TypCnfdAuth 0 "Highly Speculative" 1 "Speculative" 2 "Confident" 3 "Highly Confident" ;
VAL_TABLE_ SRRRRODPVOTk8CnfdStsAuth 0 "Highly Speculative" 1 "Speculative" 2 "Confident" 3 "Highly Confident" ;
VAL_TABLE_ SRRRRODPVOTk8MStsAuth 0 "No Object" 1 "New Object" 2 "Latent Track Not Detected this Cycle" 3 "Measured this Cycle" ;
VAL_TABLE_ SRRRRODPVOTk8TypCnfdAuth 0 "Highly Speculative" 1 "Speculative" 2 "Confident" 3 "Highly Confident" ;
VAL_TABLE_ SRRRRODPVOTk9CnfdStsAuth 0 "Highly Speculative" 1 "Speculative" 2 "Confident" 3 "Highly Confident" ;
VAL_TABLE_ SRRRRODPVOTk9MStsAuth 0 "No Object" 1 "New Object" 2 "Latent Track Not Detected this Cycle" 3 "Measured this Cycle" ;
VAL_TABLE_ SRRRRODPVOTk9TypCnfdAuth 0 "Highly Speculative" 1 "Speculative" 2 "Confident" 3 "Highly Confident" ;
VAL_TABLE_ SRRRRODPAcqTmStmAuth_Inv 0 "FALSE" 1 "TRUE" ;
VAL_TABLE_ SRRRRODPServRqrdAuth 0 "FALSE" 1 "TRUE" ;
VAL_TABLE_ SRRRRODPSnsrBlckdAuth 0 "FALSE" 1 "TRUE" ;
VAL_TABLE_ SRRRRODPSnsrUnvAuth 0 "FALSE" 1 "TRUE" ;
VAL_TABLE_ SRRRRODPVOTk10DynPrpStsAuth 0 "Stopped" 1 "Not Stopped" ;
VAL_TABLE_ SRRRRODPVOTk1DynPrpStsAuth 0 "Stopped" 1 "Not Stopped" ;
VAL_TABLE_ SRRRRODPVOTk2DynPrpStsAuth 0 "Stopped" 1 "Not Stopped" ;
VAL_TABLE_ SRRRRODPVOTk3DynPrpStsAuth 0 "Stopped" 1 "Not Stopped" ;
VAL_TABLE_ SRRRRODPVOTk4DynPrpStsAuth 0 "Stopped" 1 "Not Stopped" ;
VAL_TABLE_ SRRRRODPVOTk5DynPrpStsAuth 0 "Stopped" 1 "Not Stopped" ;
VAL_TABLE_ SRRRRODPVOTk6DynPrpStsAuth 0 "Stopped" 1 "Not Stopped" ;
VAL_TABLE_ SRRRRODPVOTk7DynPrpStsAuth 0 "Stopped" 1 "Not Stopped" ;
VAL_TABLE_ SRRRRODPVOTk8DynPrpStsAuth 0 "Stopped" 1 "Not Stopped" ;
VAL_TABLE_ SRRRRODPVOTk9DynPrpStsAuth 0 "Stopped" 1 "Not Stopped" ;
VAL_TABLE_ TEGP_TrnsEstGrAuth 0 "Not Supported" 1 "First Gear" 2 "Second Gear" 3 "Third Gear" 4 "Fourth Gear" 5 "Fifth Gear" 6 "Sixth Gear" 7 "Seventh Gear" 8 "Eighth Gear" 9 "Ninth Gear" 10 "Tenth Gear" 11 "Unused and Reserved" 12 "CVT Forward Gear" 13 "Neutral Gear" 14 "Reverse Gear" 15 "Park Gear" ;
VAL_TABLE_ TEGP_TrnsEngdStAuth_Inv 0 "FALSE" 1 "TRUE" ;
VAL_TABLE_ TEGP_TrnsEngdStAuth 0 "Transmission Not Engaged" 1 "Transmission Engaged in Forward" 2 "Transmission Engaged in Reverse" 3 "Operating State Not Reached" ;
VAL_TABLE_ TEGP_TransCmndGrAuth 0 "Not Supported" 1 "First Gear" 2 "Second Gear" 3 "Third Gear" 4 "Fourth Gear" 5 "Fifth Gear" 6 "Sixth Gear" 7 "Seventh Gear" 8 "Eighth Gear" 9 "Ninth Gear" 10 "Tenth Gear" 11 "Unused and Reserved" 12 "CVT Forward Gear" 13 "Neutral Gear" 14 "Reverse Gear" 15 "Park Gear" ;
VAL_TABLE_ TEGP_TrnsShftLvrPstnAuth 0 "Between Ranges" 1 "Park Range" 2 "Reverse Range" 3 "Neutral Range" 4 "Forward Range A" 5 "Forward Range B" 6 "Forward Range C" 7 "Forward Range D" 8 "Forward Range E" 9 "Forward Range F" 10 "Forward Range G" 11 "Forward Range H" 12 "Forward Range I" 13 "Forward Range J" 14 "Lever Position Unknown" ;
VAL_TABLE_ TEGP_TrnsEstGrAuth_Inv 0 "FALSE" 1 "TRUE" ;
VAL_TABLE_ DrvMtrInvrtUntAShtdnCmnd 0 "FALSE" 1 "TRUE" ;
VAL_TABLE_ TEGP_TrnsShftLvrPstnAuth_Inv 0 "FALSE" 1 "TRUE" ;
VAL_TABLE_ UPM_CAN_8_ClscCANHrtBtActv 0 "FALSE" 1 "TRUE" ;
VAL_TABLE_ VSADP_RdcdPwrIndOnAuth 0 "FALSE" 1 "TRUE" ;
VAL_TABLE_ VSADP_FuelModeStsAuth 0 "Unknown" 1 "Gasoline Mode" 2 "Natural Gas Mode" 3 "Liquified Petroleum Gas Mode" 4 "Alternative Fuel Cut-off Active" ;
VAL_TABLE_ EngEmsRltMlfIndRq 0 "Continuous Indication" 1 "No Indication" 2 "Flashing 1 Hertz Indication" 3 "Flashing 2 Hertz Indication" 4 "Flashing 0.5 Hertz Indication" ;
VAL_TABLE_ VSADP_VehSpdAvgDrvnSrcAuth 0 "Transmission Output Speed" 1 "Wheel Speed" ;
VAL_TABLE_ VSADP_VehSpdAvgDrvnAuth_Inv 0 "FALSE" 1 "TRUE" ;

BO_ 2147745829 ACP2_MCU_CAN8_ClscCANHrtBtActv_P: 1 ACP2_MCU
 SG_ ACP2_MCU_CAN_8_ClscCANHrtBtActv : 7|1@0+ (1,0) [0|1] "" CGM

BO_ 2147745830 ACP3_MCU_CAN8_ClscCANHrtBtActv_P: 1 EOCM_HC_Superset
 SG_ ACP3_MCU_CAN8_ClscCANHrtBtActv : 7|1@0+ (1,0) [0|1] "" CGM

BO_ 2147745831 ACP4_MCU_CAN8_ClscCANHrtBtActv_P: 1 EOCM_HC_Superset
 SG_ ACP4_MCU_CAN8_ClscCANHrtBtActv : 7|1@0+ (1,0) [0|1] "" CGM

BO_ 512 AdpLgtObjInfo1_PDU01: 48 ACP2_MCU
 SG_ ALOI1_AcqTmStm : 5|11@0+ (1,0) [0|2047] "ms" Vector__XXX
 SG_ ALOI1_ARC : 7|2@0+ (1,0) [0|3] "" Vector__XXX
 SG_ ALOI1_AzmRateTk1 : 9|11@0+ (0.125,-128) [-128|127.875] "deg/s" Vector__XXX
 SG_ ALOI1_AcqTmStm_Inv : 10|1@0+ (1,0) [0|1] "" Vector__XXX
 SG_ ALOI1_AzmRateTk2 : 30|11@0+ (0.125,-128) [-128|127.875] "deg/s" Vector__XXX
 SG_ ALOI1_AzmRateTk3 : 35|11@0+ (0.125,-128) [-128|127.875] "deg/s" Vector__XXX
 SG_ ALOI1_AzmRateTk4 : 40|11@0+ (0.125,-128) [-128|127.875] "deg/s" Vector__XXX
 SG_ ALOI1_AzmTk1 : 61|11@0+ (0.05,-51.2) [-51.2|51.15] "deg" Vector__XXX
 SG_ ALOI1_AzmTk2 : 66|11@0+ (0.05,-51.2) [-51.2|51.15] "deg" Vector__XXX
 SG_ ALOI1_AzmTk3 : 87|11@0+ (0.05,-51.2) [-51.2|51.15] "deg" Vector__XXX
 SG_ ALOI1_AzmTk4 : 92|11@0+ (0.05,-51.2) [-51.2|51.15] "deg" Vector__XXX
 SG_ ALOI1_CnfdTk1 : 97|2@0+ (1,0) [0|3] "" Vector__XXX
 SG_ ALOI1_DirTk1 : 105|3@0+ (1,0) [0|4] "" Vector__XXX
 SG_ ALOI1_CnfdTk4 : 107|2@0+ (1,0) [0|3] "" Vector__XXX
 SG_ ALOI1_CnfdTk3 : 109|2@0+ (1,0) [0|3] "" Vector__XXX
 SG_ ALOI1_CnfdTk2 : 111|2@0+ (1,0) [0|3] "" Vector__XXX
 SG_ ALOI1_DirTk4 : 112|3@0+ (1,0) [0|4] "" Vector__XXX
 SG_ ALOI1_DirTk3 : 115|3@0+ (1,0) [0|4] "" Vector__XXX
 SG_ ALOI1_DirTk2 : 118|3@0+ (1,0) [0|4] "" Vector__XXX
 SG_ ALOI1_IDTk1 : 125|6@0+ (1,0) [0|63] "" Vector__XXX
 SG_ ALOI1_IDTk3 : 129|6@0+ (1,0) [0|63] "" Vector__XXX
 SG_ ALOI1_IDTk2 : 135|6@0+ (1,0) [0|63] "" Vector__XXX
 SG_ ALOI1_IDTk4 : 139|6@0+ (1,0) [0|63] "" Vector__XXX
 SG_ ALOI1_MeasStsTk3 : 145|2@0+ (1,0) [0|3] "" Vector__XXX
 SG_ ALOI1_MeasStsTk2 : 147|2@0+ (1,0) [0|3] "" Vector__XXX
 SG_ ALOI1_MeasStsTk1 : 149|2@0+ (1,0) [0|3] "" Vector__XXX
 SG_ ALOI1_RdSigGlrngTk1 : 157|7@0+ (1,0) [0|127] "%" Vector__XXX
 SG_ ALOI1_MeasStsTk4 : 159|2@0+ (1,0) [0|3] "" Vector__XXX
 SG_ ALOI1_RdSigGlrngTk2 : 166|7@0+ (1,0) [0|127] "%" Vector__XXX
 SG_ ALOI1_RdSigGlrngTk4 : 168|7@0+ (1,0) [0|127] "%" Vector__XXX
 SG_ ALOI1_RdSigGlrngTk3 : 175|7@0+ (1,0) [0|127] "%" Vector__XXX
 SG_ ALOI1_RltvLnTk1 : 177|2@0+ (1,0) [0|3] "" Vector__XXX
 SG_ ALOI1_RngTk1 : 185|16@0+ (0.02,0) [0|1310.7] "m" Vector__XXX
 SG_ ALOI1_RltvLnTk4 : 187|2@0+ (1,0) [0|3] "" Vector__XXX
 SG_ ALOI1_RltvLnTk3 : 189|2@0+ (1,0) [0|3] "" Vector__XXX
 SG_ ALOI1_RltvLnTk2 : 191|2@0+ (1,0) [0|3] "" Vector__XXX
 SG_ ALOI1_RngTk2 : 200|16@0+ (0.02,0) [0|1310.7] "m" Vector__XXX
 SG_ ALOI1_RngTk1_Inv : 201|1@0+ (1,0) [0|1] "" Vector__XXX
 SG_ ALOI1_RngTk2_Inv : 216|1@0+ (1,0) [0|1] "" Vector__XXX
 SG_ ALOI1_RngTk3 : 231|16@0+ (0.02,0) [0|1310.7] "m" Vector__XXX
 SG_ ALOI1_RngTk4 : 246|16@0+ (0.02,0) [0|1310.7] "m" Vector__XXX
 SG_ ALOI1_RngTk3_Inv : 247|1@0+ (1,0) [0|1] "" Vector__XXX
 SG_ ALOI1_TypTk2 : 257|4@0+ (1,0) [0|12] "" Vector__XXX
 SG_ ALOI1_TypTk1 : 261|4@0+ (1,0) [0|12] "" Vector__XXX
 SG_ ALOI1_RngTk4_Inv : 262|1@0+ (1,0) [0|1] "" Vector__XXX
 SG_ ALOI1_TypTk4 : 265|4@0+ (1,0) [0|12] "" Vector__XXX
 SG_ ALOI1_TypTk3 : 269|4@0+ (1,0) [0|12] "" Vector__XXX
 SG_ ALOI1_VertPstnTk1 : 277|6@0+ (0.25,-3) [-3|12.75] "deg" Vector__XXX
 SG_ ALOI1_VertPstnTk3 : 281|6@0+ (0.25,-3) [-3|12.75] "deg" Vector__XXX
 SG_ ALOI1_VertPstnTk2 : 287|6@0+ (0.25,-3) [-3|12.75] "deg" Vector__XXX
 SG_ ALOI1_VertPstnTk4 : 291|6@0+ (0.25,-3) [-3|12.75] "deg" Vector__XXX
 SG_ ALOI1_WdthTk1 : 301|11@0+ (0.1,0) [0|204.7] "deg" Vector__XXX
 SG_ ALOI1_WdthTk2 : 306|11@0+ (0.1,0) [0|204.7] "deg" Vector__XXX
 SG_ ALOI1_WdthTk3 : 327|11@0+ (0.1,0) [0|204.7] "deg" Vector__XXX
 SG_ ALOI1_WdthTk4 : 332|11@0+ (0.1,0) [0|204.7] "deg" Vector__XXX

BO_ 514 AdpLgtObjInfo2_PDU02: 48 ACP2_MCU
 SG_ ALOI2_AcqTmStm : 5|11@0+ (1,0) [0|2047] "ms" Vector__XXX
 SG_ ALOI2_ARC : 7|2@0+ (1,0) [0|3] "" Vector__XXX
 SG_ ALOI2_AzmRateTk5 : 9|11@0+ (0.125,-128) [-128|127.875] "deg/s" Vector__XXX
 SG_ ALOI2_AcqTmStm_Inv : 10|1@0+ (1,0) [0|1] "" Vector__XXX
 SG_ ALOI2_AzmRateTk6 : 30|11@0+ (0.125,-128) [-128|127.875] "deg/s" Vector__XXX
 SG_ ALOI2_AzmRateTk7 : 35|11@0+ (0.125,-128) [-128|127.875] "deg/s" Vector__XXX
 SG_ ALOI2_AzmRateTk8 : 40|11@0+ (0.125,-128) [-128|127.875] "deg/s" Vector__XXX
 SG_ ALOI2_AzmTk5 : 61|11@0+ (0.05,-51.2) [-51.2|51.15] "deg" Vector__XXX
 SG_ ALOI2_AzmTk6 : 66|11@0+ (0.05,-51.2) [-51.2|51.15] "deg" Vector__XXX
 SG_ ALOI2_AzmTk7 : 87|11@0+ (0.05,-51.2) [-51.2|51.15] "deg" Vector__XXX
 SG_ ALOI2_AzmTk8 : 92|11@0+ (0.05,-51.2) [-51.2|51.15] "deg" Vector__XXX
 SG_ ALOI2_CnfdTk5 : 97|2@0+ (1,0) [0|3] "" Vector__XXX
 SG_ ALOI2_DirTk5 : 105|3@0+ (1,0) [0|4] "" Vector__XXX
 SG_ ALOI2_CnfdTk8 : 107|2@0+ (1,0) [0|3] "" Vector__XXX
 SG_ ALOI2_CnfdTk7 : 109|2@0+ (1,0) [0|3] "" Vector__XXX
 SG_ ALOI2_CnfdTk6 : 111|2@0+ (1,0) [0|3] "" Vector__XXX
 SG_ ALOI2_DirTk8 : 112|3@0+ (1,0) [0|4] "" Vector__XXX
 SG_ ALOI2_DirTk7 : 115|3@0+ (1,0) [0|4] "" Vector__XXX
 SG_ ALOI2_DirTk6 : 118|3@0+ (1,0) [0|4] "" Vector__XXX
 SG_ ALOI2_IDTk5 : 125|6@0+ (1,0) [0|63] "" Vector__XXX
 SG_ ALOI2_IDTk7 : 129|6@0+ (1,0) [0|63] "" Vector__XXX
 SG_ ALOI2_IDTk6 : 135|6@0+ (1,0) [0|63] "" Vector__XXX
 SG_ ALOI2_IDTk8 : 139|6@0+ (1,0) [0|63] "" Vector__XXX
 SG_ ALOI2_MeasStsTk7 : 145|2@0+ (1,0) [0|3] "" Vector__XXX
 SG_ ALOI2_MeasStsTk6 : 147|2@0+ (1,0) [0|3] "" Vector__XXX
 SG_ ALOI2_MeasStsTk5 : 149|2@0+ (1,0) [0|3] "" Vector__XXX
 SG_ ALOI2_RdSigGlrngTk5 : 157|7@0+ (1,0) [0|127] "%" Vector__XXX
 SG_ ALOI2_MeasStsTk8 : 159|2@0+ (1,0) [0|3] "" Vector__XXX
 SG_ ALOI2_RdSigGlrngTk6 : 166|7@0+ (1,0) [0|127] "%" Vector__XXX
 SG_ ALOI2_RdSigGlrngTk8 : 168|7@0+ (1,0) [0|127] "%" Vector__XXX
 SG_ ALOI2_RdSigGlrngTk7 : 175|7@0+ (1,0) [0|127] "%" Vector__XXX
 SG_ ALOI2_RltvLnTk5 : 177|2@0+ (1,0) [0|3] "" Vector__XXX
 SG_ ALOI2_RngTk5 : 185|16@0+ (0.02,0) [0|1310.7] "m" Vector__XXX
 SG_ ALOI2_RltvLnTk8 : 187|2@0+ (1,0) [0|3] "" Vector__XXX
 SG_ ALOI2_RltvLnTk7 : 189|2@0+ (1,0) [0|3] "" Vector__XXX
 SG_ ALOI2_RltvLnTk6 : 191|2@0+ (1,0) [0|3] "" Vector__XXX
 SG_ ALOI2_RngTk6 : 200|16@0+ (0.02,0) [0|1310.7] "m" Vector__XXX
 SG_ ALOI2_RngTk5_Inv : 201|1@0+ (1,0) [0|1] "" Vector__XXX
 SG_ ALOI2_RngTk6_Inv : 216|1@0+ (1,0) [0|1] "" Vector__XXX
 SG_ ALOI2_RngTk7 : 231|16@0+ (0.02,0) [0|1310.7] "m" Vector__XXX
 SG_ ALOI2_RngTk8 : 246|16@0+ (0.02,0) [0|1310.7] "m" Vector__XXX
 SG_ ALOI2_RngTk7_Inv : 247|1@0+ (1,0) [0|1] "" Vector__XXX
 SG_ ALOI2_TypTk6 : 257|4@0+ (1,0) [0|12] "" Vector__XXX
 SG_ ALOI2_TypTk5 : 261|4@0+ (1,0) [0|12] "" Vector__XXX
 SG_ ALOI2_RngTk8_Inv : 262|1@0+ (1,0) [0|1] "" Vector__XXX
 SG_ ALOI2_TypTk8 : 265|4@0+ (1,0) [0|12] "" Vector__XXX
 SG_ ALOI2_TypTk7 : 269|4@0+ (1,0) [0|12] "" Vector__XXX
 SG_ ALOI2_VertPstnTk5 : 277|6@0+ (0.25,-3) [-3|12.75] "deg" Vector__XXX
 SG_ ALOI2_VertPstnTk7 : 281|6@0+ (0.25,-3) [-3|12.75] "deg" Vector__XXX
 SG_ ALOI2_VertPstnTk6 : 287|6@0+ (0.25,-3) [-3|12.75] "deg" Vector__XXX
 SG_ ALOI2_VertPstnTk8 : 291|6@0+ (0.25,-3) [-3|12.75] "deg" Vector__XXX
 SG_ ALOI2_WdthTk5 : 301|11@0+ (0.1,0) [0|204.7] "deg" Vector__XXX
 SG_ ALOI2_WdthTk6 : 306|11@0+ (0.1,0) [0|204.7] "deg" Vector__XXX
 SG_ ALOI2_WdthTk7 : 327|11@0+ (0.1,0) [0|204.7] "deg" Vector__XXX
 SG_ ALOI2_WdthTk8 : 332|11@0+ (0.1,0) [0|204.7] "deg" Vector__XXX

BO_ 206 AugRltyDatGrp_PDU01: 64 ACP2_MCU
 SG_ ARDG1_FrmTmStm1 : 5|32@0+ (1,0) [0|4.29497e+009] "msec" Vector__XXX
 SG_ ARDG1_ARC : 7|2@0+ (1,0) [0|3] "" Vector__XXX
 SG_ ARDG1_HstLnLtCrv : 37|16@0- (9.77e-07,0) [-0.0320143|0.0320134] "1/m" Vector__XXX
 SG_ ARDG1_HstLnLtCrvDrvt : 53|16@0- (3.73e-09,0) [-0.000122225|0.000122221] "1/m^2" Vector__XXX
 SG_ ARDG1_HstLnLtHdg : 69|10@0- (0.000977,0) [-0.500224|0.499247] "rad" Vector__XXX
 SG_ ARDG1_HstLnLtOfst : 75|13@0- (0.003906,0) [-15.999|15.9951] "m" Vector__XXX
 SG_ ARDG1_HstLnLtVwRngLngDist : 89|7@0+ (1,0) [0|127] "m" Vector__XXX
 SG_ ARDG1_HstLnLtTyp : 92|3@0+ (1,0) [0|7] "" Vector__XXX
 SG_ ARDG1_HstLnLtQlty : 94|2@0+ (1,0) [0|3] "" Vector__XXX
 SG_ ARDG1_HstLnLtVwStrtLngDist : 98|7@0+ (1,0) [0|127] "m" Vector__XXX
 SG_ ARDG1_HstLnLtWdth : 107|6@0+ (0.01,0) [0|0.63] "m" Vector__XXX
 SG_ ARDG1_HstNxtLnLtCrv : 117|16@0- (9.77e-07,0) [-0.0320143|0.0320134] "1/m" Vector__XXX
 SG_ ARDG1_HstNxtLnLtCrvDrvt : 133|16@0- (3.73e-09,0) [-0.000122225|0.000122221] "1/m^2" Vector__XXX
 SG_ ARDG1_HstNxtLnLtHdg : 149|10@0- (0.000977,0) [-0.500224|0.499247] "rad" Vector__XXX
 SG_ ARDG1_HstNxtLnLtOfst : 155|13@0- (0.003906,0) [-15.999|15.9951] "m" Vector__XXX
 SG_ ARDG1_HstNxtLnLtVwRngLngDist : 169|7@0+ (1,0) [0|127] "m" Vector__XXX
 SG_ ARDG1_HstNxtLnLtTyp : 172|3@0+ (1,0) [0|7] "" Vector__XXX
 SG_ ARDG1_HstNxtLnLtQlty : 174|2@0+ (1,0) [0|3] "" Vector__XXX
 SG_ ARDG1_HstNxtLnLtVwStrtLngDist : 178|7@0+ (1,0) [0|127] "m" Vector__XXX
 SG_ ARDG1_HstNxtLnLtWdth : 187|6@0+ (0.01,0) [0|0.63] "m" Vector__XXX
 SG_ ARDG1_LtVehAhdPoILatAccel : 195|9@0- (0.125,0) [-32|31.875] "m/s^2" Vector__XXX
 SG_ ARDG1_LtVehAhdMeasSts : 197|2@0+ (1,0) [0|3] "" Vector__XXX
 SG_ ARDG1_LtVehAhdPoILatPstn : 202|10@0- (0.125,0) [-64|63.875] "m" Vector__XXX
 SG_ ARDG1_LtVehAhdPoILatVel : 208|9@0- (0.125,0) [-32|31.875] "m/s" Vector__XXX
 SG_ ARDG1_LtVehAhdPoILngAccel : 231|9@0- (0.125,0) [-32|31.875] "m/s^2" Vector__XXX
 SG_ ARDG1_LtVehAhdPoILngPstn : 238|11@0+ (0.125,0) [0|255.875] "m" Vector__XXX
 SG_ ARDG1_LtVehAhdPoILngVel : 243|11@0- (0.125,0) [-128|127.875] "m/s" Vector__XXX
 SG_ ARDG1_LtVehAhdPoIWdth : 248|7@0+ (0.125,0) [0|15.875] "m" Vector__XXX
 SG_ ARDG2_ARC : 257|2@0+ (1,0) [0|3] "" Vector__XXX
 SG_ ARDG2_AutfxOutOfCal : 264|2@0+ (1,0) [0|3] "" Vector__XXX
 SG_ ARDG2_AutfxHrzn : 271|7@0- (1,0) [-64|63] "pixel" Vector__XXX
 SG_ ARDG2_AutfxYaw : 278|7@0- (1,0) [-64|63] "pixel" Vector__XXX
 SG_ ARDG2_FrmTmStm2 : 287|32@0+ (1,0) [0|4.29497e+009] "msec" Vector__XXX
 SG_ ARDG2_FrwdCamAlgnLivePtch : 312|12@0- (0.0001,0) [-0.2048|0.2047] "radians" Vector__XXX
 SG_ ARDG2_FrwdCamAlgnHrzn : 319|7@0+ (1,-40) [-40|87] "pixel" Vector__XXX
 SG_ ARDG2_FrwdCamAlgnRoll : 332|7@0- (0.001,0) [-0.064|0.063] "radians" Vector__XXX
 SG_ ARDG2_FrwdCamAlgnYaw : 341|7@0- (1,0) [-64|63] "pixel" Vector__XXX
 SG_ ARDG2_FrwdVsnTmStm : 347|32@0+ (1,0) [0|4.29497e+009] "ms" Vector__XXX
 SG_ ARDG2_FrwdCamSysOprtgSts : 350|3@0+ (1,0) [0|7] "" Vector__XXX
 SG_ ARDG2_HstVehAhdMeasSts : 377|2@0+ (1,0) [0|3] "" Vector__XXX
 SG_ ARDG2_FrwdVsnUnv : 378|1@0+ (1,0) [0|1] "" Vector__XXX
 SG_ ARDG2_FrwdVsnTmStm_Inv : 379|1@0+ (1,0) [0|1] "" Vector__XXX
 SG_ ARDG2_HstVehAhdPoILatAccel : 391|9@0- (0.125,0) [-32|31.875] "m/s^2" Vector__XXX
 SG_ ARDG2_HstVehAhdPoILatPstn : 398|10@0- (0.125,0) [-64|63.875] "m" Vector__XXX
 SG_ ARDG2_HstVehAhdPoILatVel : 404|9@0- (0.125,0) [-32|31.875] "m/s" Vector__XXX
 SG_ ARDG2_HstVehAhdPoILngAccel : 411|9@0- (0.125,0) [-32|31.875] "m/s^2" Vector__XXX
 SG_ ARDG2_HstVehAhdPoILngPstn : 418|11@0+ (0.125,0) [0|255.875] "m" Vector__XXX
 SG_ ARDG2_HstVehAhdPoILngVel : 439|11@0- (0.125,0) [-128|127.875] "m/s" Vector__XXX
 SG_ ARDG2_HstVehAhdPoIWdth : 444|7@0+ (0.125,0) [0|15.875] "m" Vector__XXX
 SG_ ARDG2_FrwdCamAlgnYawRad : 453|11@0- (0.001,0) [-1.024|1.023] "radians" Vector__XXX
 SG_ ARDG2_HstVehAhdPoIHght : 458|7@0+ (0.125,0) [0|15.875] "m" Vector__XXX

BO_ 204 AugRltyDatGrp_PDU02: 48 ACP2_MCU
 SG_ ARDG3_FrmTmStm3 : 5|32@0+ (1,0) [0|4.29497e+009] "msec" Vector__XXX
 SG_ ARDG3_ARC : 7|2@0+ (1,0) [0|3] "" Vector__XXX
 SG_ ARDG3_HstLnRtCrv : 37|16@0- (9.77e-07,0) [-0.0320143|0.0320134] "1/m" Vector__XXX
 SG_ ARDG3_HstLnRtCrvDrvt : 53|16@0- (3.73e-09,0) [-0.000122225|0.000122221] "1/m^2" Vector__XXX
 SG_ ARDG3_HstLnRtHdg : 69|10@0- (0.000977,0) [-0.500224|0.499247] "rad" Vector__XXX
 SG_ ARDG3_HstLnRtOfst : 75|13@0- (0.003906,0) [-15.999|15.9951] "m" Vector__XXX
 SG_ ARDG3_HstLnRtVwRngLngDist : 89|7@0+ (1,0) [0|127] "m" Vector__XXX
 SG_ ARDG3_HstLnRtTyp : 92|3@0+ (1,0) [0|7] "" Vector__XXX
 SG_ ARDG3_HstLnRtQlty : 94|2@0+ (1,0) [0|3] "" Vector__XXX
 SG_ ARDG3_HstLnRtVwStrtLngDist : 98|7@0+ (1,0) [0|127] "m" Vector__XXX
 SG_ ARDG3_HstLnRtWdth : 107|6@0+ (0.01,0) [0|0.63] "m" Vector__XXX
 SG_ ARDG3_HstNxtLnRtCrv : 117|16@0- (9.77e-07,0) [-0.0320143|0.0320134] "1/m" Vector__XXX
 SG_ ARDG3_HstNxtLnRtCrvDrvt : 133|16@0- (3.73e-09,0) [-0.000122225|0.000122221] "1/m^2" Vector__XXX
 SG_ ARDG3_HstNxtLnRtHdg : 149|10@0- (0.000977,0) [-0.500224|0.499247] "rad" Vector__XXX
 SG_ ARDG3_HstNxtLnRtOfst : 155|13@0- (0.003906,0) [-15.999|15.9951] "m" Vector__XXX
 SG_ ARDG3_HstNxtLnRtVwRngLngDist : 169|7@0+ (1,0) [0|127] "m" Vector__XXX
 SG_ ARDG3_HstNxtLnRtTyp : 172|3@0+ (1,0) [0|7] "" Vector__XXX
 SG_ ARDG3_HstNxtLnRtQlty : 174|2@0+ (1,0) [0|3] "" Vector__XXX
 SG_ ARDG3_HstNxtLnRtVwStrtLngDist : 178|7@0+ (1,0) [0|127] "m" Vector__XXX
 SG_ ARDG3_HstNxtLnRtWdth : 187|6@0+ (0.01,0) [0|0.63] "m" Vector__XXX
 SG_ ARDG3_RtVehAhdPoILatAccel : 195|9@0- (0.125,0) [-32|31.875] "m/s^2" Vector__XXX
 SG_ ARDG3_RtVehAhdMeasSts : 197|2@0+ (1,0) [0|3] "" Vector__XXX
 SG_ ARDG3_RtVehAhdPoILatPstn : 202|10@0- (0.125,0) [-64|63.875] "m" Vector__XXX
 SG_ ARDG3_RtVehAhdPoILatVel : 208|9@0- (0.125,0) [-32|31.875] "m/s" Vector__XXX
 SG_ ARDG3_RtVehAhdPoILngAccel : 231|9@0- (0.125,0) [-32|31.875] "m/s^2" Vector__XXX
 SG_ ARDG3_RtVehAhdPoILngPstn : 238|11@0+ (0.125,0) [0|255.875] "m" Vector__XXX
 SG_ ARDG3_RtVehAhdPoILngVel : 243|11@0- (0.125,0) [-128|127.875] "m/s" Vector__XXX
 SG_ ARDG3_RtVehAhdPoIWdth : 248|7@0+ (0.125,0) [0|15.875] "m" Vector__XXX

BO_ 1405 BkupSysPwrMode_PCSM_PDU: 8 CGM
 SG_ BkupSysPwrMode_PCSM : 0|64@1+ (1,0) [0|1.84467e+019] "" ACP2_MCU,EOCM_HCP2,FCM_LC,HDLM,LRR,SRR_LF,SRR_LR_CR,SRR_RF,SRR_RR,SRR_SLR,SRR_SRR,UPM

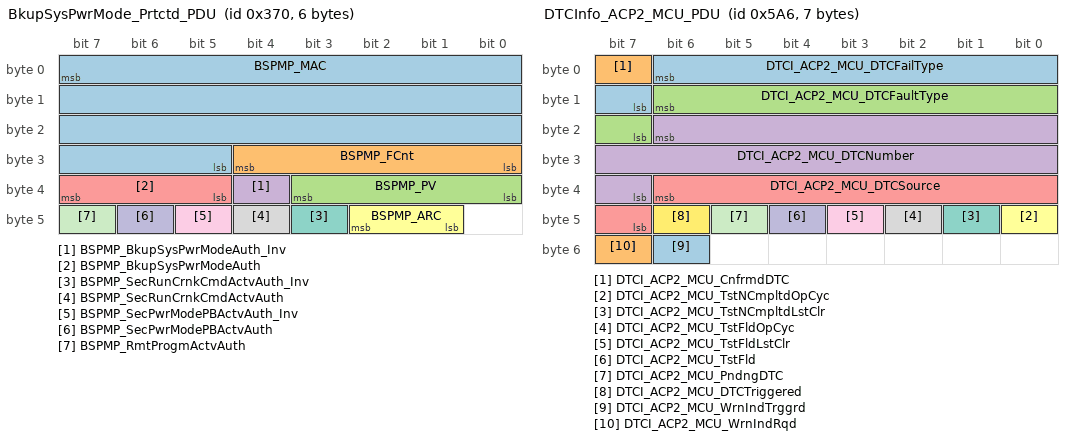
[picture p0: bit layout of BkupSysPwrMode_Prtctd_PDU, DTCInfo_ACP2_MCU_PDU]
BO_ 880 BkupSysPwrMode_Prtctd_PDU: 6 CGM
 SG_ BSPMP_MAC : 7|27@0+ (1,0) [0|1.34218e+008] "" ACP2_MCU,EOCM_HCP2,FCM_LC,HDLM,LRR,SRR_LF,SRR_LR_CR,SRR_RF,SRR_RR,SRR_SLR,SRR_SRR,UPM
 SG_ BSPMP_FCnt : 28|5@0+ (1,0) [0|31] "" ACP2_MCU,EOCM_HCP2,FCM_LC,HDLM,LRR,SRR_LF,SRR_LR_CR,SRR_RF,SRR_RR,SRR_SLR,SRR_SRR,UPM
 SG_ BSPMP_PV : 35|4@0+ (1,0) [0|15] "" ACP2_MCU,EOCM_HCP2,FCM_LC,HDLM,LRR,SRR_LF,SRR_LR_CR,SRR_RF,SRR_RR,SRR_SLR,SRR_SRR,UPM
 SG_ BSPMP_BkupSysPwrModeAuth_Inv : 36|1@0+ (1,0) [0|1] "" ACP2_MCU,EOCM_HCP2,FCM_LC,HDLM,LRR,SRR_LF,SRR_LR_CR,SRR_RF,SRR_RR,SRR_SLR,SRR_SRR,UPM
 SG_ BSPMP_BkupSysPwrModeAuth : 39|3@0+ (1,0) [0|4] "" ACP2_MCU,EOCM_HCP2,FCM_LC,HDLM,LRR,SRR_LF,SRR_LR_CR,SRR_RF,SRR_RR,SRR_SLR,SRR_SRR,UPM
 SG_ BSPMP_ARC : 42|2@0+ (1,0) [0|3] "" ACP2_MCU,EOCM_HCP2,FCM_LC,HDLM,LRR,SRR_LF,SRR_LR_CR,SRR_RF,SRR_RR,SRR_SLR,SRR_SRR,UPM
 SG_ BSPMP_SecRunCrnkCmdActvAuth_Inv : 43|1@0+ (1,0) [0|1] "" ACP2_MCU,EOCM_HCP2,FCM_LC,HDLM,LRR,SRR_LF,SRR_LR_CR,SRR_RF,SRR_RR,SRR_SLR,SRR_SRR,UPM
 SG_ BSPMP_SecRunCrnkCmdActvAuth : 44|1@0+ (1,0) [0|1] "" ACP2_MCU,EOCM_HCP2,FCM_LC,HDLM,LRR,SRR_LF,SRR_LR_CR,SRR_RF,SRR_RR,SRR_SLR,SRR_SRR,UPM
 SG_ BSPMP_SecPwrModePBActvAuth_Inv : 45|1@0+ (1,0) [0|1] "" ACP2_MCU,EOCM_HCP2,FCM_LC,HDLM,LRR,SRR_LF,SRR_LR_CR,SRR_RF,SRR_RR,SRR_SLR,SRR_SRR,UPM
 SG_ BSPMP_SecPwrModePBActvAuth : 46|1@0+ (1,0) [0|1] "" ACP2_MCU,EOCM_HCP2,FCM_LC,HDLM,LRR,SRR_LF,SRR_LR_CR,SRR_RF,SRR_RR,SRR_SLR,SRR_SRR,UPM
 SG_ BSPMP_RmtProgmActvAuth : 47|1@0+ (1,0) [0|1] "" ACP2_MCU,EOCM_HCP2,FCM_LC,HDLM,LRR,SRR_LF,SRR_LR_CR,SRR_RF,SRR_RR,SRR_SLR,SRR_SRR,UPM

BO_ 327 CGM_NM_PDU_On_CAN_8_Cluster: 8 CGM
 SG_ ISignal_CGM_CAN_8_Cluster : 23|48@0+ (1,0) [0|281474976710655] "" ACP2_MCU,EOCM,EOCM_HCP2,EOCM_HC_Superset,FCM_LC,HDLM,LRR,SRR_LF,SRR_LR_CR,SRR_RF,SRR_RR,SRR_SLR,SRR_SRR,UPM

BO_ 1446 DTCInfo_ACP2_MCU_PDU: 7 ACP2_MCU
 SG_ DTCI_ACP2_MCU_DTCFailType : 6|8@0+ (1,0) [0|255] "" CGM
 SG_ DTCI_ACP2_MCU_CnfrmdDTC : 7|1@0+ (1,0) [0|1] "" CGM
 SG_ DTCI_ACP2_MCU_DTCFaultType : 14|8@0+ (1,0) [0|3] "" CGM
 SG_ DTCI_ACP2_MCU_DTCNumber : 22|16@0+ (1,0) [0|65535] "" CGM
 SG_ DTCI_ACP2_MCU_DTCSource : 38|8@0+ (1,0) [0|255] "" CGM
 SG_ DTCI_ACP2_MCU_TstNCmpltdOpCyc : 40|1@0+ (1,0) [0|1] "" CGM
 SG_ DTCI_ACP2_MCU_TstNCmpltdLstClr : 41|1@0+ (1,0) [0|1] "" CGM
 SG_ DTCI_ACP2_MCU_TstFldOpCyc : 42|1@0+ (1,0) [0|1] "" CGM
 SG_ DTCI_ACP2_MCU_TstFldLstClr : 43|1@0+ (1,0) [0|1] "" CGM
 SG_ DTCI_ACP2_MCU_TstFld : 44|1@0+ (1,0) [0|1] "" CGM
 SG_ DTCI_ACP2_MCU_PndngDTC : 45|1@0+ (1,0) [0|1] "" CGM
 SG_ DTCI_ACP2_MCU_DTCTriggered : 46|1@0+ (1,0) [0|1] "" CGM
 SG_ DTCI_ACP2_MCU_WrnIndTrggrd : 54|1@0+ (1,0) [0|1] "" CGM
 SG_ DTCI_ACP2_MCU_WrnIndRqd : 55|1@0+ (1,0) [0|1] "" CGM

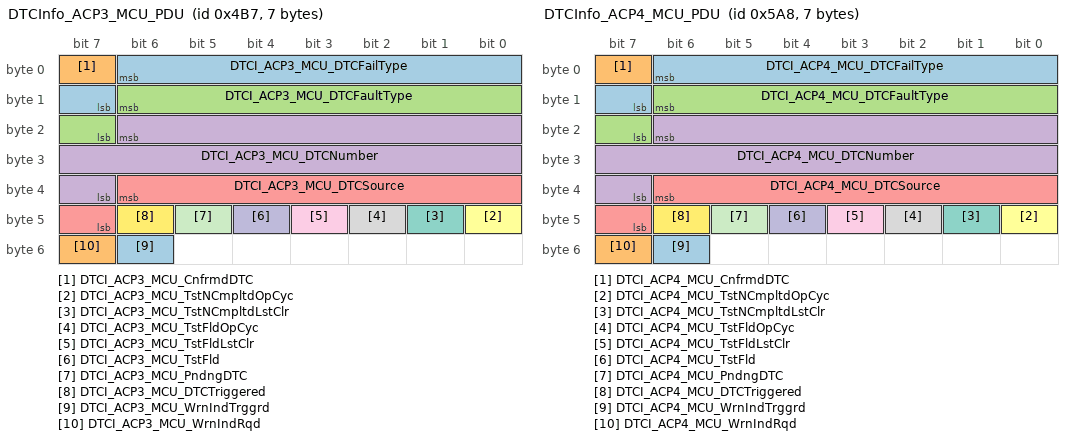
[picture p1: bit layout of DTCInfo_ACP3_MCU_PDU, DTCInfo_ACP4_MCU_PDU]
BO_ 1207 DTCInfo_ACP3_MCU_PDU: 7 EOCM_HC_Superset
 SG_ DTCI_ACP3_MCU_DTCFailType : 6|8@0+ (1,0) [0|255] "" CGM
 SG_ DTCI_ACP3_MCU_CnfrmdDTC : 7|1@0+ (1,0) [0|1] "" CGM
 SG_ DTCI_ACP3_MCU_DTCFaultType : 14|8@0+ (1,0) [0|3] "" CGM
 SG_ DTCI_ACP3_MCU_DTCNumber : 22|16@0+ (1,0) [0|65535] "" CGM
 SG_ DTCI_ACP3_MCU_DTCSource : 38|8@0+ (1,0) [0|255] "" CGM
 SG_ DTCI_ACP3_MCU_TstNCmpltdOpCyc : 40|1@0+ (1,0) [0|1] "" CGM
 SG_ DTCI_ACP3_MCU_TstNCmpltdLstClr : 41|1@0+ (1,0) [0|1] "" CGM
 SG_ DTCI_ACP3_MCU_TstFldOpCyc : 42|1@0+ (1,0) [0|1] "" CGM
 SG_ DTCI_ACP3_MCU_TstFldLstClr : 43|1@0+ (1,0) [0|1] "" CGM
 SG_ DTCI_ACP3_MCU_TstFld : 44|1@0+ (1,0) [0|1] "" CGM
 SG_ DTCI_ACP3_MCU_PndngDTC : 45|1@0+ (1,0) [0|1] "" CGM
 SG_ DTCI_ACP3_MCU_DTCTriggered : 46|1@0+ (1,0) [0|1] "" CGM
 SG_ DTCI_ACP3_MCU_WrnIndTrggrd : 54|1@0+ (1,0) [0|1] "" CGM
 SG_ DTCI_ACP3_MCU_WrnIndRqd : 55|1@0+ (1,0) [0|1] "" CGM

BO_ 1448 DTCInfo_ACP4_MCU_PDU: 7 EOCM_HC_Superset
 SG_ DTCI_ACP4_MCU_DTCFailType : 6|8@0+ (1,0) [0|255] "" CGM
 SG_ DTCI_ACP4_MCU_CnfrmdDTC : 7|1@0+ (1,0) [0|1] "" CGM
 SG_ DTCI_ACP4_MCU_DTCFaultType : 14|8@0+ (1,0) [0|3] "" CGM
 SG_ DTCI_ACP4_MCU_DTCNumber : 22|16@0+ (1,0) [0|65535] "" CGM
 SG_ DTCI_ACP4_MCU_DTCSource : 38|8@0+ (1,0) [0|255] "" CGM
 SG_ DTCI_ACP4_MCU_TstNCmpltdOpCyc : 40|1@0+ (1,0) [0|1] "" CGM
 SG_ DTCI_ACP4_MCU_TstNCmpltdLstClr : 41|1@0+ (1,0) [0|1] "" CGM
 SG_ DTCI_ACP4_MCU_TstFldOpCyc : 42|1@0+ (1,0) [0|1] "" CGM
 SG_ DTCI_ACP4_MCU_TstFldLstClr : 43|1@0+ (1,0) [0|1] "" CGM
 SG_ DTCI_ACP4_MCU_TstFld : 44|1@0+ (1,0) [0|1] "" CGM
 SG_ DTCI_ACP4_MCU_PndngDTC : 45|1@0+ (1,0) [0|1] "" CGM
 SG_ DTCI_ACP4_MCU_DTCTriggered : 46|1@0+ (1,0) [0|1] "" CGM
 SG_ DTCI_ACP4_MCU_WrnIndTrggrd : 54|1@0+ (1,0) [0|1] "" CGM
 SG_ DTCI_ACP4_MCU_WrnIndRqd : 55|1@0+ (1,0) [0|1] "" CGM

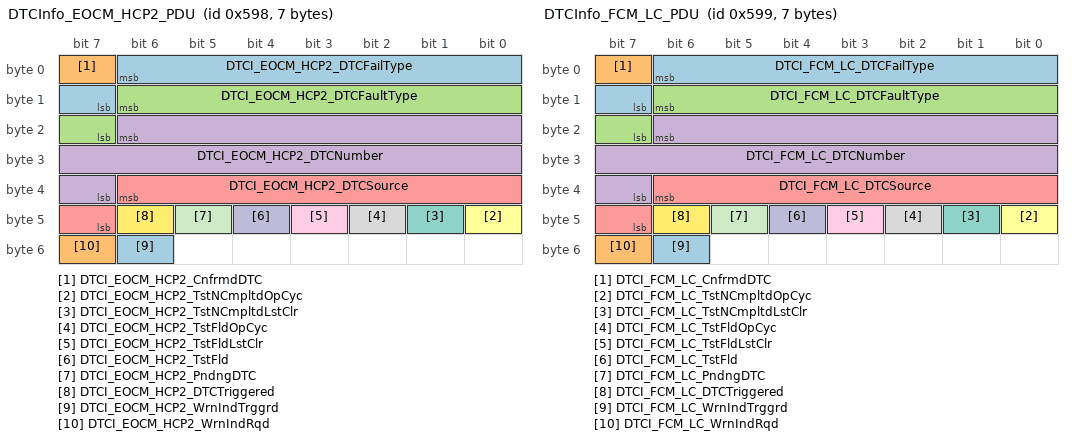
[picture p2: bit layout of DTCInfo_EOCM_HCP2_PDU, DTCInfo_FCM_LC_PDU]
BO_ 1432 DTCInfo_EOCM_HCP2_PDU: 7 EOCM_HCP2
 SG_ DTCI_EOCM_HCP2_DTCFailType : 6|8@0+ (1,0) [0|255] "" CGM
 SG_ DTCI_EOCM_HCP2_CnfrmdDTC : 7|1@0+ (1,0) [0|1] "" CGM
 SG_ DTCI_EOCM_HCP2_DTCFaultType : 14|8@0+ (1,0) [0|3] "" CGM
 SG_ DTCI_EOCM_HCP2_DTCNumber : 22|16@0+ (1,0) [0|65535] "" CGM
 SG_ DTCI_EOCM_HCP2_DTCSource : 38|8@0+ (1,0) [0|255] "" CGM
 SG_ DTCI_EOCM_HCP2_TstNCmpltdOpCyc : 40|1@0+ (1,0) [0|1] "" CGM
 SG_ DTCI_EOCM_HCP2_TstNCmpltdLstClr : 41|1@0+ (1,0) [0|1] "" CGM
 SG_ DTCI_EOCM_HCP2_TstFldOpCyc : 42|1@0+ (1,0) [0|1] "" CGM
 SG_ DTCI_EOCM_HCP2_TstFldLstClr : 43|1@0+ (1,0) [0|1] "" CGM
 SG_ DTCI_EOCM_HCP2_TstFld : 44|1@0+ (1,0) [0|1] "" CGM
 SG_ DTCI_EOCM_HCP2_PndngDTC : 45|1@0+ (1,0) [0|1] "" CGM
 SG_ DTCI_EOCM_HCP2_DTCTriggered : 46|1@0+ (1,0) [0|1] "" CGM
 SG_ DTCI_EOCM_HCP2_WrnIndTrggrd : 54|1@0+ (1,0) [0|1] "" CGM
 SG_ DTCI_EOCM_HCP2_WrnIndRqd : 55|1@0+ (1,0) [0|1] "" CGM

BO_ 1433 DTCInfo_FCM_LC_PDU: 7 FCM_LC
 SG_ DTCI_FCM_LC_DTCFailType : 6|8@0+ (1,0) [0|255] "" CGM
 SG_ DTCI_FCM_LC_CnfrmdDTC : 7|1@0+ (1,0) [0|1] "" CGM
 SG_ DTCI_FCM_LC_DTCFaultType : 14|8@0+ (1,0) [0|3] "" CGM
 SG_ DTCI_FCM_LC_DTCNumber : 22|16@0+ (1,0) [0|65535] "" CGM
 SG_ DTCI_FCM_LC_DTCSource : 38|8@0+ (1,0) [0|255] "" CGM
 SG_ DTCI_FCM_LC_TstNCmpltdOpCyc : 40|1@0+ (1,0) [0|1] "" CGM
 SG_ DTCI_FCM_LC_TstNCmpltdLstClr : 41|1@0+ (1,0) [0|1] "" CGM
 SG_ DTCI_FCM_LC_TstFldOpCyc : 42|1@0+ (1,0) [0|1] "" CGM
 SG_ DTCI_FCM_LC_TstFldLstClr : 43|1@0+ (1,0) [0|1] "" CGM
 SG_ DTCI_FCM_LC_TstFld : 44|1@0+ (1,0) [0|1] "" CGM
 SG_ DTCI_FCM_LC_PndngDTC : 45|1@0+ (1,0) [0|1] "" CGM
 SG_ DTCI_FCM_LC_DTCTriggered : 46|1@0+ (1,0) [0|1] "" CGM
 SG_ DTCI_FCM_LC_WrnIndTrggrd : 54|1@0+ (1,0) [0|1] "" CGM
 SG_ DTCI_FCM_LC_WrnIndRqd : 55|1@0+ (1,0) [0|1] "" CGM

BA_DEF_ SG_  "SignalType" STRING ;
BA_DEF_ SG_  "SignalLongName" STRING ;
BA_DEF_ BO_  "GenMsgCycleTime" INT 0 10000;
BA_DEF_ BO_  "GenMsgSendType" ENUM "cyclicX","spontanX","cyclicIfActiveX","spontanWithDelay","cyclicAndSpontanX","cyclicAndSpontanWithDelay","spontanWithRepetition","cyclicIfActiveAndSpontanWD";
BA_DEF_ BO_  "VFrameFormat" ENUM  "StandardCAN","ExtendedCAN","reserved","reserved","reserved","reserved","reserved","reserved","reserved","reserved","reserved","reserved","reserved","reserved","StandardCAN_FD","ExtendedCAN_FD";
BA_DEF_DEF_  "SignalType" "";
BA_DEF_DEF_  "SignalLongName" "";
BA_DEF_DEF_  "GenMsgCycleTime" 0;
BA_DEF_DEF_  "GenMsgSendType" "cyclicX";
BA_DEF_DEF_  "VFrameFormat" "StandardCAN";
BA_ "GenMsgCycleTime" BO_ 2147745829 1000;
BA_ "GenMsgCycleTime" BO_ 2147745830 1000;
BA_ "GenMsgCycleTime" BO_ 2147745831 1000;
BA_ "GenMsgCycleTime" BO_ 512 40;
BA_ "VFrameFormat" BO_ 512 14;
BA_ "GenMsgCycleTime" BO_ 514 40;
BA_ "VFrameFormat" BO_ 514 14;
BA_ "VFrameFormat" BO_ 206 14;
BA_ "VFrameFormat" BO_ 204 14;
BA_ "GenMsgCycleTime" BO_ 1405 1000;
BA_ "VFrameFormat" BO_ 1405 14;
BA_ "GenMsgCycleTime" BO_ 880 250;
BA_ "VFrameFormat" BO_ 880 14;
BA_ "GenMsgCycleTime" BO_ 1446 1000;
BA_ "VFrameFormat" BO_ 1446 14;
BA_ "GenMsgCycleTime" BO_ 1207 1000;
BA_ "VFrameFormat" BO_ 1207 14;
BA_ "GenMsgCycleTime" BO_ 1448 1000;
BA_ "VFrameFormat" BO_ 1448 14;
BA_ "GenMsgCycleTime" BO_ 1432 1000;
BA_ "VFrameFormat" BO_ 1432 14;
BA_ "GenMsgCycleTime" BO_ 1433 1000;
BA_ "VFrameFormat" BO_ 1433 14;
BA_ "SignalType" SG_ 2147745829 ACP2_MCU_CAN_8_ClscCANHrtBtActv "ENM";
BA_ "SignalLongName" SG_ 2147745829 ACP2_MCU_CAN_8_ClscCANHrtBtActv "ACP2_MCU CAN 8 Classic CAN Heart Beat Active";
BA_ "SignalType" SG_ 2147745830 ACP3_MCU_CAN8_ClscCANHrtBtActv "ENM";
BA_ "SignalLongName" SG_ 2147745830 ACP3_MCU_CAN8_ClscCANHrtBtActv "ACP3_MCU CAN 8 Classic CAN Heart Beat Active";
BA_ "SignalType" SG_ 2147745831 ACP4_MCU_CAN8_ClscCANHrtBtActv "ENM";
BA_ "SignalLongName" SG_ 2147745831 ACP4_MCU_CAN8_ClscCANHrtBtActv "ACP4_MCU CAN 8 Classic CAN Heart Beat Active";
BA_ "SignalLongName" SG_ 512 ALOI1_AcqTmStm "Adaptive Lighting Objects Information 1 : Acquisition Time Stamp";
BA_ "SignalLongName" SG_ 512 ALOI1_ARC "Adaptive Lighting Objects Information 1 : Alive Rolling Count";
BA_ "SignalLongName" SG_ 512 ALOI1_AzmRateTk1 "Adaptive Lighting Objects Information 1 : Azimuth Rate Track1";
BA_ "SignalType" SG_ 512 ALOI1_AcqTmStm_Inv "ENM";
BA_ "SignalLongName" SG_ 512 ALOI1_AcqTmStm_Inv "Adaptive Lighting Objects Information 1 : Acquisition Time Stamp Invalid";
BA_ "SignalLongName" SG_ 512 ALOI1_AzmRateTk2 "Adaptive Lighting Objects Information 1 : Azimuth Rate Track 2";
BA_ "SignalLongName" SG_ 512 ALOI1_AzmRateTk3 "Adaptive Lighting Objects Information 1 : Azimuth Rate Track 3";
BA_ "SignalLongName" SG_ 512 ALOI1_AzmRateTk4 "Adaptive Lighting Objects Information 1 : Azimuth Rate Track 4";
BA_ "SignalLongName" SG_ 512 ALOI1_AzmTk1 "Adaptive Lighting Objects Information 1 : Azimuth Track 1";
BA_ "SignalLongName" SG_ 512 ALOI1_AzmTk2 "Adaptive Lighting Objects Information 1 : Azimuth Track 2";
BA_ "SignalLongName" SG_ 512 ALOI1_AzmTk3 "Adaptive Lighting Objects Information 1 : Azimuth Track 3";
BA_ "SignalLongName" SG_ 512 ALOI1_AzmTk4 "Adaptive Lighting Objects Information 1 : Azimuth Track 4";
BA_ "SignalType" SG_ 512 ALOI1_CnfdTk1 "ENM";
BA_ "SignalLongName" SG_ 512 ALOI1_CnfdTk1 "Adaptive Lighting Objects Information 1 : Confidence Track 1";
BA_ "SignalType" SG_ 512 ALOI1_DirTk1 "ENM";
BA_ "SignalLongName" SG_ 512 ALOI1_DirTk1 "Adaptive Lighting Objects Information 1 : Direction Track 1";
BA_ "SignalType" SG_ 512 ALOI1_CnfdTk4 "ENM";
BA_ "SignalLongName" SG_ 512 ALOI1_CnfdTk4 "Adaptive Lighting Objects Information 1 : Confidence Track 4";
BA_ "SignalType" SG_ 512 ALOI1_CnfdTk3 "ENM";
BA_ "SignalLongName" SG_ 512 ALOI1_CnfdTk3 "Adaptive Lighting Objects Information 1 : Confidence Track 3";
BA_ "SignalType" SG_ 512 ALOI1_CnfdTk2 "ENM";
BA_ "SignalLongName" SG_ 512 ALOI1_CnfdTk2 "Adaptive Lighting Objects Information 1 : Confidence Track 2";
BA_ "SignalType" SG_ 512 ALOI1_DirTk4 "ENM";
BA_ "SignalLongName" SG_ 512 ALOI1_DirTk4 "Adaptive Lighting Objects Information 1 : Direction Track 4";
BA_ "SignalType" SG_ 512 ALOI1_DirTk3 "ENM";
BA_ "SignalLongName" SG_ 512 ALOI1_DirTk3 "Adaptive Lighting Objects Information 1 : Direction Track 3";
BA_ "SignalType" SG_ 512 ALOI1_DirTk2 "ENM";
BA_ "SignalLongName" SG_ 512 ALOI1_DirTk2 "Adaptive Lighting Objects Information 1 : Direction Track 2";
BA_ "SignalLongName" SG_ 512 ALOI1_IDTk1 "Adaptive Lighting Objects Information 1 : ID Track 1";
BA_ "SignalLongName" SG_ 512 ALOI1_IDTk3 "Adaptive Lighting Objects Information 1 : ID Track 3";
BA_ "SignalLongName" SG_ 512 ALOI1_IDTk2 "Adaptive Lighting Objects Information 1 : ID Track 2";
BA_ "SignalLongName" SG_ 512 ALOI1_IDTk4 "Adaptive Lighting Objects Information 1 : ID Track 4";
BA_ "SignalType" SG_ 512 ALOI1_MeasStsTk3 "ENM";
BA_ "SignalLongName" SG_ 512 ALOI1_MeasStsTk3 "Adaptive Lighting Objects Information 1 : Measurement Status Track 3";
BA_ "SignalType" SG_ 512 ALOI1_MeasStsTk2 "ENM";
BA_ "SignalLongName" SG_ 512 ALOI1_MeasStsTk2 "Adaptive Lighting Objects Information 1 : Measurement Status Track 2";
BA_ "SignalType" SG_ 512 ALOI1_MeasStsTk1 "ENM";
BA_ "SignalLongName" SG_ 512 ALOI1_MeasStsTk1 "Adaptive Lighting Objects Information 1 : Measurement Status Track 1";
BA_ "SignalLongName" SG_ 512 ALOI1_RdSigGlrngTk1 "Adaptive Lighting Objects Information 1 : Road Signal Glaring Track 1";
BA_ "SignalType" SG_ 512 ALOI1_MeasStsTk4 "ENM";
BA_ "SignalLongName" SG_ 512 ALOI1_MeasStsTk4 "Adaptive Lighting Objects Information 1 : Measurement Status Track 4";
BA_ "SignalLongName" SG_ 512 ALOI1_RdSigGlrngTk2 "Adaptive Lighting Objects Information 1 : Road Signal Glaring Track 2";
BA_ "SignalLongName" SG_ 512 ALOI1_RdSigGlrngTk4 "Adaptive Lighting Objects Information 1 : Road Signal Glaring Track 4";
BA_ "SignalLongName" SG_ 512 ALOI1_RdSigGlrngTk3 "Adaptive Lighting Objects Information 1 : Road Signal Glaring Track 3";
BA_ "SignalType" SG_ 512 ALOI1_RltvLnTk1 "ENM";
BA_ "SignalLongName" SG_ 512 ALOI1_RltvLnTk1 "Adaptive Lighting Objects Information 1 : Relative Lane Track 1";
BA_ "SignalLongName" SG_ 512 ALOI1_RngTk1 "Adaptive Lighting Objects Information 1 : Range Track 1";
BA_ "SignalType" SG_ 512 ALOI1_RltvLnTk4 "ENM";
BA_ "SignalLongName" SG_ 512 ALOI1_RltvLnTk4 "Adaptive Lighting Objects Information 1 : Relative Lane Track 4";
BA_ "SignalType" SG_ 512 ALOI1_RltvLnTk3 "ENM";
BA_ "SignalLongName" SG_ 512 ALOI1_RltvLnTk3 "Adaptive Lighting Objects Information 1 : Relative Lane Track 3";
BA_ "SignalType" SG_ 512 ALOI1_RltvLnTk2 "ENM";
BA_ "SignalLongName" SG_ 512 ALOI1_RltvLnTk2 "Adaptive Lighting Objects Information 1 : Relative Lane Track 2";
BA_ "SignalLongName" SG_ 512 ALOI1_RngTk2 "Adaptive Lighting Objects Information 1 : Range Track 2";
BA_ "SignalType" SG_ 512 ALOI1_RngTk1_Inv "ENM";
BA_ "SignalLongName" SG_ 512 ALOI1_RngTk1_Inv "Adaptive Lighting Objects Information 1 : Range Track 1 Invalid";
BA_ "SignalType" SG_ 512 ALOI1_RngTk2_Inv "ENM";
BA_ "SignalLongName" SG_ 512 ALOI1_RngTk2_Inv "Adaptive Lighting Objects Information 1 : Range Track 2 Invalid";
BA_ "SignalLongName" SG_ 512 ALOI1_RngTk3 "Adaptive Lighting Objects Information 1 : Range Track 3";
BA_ "SignalLongName" SG_ 512 ALOI1_RngTk4 "Adaptive Lighting Objects Information 1 : Range Track 4";
BA_ "SignalType" SG_ 512 ALOI1_RngTk3_Inv "ENM";
BA_ "SignalLongName" SG_ 512 ALOI1_RngTk3_Inv "Adaptive Lighting Objects Information 1 : Range Track 3 Invalid";
BA_ "SignalType" SG_ 512 ALOI1_TypTk2 "ENM";
BA_ "SignalLongName" SG_ 512 ALOI1_TypTk2 "Adaptive Lighting Objects Information 1 : Type Track 2";
BA_ "SignalType" SG_ 512 ALOI1_TypTk1 "ENM";
BA_ "SignalLongName" SG_ 512 ALOI1_TypTk1 "Adaptive Lighting Objects Information 1 : Type Track 1";
BA_ "SignalType" SG_ 512 ALOI1_RngTk4_Inv "ENM";
BA_ "SignalLongName" SG_ 512 ALOI1_RngTk4_Inv "Adaptive Lighting Objects Information 1 : Range Track 4 Invalid";
BA_ "SignalType" SG_ 512 ALOI1_TypTk4 "ENM";
BA_ "SignalLongName" SG_ 512 ALOI1_TypTk4 "Adaptive Lighting Objects Information 1 : Type Track 4";
BA_ "SignalType" SG_ 512 ALOI1_TypTk3 "ENM";
BA_ "SignalLongName" SG_ 512 ALOI1_TypTk3 "Adaptive Lighting Objects Information 1 : Type Track 3";
BA_ "SignalLongName" SG_ 512 ALOI1_VertPstnTk1 "Adaptive Lighting Objects Information 1 : Vertical Position Track 1";
BA_ "SignalLongName" SG_ 512 ALOI1_VertPstnTk3 "Adaptive Lighting Objects Information 1 : Vertical Position Track 3";
BA_ "SignalLongName" SG_ 512 ALOI1_VertPstnTk2 "Adaptive Lighting Objects Information 1 : Vertical Position Track 2";
BA_ "SignalLongName" SG_ 512 ALOI1_VertPstnTk4 "Adaptive Lighting Objects Information 1 : Vertical Position Track 4";
BA_ "SignalLongName" SG_ 512 ALOI1_WdthTk1 "Adaptive Lighting Objects Information 1 : Width Track 1";
BA_ "SignalLongName" SG_ 512 ALOI1_WdthTk2 "Adaptive Lighting Objects Information 1 : Width Track 2";
BA_ "SignalLongName" SG_ 512 ALOI1_WdthTk3 "Adaptive Lighting Objects Information 1 : Width Track 3";
BA_ "SignalLongName" SG_ 512 ALOI1_WdthTk4 "Adaptive Lighting Objects Information 1 : Width Track 4";
BA_ "SignalLongName" SG_ 514 ALOI2_AcqTmStm "Adaptive Lighting Objects Information 2 : Acquisition Time Stamp";
BA_ "SignalLongName" SG_ 514 ALOI2_ARC "Adaptive Lighting Objects Information 2 : Alive Rolling Count";
BA_ "SignalLongName" SG_ 514 ALOI2_AzmRateTk5 "Adaptive Lighting Objects Information 2 : Azimuth Rate Track 5";
BA_ "SignalType" SG_ 514 ALOI2_AcqTmStm_Inv "ENM";
BA_ "SignalLongName" SG_ 514 ALOI2_AcqTmStm_Inv "Adaptive Lighting Objects Information 2 : Acquisition Time Stamp Invalid";
BA_ "SignalLongName" SG_ 514 ALOI2_AzmRateTk6 "Adaptive Lighting Objects Information 2 : Azimuth Rate Track 6";
BA_ "SignalLongName" SG_ 514 ALOI2_AzmRateTk7 "Adaptive Lighting Objects Information 2 : Azimuth Rate Track 7";
BA_ "SignalLongName" SG_ 514 ALOI2_AzmRateTk8 "Adaptive Lighting Objects Information 2 : Azimuth Rate Track 8";
BA_ "SignalLongName" SG_ 514 ALOI2_AzmTk5 "Adaptive Lighting Objects Information 2 : Azimuth Track 5";
BA_ "SignalLongName" SG_ 514 ALOI2_AzmTk6 "Adaptive Lighting Objects Information 2 : Azimuth Track 6";
BA_ "SignalLongName" SG_ 514 ALOI2_AzmTk7 "Adaptive Lighting Objects Information 2 : Azimuth Track 7";
BA_ "SignalLongName" SG_ 514 ALOI2_AzmTk8 "Adaptive Lighting Objects Information 2 : Azimuth Track 8";
BA_ "SignalType" SG_ 514 ALOI2_CnfdTk5 "ENM";
BA_ "SignalLongName" SG_ 514 ALOI2_CnfdTk5 "Adaptive Lighting Objects Information 2 : Confidence Track 5";
BA_ "SignalType" SG_ 514 ALOI2_DirTk5 "ENM";
BA_ "SignalLongName" SG_ 514 ALOI2_DirTk5 "Adaptive Lighting Objects Information 2 : Direction Track 5";
BA_ "SignalType" SG_ 514 ALOI2_CnfdTk8 "ENM";
BA_ "SignalLongName" SG_ 514 ALOI2_CnfdTk8 "Adaptive Lighting Objects Information 2 : Confidence Track 8";
BA_ "SignalType" SG_ 514 ALOI2_CnfdTk7 "ENM";
BA_ "SignalLongName" SG_ 514 ALOI2_CnfdTk7 "Adaptive Lighting Objects Information 2 : Confidence Track 7";
BA_ "SignalType" SG_ 514 ALOI2_CnfdTk6 "ENM";
BA_ "SignalLongName" SG_ 514 ALOI2_CnfdTk6 "Adaptive Lighting Objects Information 2 : Confidence Track 6";
BA_ "SignalType" SG_ 514 ALOI2_DirTk8 "ENM";
BA_ "SignalLongName" SG_ 514 ALOI2_DirTk8 "Adaptive Lighting Objects Information 2 : Direction Track 8";
BA_ "SignalType" SG_ 514 ALOI2_DirTk7 "ENM";
BA_ "SignalLongName" SG_ 514 ALOI2_DirTk7 "Adaptive Lighting Objects Information 2 : Direction Track 7";
BA_ "SignalType" SG_ 514 ALOI2_DirTk6 "ENM";
BA_ "SignalLongName" SG_ 514 ALOI2_DirTk6 "Adaptive Lighting Objects Information 2 : Direction Track 6";
BA_ "SignalLongName" SG_ 514 ALOI2_IDTk5 "Adaptive Lighting Objects Information 2 : ID Track 5";
BA_ "SignalLongName" SG_ 514 ALOI2_IDTk7 "Adaptive Lighting Objects Information 2 : ID Track 7";
BA_ "SignalLongName" SG_ 514 ALOI2_IDTk6 "Adaptive Lighting Objects Information 2 : ID Track 6";
BA_ "SignalLongName" SG_ 514 ALOI2_IDTk8 "Adaptive Lighting Objects Information 2 : ID Track 8";
BA_ "SignalType" SG_ 514 ALOI2_MeasStsTk7 "ENM";
BA_ "SignalLongName" SG_ 514 ALOI2_MeasStsTk7 "Adaptive Lighting Objects Information 2 : Measurement Status Track 7";
BA_ "SignalType" SG_ 514 ALOI2_MeasStsTk6 "ENM";
BA_ "SignalLongName" SG_ 514 ALOI2_MeasStsTk6 "Adaptive Lighting Objects Information 2 : Measurement Status Track 6";
BA_ "SignalType" SG_ 514 ALOI2_MeasStsTk5 "ENM";
BA_ "SignalLongName" SG_ 514 ALOI2_MeasStsTk5 "Adaptive Lighting Objects Information 2 : Measurement Status Track 5";
BA_ "SignalLongName" SG_ 514 ALOI2_RdSigGlrngTk5 "Adaptive Lighting Objects Information 2 : Road Signal Glaring Track 5";
BA_ "SignalType" SG_ 514 ALOI2_MeasStsTk8 "ENM";
BA_ "SignalLongName" SG_ 514 ALOI2_MeasStsTk8 "Adaptive Lighting Objects Information 2 : Measurement Status Track 8";
BA_ "SignalLongName" SG_ 514 ALOI2_RdSigGlrngTk6 "Adaptive Lighting Objects Information 2 : Road Signal Glaring Track 6";
BA_ "SignalLongName" SG_ 514 ALOI2_RdSigGlrngTk8 "Adaptive Lighting Objects Information 2 : Road Signal Glaring Track 8";
BA_ "SignalLongName" SG_ 514 ALOI2_RdSigGlrngTk7 "Adaptive Lighting Objects Information 2 : Road Signal Glaring Track 7";
BA_ "SignalType" SG_ 514 ALOI2_RltvLnTk5 "ENM";
BA_ "SignalLongName" SG_ 514 ALOI2_RltvLnTk5 "Adaptive Lighting Objects Information 2 : Relative Lane Track 5";
BA_ "SignalLongName" SG_ 514 ALOI2_RngTk5 "Adaptive Lighting Objects Information 2 : Range Track 5";
BA_ "SignalType" SG_ 514 ALOI2_RltvLnTk8 "ENM";
BA_ "SignalLongName" SG_ 514 ALOI2_RltvLnTk8 "Adaptive Lighting Objects Information 2 : Relative Lane Track 8";
BA_ "SignalType" SG_ 514 ALOI2_RltvLnTk7 "ENM";
BA_ "SignalLongName" SG_ 514 ALOI2_RltvLnTk7 "Adaptive Lighting Objects Information 2 : Relative Lane Track 7";
BA_ "SignalType" SG_ 514 ALOI2_RltvLnTk6 "ENM";
BA_ "SignalLongName" SG_ 514 ALOI2_RltvLnTk6 "Adaptive Lighting Objects Information 2 : Relative Lane Track 6";
BA_ "SignalLongName" SG_ 514 ALOI2_RngTk6 "Adaptive Lighting Objects Information 2 : Range Track 6";
BA_ "SignalType" SG_ 514 ALOI2_RngTk5_Inv "ENM";
BA_ "SignalLongName" SG_ 514 ALOI2_RngTk5_Inv "Adaptive Lighting Objects Information 2 : Range Track 5 Invalid";
BA_ "SignalType" SG_ 514 ALOI2_RngTk6_Inv "ENM";
BA_ "SignalLongName" SG_ 514 ALOI2_RngTk6_Inv "Adaptive Lighting Objects Information 2 : Range Track 6 Invalid";
BA_ "SignalLongName" SG_ 514 ALOI2_RngTk7 "Adaptive Lighting Objects Information 2 : Range Track 7";
BA_ "SignalLongName" SG_ 514 ALOI2_RngTk8 "Adaptive Lighting Objects Information 2 : Range Track 8";
BA_ "SignalType" SG_ 514 ALOI2_RngTk7_Inv "ENM";
BA_ "SignalLongName" SG_ 514 ALOI2_RngTk7_Inv "Adaptive Lighting Objects Information 2 : Range Track 7 Invalid";
BA_ "SignalType" SG_ 514 ALOI2_TypTk6 "ENM";
BA_ "SignalLongName" SG_ 514 ALOI2_TypTk6 "Adaptive Lighting Objects Information 2 : Type Track 6";
BA_ "SignalType" SG_ 514 ALOI2_TypTk5 "ENM";
BA_ "SignalLongName" SG_ 514 ALOI2_TypTk5 "Adaptive Lighting Objects Information 2 : Type Track 5";
BA_ "SignalType" SG_ 514 ALOI2_RngTk8_Inv "ENM";
BA_ "SignalLongName" SG_ 514 ALOI2_RngTk8_Inv "Adaptive Lighting Objects Information 2 : Range Track 8 Invalid";
BA_ "SignalType" SG_ 514 ALOI2_TypTk8 "ENM";
BA_ "SignalLongName" SG_ 514 ALOI2_TypTk8 "Adaptive Lighting Objects Information 2 : Type Track 8";
BA_ "SignalType" SG_ 514 ALOI2_TypTk7 "ENM";
BA_ "SignalLongName" SG_ 514 ALOI2_TypTk7 "Adaptive Lighting Objects Information 2 : Type Track 7";
BA_ "SignalLongName" SG_ 514 ALOI2_VertPstnTk5 "Adaptive Lighting Objects Information 2 : Vertical Position Track 5";
BA_ "SignalLongName" SG_ 514 ALOI2_VertPstnTk7 "Adaptive Lighting Objects Information 2 : Vertical Position Track 7";
BA_ "SignalLongName" SG_ 514 ALOI2_VertPstnTk6 "Adaptive Lighting Objects Information 2 : Vertical Position Track 6";
BA_ "SignalLongName" SG_ 514 ALOI2_VertPstnTk8 "Adaptive Lighting Objects Information 2 : Vertical Position Track 8";
BA_ "SignalLongName" SG_ 514 ALOI2_WdthTk5 "Adaptive Lighting Objects Information 2 : Width Track 5";
BA_ "SignalLongName" SG_ 514 ALOI2_WdthTk6 "Adaptive Lighting Objects Information 2 : Width Track 6";
BA_ "SignalLongName" SG_ 514 ALOI2_WdthTk7 "Adaptive Lighting Objects Information 2 : Width Track 7";
BA_ "SignalLongName" SG_ 514 ALOI2_WdthTk8 "Adaptive Lighting Objects Information 2 : Width Track 8";
BA_ "SignalLongName" SG_ 206 ARDG1_FrmTmStm1 "Augmented Reality Data Group 1 : Frame Time Stamp 1";
BA_ "SignalLongName" SG_ 206 ARDG1_ARC "Augmented Reality Data Group 1 : Alive Rolling Count";
BA_ "SignalLongName" SG_ 206 ARDG1_HstLnLtCrv "Augmented Reality Data Group 1 : Host Lane Left Curvature";
BA_ "SignalLongName" SG_ 206 ARDG1_HstLnLtCrvDrvt "Augmented Reality Data Group 1 : Host Lane Left Curvature Derivative";
BA_ "SignalLongName" SG_ 206 ARDG1_HstLnLtHdg "Augmented Reality Data Group 1 : Host Lane Left Heading";
BA_ "SignalLongName" SG_ 206 ARDG1_HstLnLtOfst "Augmented Reality Data Group 1 : Host Lane Left Offset";
BA_ "SignalLongName" SG_ 206 ARDG1_HstLnLtVwRngLngDist "Augmented Reality Data Group 1 : Host Lane Left View Range Longitudinal Distance";
BA_ "SignalType" SG_ 206 ARDG1_HstLnLtTyp "ENM";
BA_ "SignalLongName" SG_ 206 ARDG1_HstLnLtTyp "Augmented Reality Data Group 1 : Host Lane Left Type";
BA_ "SignalType" SG_ 206 ARDG1_HstLnLtQlty "ENM";
BA_ "SignalLongName" SG_ 206 ARDG1_HstLnLtQlty "Augmented Reality Data Group 1 : Host Lane Left Quality";
BA_ "SignalLongName" SG_ 206 ARDG1_HstLnLtVwStrtLngDist "Augmented Reality Data Group 1 : Host Lane Left View Start Longitudinal Distance";
BA_ "SignalLongName" SG_ 206 ARDG1_HstLnLtWdth "Augmented Reality Data Group 1 : Host Lane Left Width";
BA_ "SignalLongName" SG_ 206 ARDG1_HstNxtLnLtCrv "Augmented Reality Data Group 1 : Host Next Lane Left Curvature";
BA_ "SignalLongName" SG_ 206 ARDG1_HstNxtLnLtCrvDrvt "Augmented Reality Data Group 1 : Host Next Lane Left Curvature Derivative";
BA_ "SignalLongName" SG_ 206 ARDG1_HstNxtLnLtHdg "Augmented Reality Data Group 1 : Host Next Lane Left Heading";
BA_ "SignalLongName" SG_ 206 ARDG1_HstNxtLnLtOfst "Augmented Reality Data Group 1 : Host Next Lane Left Offset";
BA_ "SignalLongName" SG_ 206 ARDG1_HstNxtLnLtVwRngLngDist "Augmented Reality Data Group 1 : Host Next Lane Left View Range Longitudinal Distance";
BA_ "SignalType" SG_ 206 ARDG1_HstNxtLnLtTyp "ENM";
BA_ "SignalLongName" SG_ 206 ARDG1_HstNxtLnLtTyp "Augmented Reality Data Group 1 : Host Next Lane Left Type";
BA_ "SignalType" SG_ 206 ARDG1_HstNxtLnLtQlty "ENM";
BA_ "SignalLongName" SG_ 206 ARDG1_HstNxtLnLtQlty "Augmented Reality Data Group 1 : Host Next Lane Left Quality";
BA_ "SignalLongName" SG_ 206 ARDG1_HstNxtLnLtVwStrtLngDist "Augmented Reality Data Group 1 : Host Next Lane Left View Start Longitudinal Distance";
BA_ "SignalLongName" SG_ 206 ARDG1_HstNxtLnLtWdth "Augmented Reality Data Group 1 : Host Next Lane Left Width";
BA_ "SignalLongName" SG_ 206 ARDG1_LtVehAhdPoILatAccel "Augmented Reality Data Group 1 : Left Vehicle Ahead Point of Interest Lateral Acceleration";
BA_ "SignalType" SG_ 206 ARDG1_LtVehAhdMeasSts "ENM";
BA_ "SignalLongName" SG_ 206 ARDG1_LtVehAhdMeasSts "Augmented Reality Data Group 1 : Left Vehicle Ahead Measurement Status";
BA_ "SignalLongName" SG_ 206 ARDG1_LtVehAhdPoILatPstn "Augmented Reality Data Group 1 : Left Vehicle Ahead Point of Interest Lateral Position";
BA_ "SignalLongName" SG_ 206 ARDG1_LtVehAhdPoILatVel "Augmented Reality Data Group 1 : Left Vehicle Ahead Point of Interest Lateral Velocity";
BA_ "SignalLongName" SG_ 206 ARDG1_LtVehAhdPoILngAccel "Augmented Reality Data Group 1 : Left Vehicle Ahead Point of Interest Longitudinal Acceleration";
BA_ "SignalLongName" SG_ 206 ARDG1_LtVehAhdPoILngPstn "Augmented Reality Data Group 1 : Left Vehicle Ahead Point of Interest Longitudinal Position";
BA_ "SignalLongName" SG_ 206 ARDG1_LtVehAhdPoILngVel "Augmented Reality Data Group 1 : Left Vehicle Ahead Point of Interest Longitudinal Velocity";
BA_ "SignalLongName" SG_ 206 ARDG1_LtVehAhdPoIWdth "Augmented Reality Data Group 1 : Left Vehicle Ahead Point of Interest Width";
BA_ "SignalLongName" SG_ 206 ARDG2_ARC "Augmented Reality Data Group 2 : Alive Rolling Count";
BA_ "SignalType" SG_ 206 ARDG2_AutfxOutOfCal "ENM";
BA_ "SignalLongName" SG_ 206 ARDG2_AutfxOutOfCal "Augmented Reality Data Group 2 : Autofix Out of Calibration";
BA_ "SignalLongName" SG_ 206 ARDG2_AutfxHrzn "Augmented Reality Data Group 2 : Autofix Horizon";
BA_ "SignalLongName" SG_ 206 ARDG2_AutfxYaw "Augmented Reality Data Group 2 : Autofix Yaw";
BA_ "SignalLongName" SG_ 206 ARDG2_FrmTmStm2 "Augmented Reality Data Group 2 : Frame Time Stamp 2";
BA_ "SignalLongName" SG_ 206 ARDG2_FrwdCamAlgnLivePtch "Augmented Reality Data Group 2 : Forward Camera Alignment Live Pitch";
BA_ "SignalLongName" SG_ 206 ARDG2_FrwdCamAlgnHrzn "Augmented Reality Data Group 2 : Forward Camera Alignment Horizon";
BA_ "SignalLongName" SG_ 206 ARDG2_FrwdCamAlgnRoll "Augmented Reality Data Group 2 : Forward Camera Alignment Roll";
BA_ "SignalLongName" SG_ 206 ARDG2_FrwdCamAlgnYaw "Augmented Reality Data Group 2 : Forward Camera Alignment Yaw";
BA_ "SignalLongName" SG_ 206 ARDG2_FrwdVsnTmStm "Augmented Reality Data Group 2 : Forward Vision Time Stamp";
BA_ "SignalType" SG_ 206 ARDG2_FrwdCamSysOprtgSts "ENM";
BA_ "SignalLongName" SG_ 206 ARDG2_FrwdCamSysOprtgSts "Augmented Reality Data Group 2 : Forward Camera System Operating Status";
BA_ "SignalType" SG_ 206 ARDG2_HstVehAhdMeasSts "ENM";
BA_ "SignalLongName" SG_ 206 ARDG2_HstVehAhdMeasSts "Augmented Reality Data Group 2 : Host Vehicle Ahead Measurement Status";
BA_ "SignalType" SG_ 206 ARDG2_FrwdVsnUnv "ENM";
BA_ "SignalLongName" SG_ 206 ARDG2_FrwdVsnUnv "Augmented Reality Data Group 2 : Forward Vision Unavailable";
BA_ "SignalType" SG_ 206 ARDG2_FrwdVsnTmStm_Inv "ENM";
BA_ "SignalLongName" SG_ 206 ARDG2_FrwdVsnTmStm_Inv "Augmented Reality Data Group 2 : Forward Vision Time Stamp Invalid";
BA_ "SignalLongName" SG_ 206 ARDG2_HstVehAhdPoILatAccel "Augmented Reality Data Group 2 : Host Vehicle Ahead Point of Interest Lateral Acceleration";
BA_ "SignalLongName" SG_ 206 ARDG2_HstVehAhdPoILatPstn "Augmented Reality Data Group 2 : Host Vehicle Ahead Point of Interest Lateral Position";
BA_ "SignalLongName" SG_ 206 ARDG2_HstVehAhdPoILatVel "Augmented Reality Data Group 2 : Host Vehicle Ahead Point of Interest Lateral Velocity";
BA_ "SignalLongName" SG_ 206 ARDG2_HstVehAhdPoILngAccel "Augmented Reality Data Group 2 : Host Vehicle Ahead Point of Interest Longitudinal Acceleration";
BA_ "SignalLongName" SG_ 206 ARDG2_HstVehAhdPoILngPstn "Augmented Reality Data Group 2 : Host Vehicle Ahead Point of Interest Longitudinal Position";
BA_ "SignalLongName" SG_ 206 ARDG2_HstVehAhdPoILngVel "Augmented Reality Data Group 2 : Host Vehicle Ahead Point of Interest Longitudinal Velocity";
BA_ "SignalLongName" SG_ 206 ARDG2_HstVehAhdPoIWdth "Augmented Reality Data Group 2 : Host Vehicle Ahead Point of Interest Width";
BA_ "SignalLongName" SG_ 206 ARDG2_FrwdCamAlgnYawRad "Augmented Reality Data Group 2 : Forward Camera Alignment Yaw Radian";
BA_ "SignalLongName" SG_ 206 ARDG2_HstVehAhdPoIHght "Augmented Reality Data Group 2 : Host Vehicle Ahead Point of Interest Height";
BA_ "SignalLongName" SG_ 204 ARDG3_FrmTmStm3 "Augmented Reality Data Group 3 : Frame Time Stamp 3";
BA_ "SignalLongName" SG_ 204 ARDG3_ARC "Augmented Reality Data Group 3 : Alive Rolling Count";
BA_ "SignalLongName" SG_ 204 ARDG3_HstLnRtCrv "Augmented Reality Data Group 3 : Host Lane Right Curvature";
BA_ "SignalLongName" SG_ 204 ARDG3_HstLnRtCrvDrvt "Augmented Reality Data Group 3 : Host Lane Right Curvature Derivative";
BA_ "SignalLongName" SG_ 204 ARDG3_HstLnRtHdg "Augmented Reality Data Group 3 : Host Lane Right Heading";
BA_ "SignalLongName" SG_ 204 ARDG3_HstLnRtOfst "Augmented Reality Data Group 3 : Host Lane Right Offset";
BA_ "SignalLongName" SG_ 204 ARDG3_HstLnRtVwRngLngDist "Augmented Reality Data Group 3 : Host Lane Right View Range Longitudinal Distance";
BA_ "SignalType" SG_ 204 ARDG3_HstLnRtTyp "ENM";
BA_ "SignalLongName" SG_ 204 ARDG3_HstLnRtTyp "Augmented Reality Data Group 3 : Host Lane Right Type";
BA_ "SignalType" SG_ 204 ARDG3_HstLnRtQlty "ENM";
BA_ "SignalLongName" SG_ 204 ARDG3_HstLnRtQlty "Augmented Reality Data Group 3 : Host Lane Right Quality";
BA_ "SignalLongName" SG_ 204 ARDG3_HstLnRtVwStrtLngDist "Augmented Reality Data Group 3 : Host Lane Right View Start Longitudinal Distance";
BA_ "SignalLongName" SG_ 204 ARDG3_HstLnRtWdth "Augmented Reality Data Group 3 : Host Lane Right Width";
BA_ "SignalLongName" SG_ 204 ARDG3_HstNxtLnRtCrv "Augmented Reality Data Group 3 : Host Next Lane Right Curvature";
BA_ "SignalLongName" SG_ 204 ARDG3_HstNxtLnRtCrvDrvt "Augmented Reality Data Group 3 : Host Next Lane Right Curvature Derivative";
BA_ "SignalLongName" SG_ 204 ARDG3_HstNxtLnRtHdg "Augmented Reality Data Group 3 : Host Next Lane Right Heading";
BA_ "SignalLongName" SG_ 204 ARDG3_HstNxtLnRtOfst "Augmented Reality Data Group 3 : Host Next Lane Right Offset";
BA_ "SignalLongName" SG_ 204 ARDG3_HstNxtLnRtVwRngLngDist "Augmented Reality Data Group 3 : Host Next Lane Right View Range Longitudinal Distance";
BA_ "SignalType" SG_ 204 ARDG3_HstNxtLnRtTyp "ENM";
BA_ "SignalLongName" SG_ 204 ARDG3_HstNxtLnRtTyp "Augmented Reality Data Group 3 : Host Next Lane Right Type";
BA_ "SignalType" SG_ 204 ARDG3_HstNxtLnRtQlty "ENM";
BA_ "SignalLongName" SG_ 204 ARDG3_HstNxtLnRtQlty "Augmented Reality Data Group 3 : Host Next Lane Right Quality";
BA_ "SignalLongName" SG_ 204 ARDG3_HstNxtLnRtVwStrtLngDist "Augmented Reality Data Group 3 : Host Next Lane Right View Start Longitudinal Distance";
BA_ "SignalLongName" SG_ 204 ARDG3_HstNxtLnRtWdth "Augmented Reality Data Group 3 : Host Next Lane Right Width";
BA_ "SignalLongName" SG_ 204 ARDG3_RtVehAhdPoILatAccel "Augmented Reality Data Group 3 : Right Vehicle Ahead Point of Interest Lateral Acceleration";
BA_ "SignalType" SG_ 204 ARDG3_RtVehAhdMeasSts "ENM";
BA_ "SignalLongName" SG_ 204 ARDG3_RtVehAhdMeasSts "Augmented Reality Data Group 3 : Right Vehicle Ahead Measurement Status";
BA_ "SignalLongName" SG_ 204 ARDG3_RtVehAhdPoILatPstn "Augmented Reality Data Group 3 : Right Vehicle Ahead Point of Interest Lateral Position";
BA_ "SignalLongName" SG_ 204 ARDG3_RtVehAhdPoILatVel "Augmented Reality Data Group 3 : Right Vehicle Ahead Point of Interest Lateral Velocity";
BA_ "SignalLongName" SG_ 204 ARDG3_RtVehAhdPoILngAccel "Augmented Reality Data Group 3 : Right Vehicle Ahead Point of Interest Longitudinal Acceleration";
BA_ "SignalLongName" SG_ 204 ARDG3_RtVehAhdPoILngPstn "Augmented Reality Data Group 3 : Right Vehicle Ahead Point of Interest Longitudinal Position";
BA_ "SignalLongName" SG_ 204 ARDG3_RtVehAhdPoILngVel "Augmented Reality Data Group 3 : Right Vehicle Ahead Point of Interest Longitudinal Velocity";
BA_ "SignalLongName" SG_ 204 ARDG3_RtVehAhdPoIWdth "Augmented Reality Data Group 3 : Right Vehicle Ahead Point of Interest Width";
BA_ "SignalLongName" SG_ 1405 BkupSysPwrMode_PCSM "Backup System Power Mode Protected Counter Sync Message";
BA_ "SignalLongName" SG_ 880 BSPMP_MAC "Backup System Power Mode Protected : MAC";
BA_ "SignalLongName" SG_ 880 BSPMP_FCnt "Backup System Power Mode Protected : Freshness Counter";
BA_ "SignalLongName" SG_ 880 BSPMP_PV "Backup System Power Mode Protected : Protection Value";
BA_ "SignalType" SG_ 880 BSPMP_BkupSysPwrModeAuth_Inv "ENM";
BA_ "SignalLongName" SG_ 880 BSPMP_BkupSysPwrModeAuth_Inv "Backup System Power Mode Protected : Backup System Power Mode Authenticated Invalid";
BA_ "SignalType" SG_ 880 BSPMP_BkupSysPwrModeAuth "ENM";
BA_ "SignalLongName" SG_ 880 BSPMP_BkupSysPwrModeAuth "Backup System Power Mode Protected : Backup System Power Mode Authenticated";
BA_ "SignalLongName" SG_ 880 BSPMP_ARC "Backup System Power Mode Protected : Alive Rolling Count";
BA_ "SignalType" SG_ 880 BSPMP_SecRunCrnkCmdActvAuth_Inv "ENM";
BA_ "SignalLongName" SG_ 880 BSPMP_SecRunCrnkCmdActvAuth_Inv "Backup System Power Mode Protected : Secondary Run Crank Command Active Invalid Authenticated";
BA_ "SignalType" SG_ 880 BSPMP_SecRunCrnkCmdActvAuth "ENM";
BA_ "SignalLongName" SG_ 880 BSPMP_SecRunCrnkCmdActvAuth "Backup System Power Mode Protected : Secondary Run Crank Command Active Authenticated";
BA_ "SignalType" SG_ 880 BSPMP_SecPwrModePBActvAuth_Inv "ENM";
BA_ "SignalLongName" SG_ 880 BSPMP_SecPwrModePBActvAuth_Inv "Backup System Power Mode Protected : Secondary Power Mode Pushbutton Active Authenticated Invalid";
BA_ "SignalType" SG_ 880 BSPMP_SecPwrModePBActvAuth "ENM";
BA_ "SignalLongName" SG_ 880 BSPMP_SecPwrModePBActvAuth "Backup System Power Mode Protected : Secondary Power Mode Pushbutton Active Authenticated";
BA_ "SignalType" SG_ 880 BSPMP_RmtProgmActvAuth "ENM";
BA_ "SignalLongName" SG_ 880 BSPMP_RmtProgmActvAuth "Backup System Power Mode Protected : Remote Programming Active Authenticated";
BA_ "SignalLongName" SG_ 1446 DTCI_ACP2_MCU_DTCFailType "Diagnostic Trouble Code Information Extended - ACP2_MCU : Diagnostic Trouble Code Failure Type";
BA_ "SignalType" SG_ 1446 DTCI_ACP2_MCU_CnfrmdDTC "ENM";
BA_ "SignalLongName" SG_ 1446 DTCI_ACP2_MCU_CnfrmdDTC "Diagnostic Trouble Code Information Extended - ACP2_MCU : Confirmed DTC";
BA_ "SignalType" SG_ 1446 DTCI_ACP2_MCU_DTCFaultType "ENM";
BA_ "SignalLongName" SG_ 1446 DTCI_ACP2_MCU_DTCFaultType "Diagnostic Trouble Code Information Extended - ACP2_MCU : Diagnostic Trouble Code Fault Type";
BA_ "SignalLongName" SG_ 1446 DTCI_ACP2_MCU_DTCNumber "Diagnostic Trouble Code Information Extended - ACP2_MCU : Diagnostic Trouble Code Number";
BA_ "SignalLongName" SG_ 1446 DTCI_ACP2_MCU_DTCSource "Diagnostic Trouble Code Information Extended - ACP2_MCU : Diagnostic Trouble Code Source";
BA_ "SignalType" SG_ 1446 DTCI_ACP2_MCU_TstNCmpltdOpCyc "ENM";
BA_ "SignalLongName" SG_ 1446 DTCI_ACP2_MCU_TstNCmpltdOpCyc "Diagnostic Trouble Code Information Extended - ACP2_MCU : Test Not Completed This Operation Cycle";
BA_ "SignalType" SG_ 1446 DTCI_ACP2_MCU_TstNCmpltdLstClr "ENM";
BA_ "SignalLongName" SG_ 1446 DTCI_ACP2_MCU_TstNCmpltdLstClr "Diagnostic Trouble Code Information Extended - ACP2_MCU : Test Not Completed Since Last Clear";
BA_ "SignalType" SG_ 1446 DTCI_ACP2_MCU_TstFldOpCyc "ENM";
BA_ "SignalLongName" SG_ 1446 DTCI_ACP2_MCU_TstFldOpCyc "Diagnostic Trouble Code Information Extended - ACP2_MCU : Test Failed This Operation Cycle";
BA_ "SignalType" SG_ 1446 DTCI_ACP2_MCU_TstFldLstClr "ENM";
BA_ "SignalLongName" SG_ 1446 DTCI_ACP2_MCU_TstFldLstClr "Diagnostic Trouble Code Information Extended - ACP2_MCU : Test Failed Since Last Clear";
BA_ "SignalType" SG_ 1446 DTCI_ACP2_MCU_TstFld "ENM";
BA_ "SignalLongName" SG_ 1446 DTCI_ACP2_MCU_TstFld "Diagnostic Trouble Code Information Extended - ACP2_MCU : Test Failed";
BA_ "SignalType" SG_ 1446 DTCI_ACP2_MCU_PndngDTC "ENM";
BA_ "SignalLongName" SG_ 1446 DTCI_ACP2_MCU_PndngDTC "Diagnostic Trouble Code Information Extended - ACP2_MCU : Pending DTC";
BA_ "SignalType" SG_ 1446 DTCI_ACP2_MCU_DTCTriggered "ENM";
BA_ "SignalLongName" SG_ 1446 DTCI_ACP2_MCU_DTCTriggered "Diagnostic Trouble Code Information Extended - ACP2_MCU : Diagnostic Trouble Code Triggered";
BA_ "SignalType" SG_ 1446 DTCI_ACP2_MCU_WrnIndTrggrd "ENM";
BA_ "SignalLongName" SG_ 1446 DTCI_ACP2_MCU_WrnIndTrggrd "Diagnostic Trouble Code Information Extended - ACP2_MCU : Warning Indicator Triggered";
BA_ "SignalType" SG_ 1446 DTCI_ACP2_MCU_WrnIndRqd "ENM";
BA_ "SignalLongName" SG_ 1446 DTCI_ACP2_MCU_WrnIndRqd "Diagnostic Trouble Code Information Extended - ACP2_MCU : Warning Indicator Requested";
BA_ "SignalLongName" SG_ 1207 DTCI_ACP3_MCU_DTCFailType "Diagnostic Trouble Code Information Extended - ACP3_MCU : Diagnostic Trouble Code Failure Type";
BA_ "SignalType" SG_ 1207 DTCI_ACP3_MCU_CnfrmdDTC "ENM";
BA_ "SignalLongName" SG_ 1207 DTCI_ACP3_MCU_CnfrmdDTC "Diagnostic Trouble Code Information Extended - ACP3_MCU : Confirmed DTC";
BA_ "SignalType" SG_ 1207 DTCI_ACP3_MCU_DTCFaultType "ENM";
BA_ "SignalLongName" SG_ 1207 DTCI_ACP3_MCU_DTCFaultType "Diagnostic Trouble Code Information Extended - ACP3_MCU : Diagnostic Trouble Code Fault Type";
BA_ "SignalLongName" SG_ 1207 DTCI_ACP3_MCU_DTCNumber "Diagnostic Trouble Code Information Extended - ACP3_MCU : Diagnostic Trouble Code Number";
BA_ "SignalLongName" SG_ 1207 DTCI_ACP3_MCU_DTCSource "Diagnostic Trouble Code Information Extended - ACP3_MCU : Diagnostic Trouble Code Source";
BA_ "SignalType" SG_ 1207 DTCI_ACP3_MCU_TstNCmpltdOpCyc "ENM";
BA_ "SignalLongName" SG_ 1207 DTCI_ACP3_MCU_TstNCmpltdOpCyc "Diagnostic Trouble Code Information Extended - ACP3_MCU : Test Not Completed This Operation Cycle";
BA_ "SignalType" SG_ 1207 DTCI_ACP3_MCU_TstNCmpltdLstClr "ENM";
BA_ "SignalLongName" SG_ 1207 DTCI_ACP3_MCU_TstNCmpltdLstClr "Diagnostic Trouble Code Information Extended - ACP3_MCU : Test Not Completed Since Last Clear";
BA_ "SignalType" SG_ 1207 DTCI_ACP3_MCU_TstFldOpCyc "ENM";
BA_ "SignalLongName" SG_ 1207 DTCI_ACP3_MCU_TstFldOpCyc "Diagnostic Trouble Code Information Extended - ACP3_MCU : Test Failed This Operation Cycle";
BA_ "SignalType" SG_ 1207 DTCI_ACP3_MCU_TstFldLstClr "ENM";
BA_ "SignalLongName" SG_ 1207 DTCI_ACP3_MCU_TstFldLstClr "Diagnostic Trouble Code Information Extended - ACP3_MCU : Test Failed Since Last Clear";
BA_ "SignalType" SG_ 1207 DTCI_ACP3_MCU_TstFld "ENM";
BA_ "SignalLongName" SG_ 1207 DTCI_ACP3_MCU_TstFld "Diagnostic Trouble Code Information Extended - ACP3_MCU : Test Failed";
BA_ "SignalType" SG_ 1207 DTCI_ACP3_MCU_PndngDTC "ENM";
BA_ "SignalLongName" SG_ 1207 DTCI_ACP3_MCU_PndngDTC "Diagnostic Trouble Code Information Extended - ACP3_MCU : Pending DTC";
BA_ "SignalType" SG_ 1207 DTCI_ACP3_MCU_DTCTriggered "ENM";
BA_ "SignalLongName" SG_ 1207 DTCI_ACP3_MCU_DTCTriggered "Diagnostic Trouble Code Information Extended - ACP3_MCU : Diagnostic Trouble Code Triggered";
BA_ "SignalType" SG_ 1207 DTCI_ACP3_MCU_WrnIndTrggrd "ENM";
BA_ "SignalLongName" SG_ 1207 DTCI_ACP3_MCU_WrnIndTrggrd "Diagnostic Trouble Code Information Extended - ACP3_MCU : Warning Indicator Triggered";
BA_ "SignalType" SG_ 1207 DTCI_ACP3_MCU_WrnIndRqd "ENM";
BA_ "SignalLongName" SG_ 1207 DTCI_ACP3_MCU_WrnIndRqd "Diagnostic Trouble Code Information Extended - ACP3_MCU : Warning Indicator Requested";
BA_ "SignalLongName" SG_ 1448 DTCI_ACP4_MCU_DTCFailType "Diagnostic Trouble Code Information Extended - ACP4_MCU : Diagnostic Trouble Code Failure Type";
BA_ "SignalType" SG_ 1448 DTCI_ACP4_MCU_CnfrmdDTC "ENM";
BA_ "SignalLongName" SG_ 1448 DTCI_ACP4_MCU_CnfrmdDTC "Diagnostic Trouble Code Information Extended - ACP4_MCU : Confirmed DTC";
BA_ "SignalType" SG_ 1448 DTCI_ACP4_MCU_DTCFaultType "ENM";
BA_ "SignalLongName" SG_ 1448 DTCI_ACP4_MCU_DTCFaultType "Diagnostic Trouble Code Information Extended - ACP4_MCU : Diagnostic Trouble Code Fault Type";
BA_ "SignalLongName" SG_ 1448 DTCI_ACP4_MCU_DTCNumber "Diagnostic Trouble Code Information Extended - ACP4_MCU : Diagnostic Trouble Code Number";
BA_ "SignalLongName" SG_ 1448 DTCI_ACP4_MCU_DTCSource "Diagnostic Trouble Code Information Extended - ACP4_MCU : Diagnostic Trouble Code Source";
BA_ "SignalType" SG_ 1448 DTCI_ACP4_MCU_TstNCmpltdOpCyc "ENM";
BA_ "SignalLongName" SG_ 1448 DTCI_ACP4_MCU_TstNCmpltdOpCyc "Diagnostic Trouble Code Information Extended - ACP4_MCU : Test Not Completed This Operation Cycle";
BA_ "SignalType" SG_ 1448 DTCI_ACP4_MCU_TstNCmpltdLstClr "ENM";
BA_ "SignalLongName" SG_ 1448 DTCI_ACP4_MCU_TstNCmpltdLstClr "Diagnostic Trouble Code Information Extended - ACP4_MCU : Test Not Completed Since Last Clear";
BA_ "SignalType" SG_ 1448 DTCI_ACP4_MCU_TstFldOpCyc "ENM";
BA_ "SignalLongName" SG_ 1448 DTCI_ACP4_MCU_TstFldOpCyc "Diagnostic Trouble Code Information Extended - ACP4_MCU : Test Failed This Operation Cycle";
BA_ "SignalType" SG_ 1448 DTCI_ACP4_MCU_TstFldLstClr "ENM";
BA_ "SignalLongName" SG_ 1448 DTCI_ACP4_MCU_TstFldLstClr "Diagnostic Trouble Code Information Extended - ACP4_MCU : Test Failed Since Last Clear";
BA_ "SignalType" SG_ 1448 DTCI_ACP4_MCU_TstFld "ENM";
BA_ "SignalLongName" SG_ 1448 DTCI_ACP4_MCU_TstFld "Diagnostic Trouble Code Information Extended - ACP4_MCU : Test Failed";
BA_ "SignalType" SG_ 1448 DTCI_ACP4_MCU_PndngDTC "ENM";
BA_ "SignalLongName" SG_ 1448 DTCI_ACP4_MCU_PndngDTC "Diagnostic Trouble Code Information Extended - ACP4_MCU : Pending DTC";
BA_ "SignalType" SG_ 1448 DTCI_ACP4_MCU_DTCTriggered "ENM";
BA_ "SignalLongName" SG_ 1448 DTCI_ACP4_MCU_DTCTriggered "Diagnostic Trouble Code Information Extended - ACP4_MCU : Diagnostic Trouble Code Triggered";
BA_ "SignalType" SG_ 1448 DTCI_ACP4_MCU_WrnIndTrggrd "ENM";
BA_ "SignalLongName" SG_ 1448 DTCI_ACP4_MCU_WrnIndTrggrd "Diagnostic Trouble Code Information Extended - ACP4_MCU : Warning Indicator Triggered";
BA_ "SignalType" SG_ 1448 DTCI_ACP4_MCU_WrnIndRqd "ENM";
BA_ "SignalLongName" SG_ 1448 DTCI_ACP4_MCU_WrnIndRqd "Diagnostic Trouble Code Information Extended - ACP4_MCU : Warning Indicator Requested";
BA_ "SignalLongName" SG_ 1432 DTCI_EOCM_HCP2_DTCFailType "Diagnostic Trouble Code Information Extended - EOCM_HCP2 : Diagnostic Trouble Code Failure Type";
BA_ "SignalType" SG_ 1432 DTCI_EOCM_HCP2_CnfrmdDTC "ENM";
BA_ "SignalLongName" SG_ 1432 DTCI_EOCM_HCP2_CnfrmdDTC "Diagnostic Trouble Code Information Extended - EOCM_HCP2 : Confirmed DTC";
BA_ "SignalType" SG_ 1432 DTCI_EOCM_HCP2_DTCFaultType "ENM";
BA_ "SignalLongName" SG_ 1432 DTCI_EOCM_HCP2_DTCFaultType "Diagnostic Trouble Code Information Extended - EOCM_HCP2 : Diagnostic Trouble Code Fault Type";
BA_ "SignalLongName" SG_ 1432 DTCI_EOCM_HCP2_DTCNumber "Diagnostic Trouble Code Information Extended - EOCM_HCP2 : Diagnostic Trouble Code Number";
BA_ "SignalLongName" SG_ 1432 DTCI_EOCM_HCP2_DTCSource "Diagnostic Trouble Code Information Extended - EOCM_HCP2 : Diagnostic Trouble Code Source";
BA_ "SignalType" SG_ 1432 DTCI_EOCM_HCP2_TstNCmpltdOpCyc "ENM";
BA_ "SignalLongName" SG_ 1432 DTCI_EOCM_HCP2_TstNCmpltdOpCyc "Diagnostic Trouble Code Information Extended - EOCM_HCP2 : Test Not Completed This Operation Cycle";
BA_ "SignalType" SG_ 1432 DTCI_EOCM_HCP2_TstNCmpltdLstClr "ENM";
BA_ "SignalLongName" SG_ 1432 DTCI_EOCM_HCP2_TstNCmpltdLstClr "Diagnostic Trouble Code Information Extended - EOCM_HCP2 : Test Not Completed Since Last Clear";
BA_ "SignalType" SG_ 1432 DTCI_EOCM_HCP2_TstFldOpCyc "ENM";
BA_ "SignalLongName" SG_ 1432 DTCI_EOCM_HCP2_TstFldOpCyc "Diagnostic Trouble Code Information Extended - EOCM_HCP2 : Test Failed This Operation Cycle";
BA_ "SignalType" SG_ 1432 DTCI_EOCM_HCP2_TstFldLstClr "ENM";
BA_ "SignalLongName" SG_ 1432 DTCI_EOCM_HCP2_TstFldLstClr "Diagnostic Trouble Code Information Extended - EOCM_HCP2 : Test Failed Since Last Clear";
BA_ "SignalType" SG_ 1432 DTCI_EOCM_HCP2_TstFld "ENM";
BA_ "SignalLongName" SG_ 1432 DTCI_EOCM_HCP2_TstFld "Diagnostic Trouble Code Information Extended - EOCM_HCP2 : Test Failed";
BA_ "SignalType" SG_ 1432 DTCI_EOCM_HCP2_PndngDTC "ENM";
BA_ "SignalLongName" SG_ 1432 DTCI_EOCM_HCP2_PndngDTC "Diagnostic Trouble Code Information Extended - EOCM_HCP2 : Pending DTC";
BA_ "SignalType" SG_ 1432 DTCI_EOCM_HCP2_DTCTriggered "ENM";
BA_ "SignalLongName" SG_ 1432 DTCI_EOCM_HCP2_DTCTriggered "Diagnostic Trouble Code Information Extended - EOCM_HCP2 : Diagnostic Trouble Code Triggered";
BA_ "SignalType" SG_ 1432 DTCI_EOCM_HCP2_WrnIndTrggrd "ENM";
BA_ "SignalLongName" SG_ 1432 DTCI_EOCM_HCP2_WrnIndTrggrd "Diagnostic Trouble Code Information Extended - EOCM_HCP2 : Warning Indicator Triggered";
BA_ "SignalType" SG_ 1432 DTCI_EOCM_HCP2_WrnIndRqd "ENM";
BA_ "SignalLongName" SG_ 1432 DTCI_EOCM_HCP2_WrnIndRqd "Diagnostic Trouble Code Information Extended - EOCM_HCP2 : Warning Indicator Requested";
BA_ "SignalLongName" SG_ 1433 DTCI_FCM_LC_DTCFailType "Diagnostic Trouble Code Information Extended - FCM_LC : Diagnostic Trouble Code Failure Type";
BA_ "SignalType" SG_ 1433 DTCI_FCM_LC_CnfrmdDTC "ENM";
BA_ "SignalLongName" SG_ 1433 DTCI_FCM_LC_CnfrmdDTC "Diagnostic Trouble Code Information Extended - FCM_LC : Confirmed DTC";
BA_ "SignalType" SG_ 1433 DTCI_FCM_LC_DTCFaultType "ENM";
BA_ "SignalLongName" SG_ 1433 DTCI_FCM_LC_DTCFaultType "Diagnostic Trouble Code Information Extended - FCM_LC : Diagnostic Trouble Code Fault Type";
BA_ "SignalLongName" SG_ 1433 DTCI_FCM_LC_DTCNumber "Diagnostic Trouble Code Information Extended - FCM_LC : Diagnostic Trouble Code Number";
BA_ "SignalLongName" SG_ 1433 DTCI_FCM_LC_DTCSource "Diagnostic Trouble Code Information Extended - FCM_LC : Diagnostic Trouble Code Source";
BA_ "SignalType" SG_ 1433 DTCI_FCM_LC_TstNCmpltdOpCyc "ENM";
BA_ "SignalLongName" SG_ 1433 DTCI_FCM_LC_TstNCmpltdOpCyc "Diagnostic Trouble Code Information Extended - FCM_LC : Test Not Completed This Operation Cycle";
BA_ "SignalType" SG_ 1433 DTCI_FCM_LC_TstNCmpltdLstClr "ENM";
BA_ "SignalLongName" SG_ 1433 DTCI_FCM_LC_TstNCmpltdLstClr "Diagnostic Trouble Code Information Extended - FCM_LC : Test Not Completed Since Last Clear";
BA_ "SignalType" SG_ 1433 DTCI_FCM_LC_TstFldOpCyc "ENM";
BA_ "SignalLongName" SG_ 1433 DTCI_FCM_LC_TstFldOpCyc "Diagnostic Trouble Code Information Extended - FCM_LC : Test Failed This Operation Cycle";
BA_ "SignalType" SG_ 1433 DTCI_FCM_LC_TstFldLstClr "ENM";
BA_ "SignalLongName" SG_ 1433 DTCI_FCM_LC_TstFldLstClr "Diagnostic Trouble Code Information Extended - FCM_LC : Test Failed Since Last Clear";
BA_ "SignalType" SG_ 1433 DTCI_FCM_LC_TstFld "ENM";
BA_ "SignalLongName" SG_ 1433 DTCI_FCM_LC_TstFld "Diagnostic Trouble Code Information Extended - FCM_LC : Test Failed";
BA_ "SignalType" SG_ 1433 DTCI_FCM_LC_PndngDTC "ENM";
BA_ "SignalLongName" SG_ 1433 DTCI_FCM_LC_PndngDTC "Diagnostic Trouble Code Information Extended - FCM_LC : Pending DTC";
BA_ "SignalType" SG_ 1433 DTCI_FCM_LC_DTCTriggered "ENM";
BA_ "SignalLongName" SG_ 1433 DTCI_FCM_LC_DTCTriggered "Diagnostic Trouble Code Information Extended - FCM_LC : Diagnostic Trouble Code Triggered";
BA_ "SignalType" SG_ 1433 DTCI_FCM_LC_WrnIndTrggrd "ENM";
BA_ "SignalLongName" SG_ 1433 DTCI_FCM_LC_WrnIndTrggrd "Diagnostic Trouble Code Information Extended - FCM_LC : Warning Indicator Triggered";
BA_ "SignalType" SG_ 1433 DTCI_FCM_LC_WrnIndRqd "ENM";
BA_ "SignalLongName" SG_ 1433 DTCI_FCM_LC_WrnIndRqd "Diagnostic Trouble Code Information Extended - FCM_LC : Warning Indicator Requested";
VAL_ 2147745829 ACP2_MCU_CAN_8_ClscCANHrtBtActv 0 "FALSE" 1 "TRUE" ;
VAL_ 2147745830 ACP3_MCU_CAN8_ClscCANHrtBtActv 0 "FALSE" 1 "TRUE" ;
VAL_ 2147745831 ACP4_MCU_CAN8_ClscCANHrtBtActv 0 "FALSE" 1 "TRUE" ;
VAL_ 512 ALOI1_AcqTmStm_Inv 0 "FALSE" 1 "TRUE" ;
VAL_ 512 ALOI1_CnfdTk1 0 "Highly Speculative" 1 "Speculative" 2 "Confident" 3 "Highly Confident" ;
VAL_ 512 ALOI1_DirTk1 0 "Following" 1 "Oncoming" 2 "Following Goup" 3 "Oncoming Group" 4 "Unknown" ;
VAL_ 512 ALOI1_CnfdTk4 0 "Highly Speculative" 1 "Speculative" 2 "Confident" 3 "Highly Confident" ;
VAL_ 512 ALOI1_CnfdTk3 0 "Highly Speculative" 1 "Speculative" 2 "Confident" 3 "Highly Confident" ;
VAL_ 512 ALOI1_CnfdTk2 0 "Highly Speculative" 1 "Speculative" 2 "Confident" 3 "Highly Confident" ;
VAL_ 512 ALOI1_DirTk4 0 "Following" 1 "Oncoming" 2 "Following Goup" 3 "Oncoming Group" 4 "Unknown" ;
VAL_ 512 ALOI1_DirTk3 0 "Following" 1 "Oncoming" 2 "Following Goup" 3 "Oncoming Group" 4 "Unknown" ;
VAL_ 512 ALOI1_DirTk2 0 "Following" 1 "Oncoming" 2 "Following Goup" 3 "Oncoming Group" 4 "Unknown" ;
VAL_ 512 ALOI1_MeasStsTk3 0 "No Object" 1 "New Object" 2 "Latent Track Not Detected This Cycle" 3 "Measured This Cycle" ;
VAL_ 512 ALOI1_MeasStsTk2 0 "No Object" 1 "New Object" 2 "Latent Track Not Detected This Cycle" 3 "Measured This Cycle" ;
VAL_ 512 ALOI1_MeasStsTk1 0 "No Object" 1 "New Object" 2 "Latent Track Not Detected This Cycle" 3 "Measured This Cycle" ;
VAL_ 512 ALOI1_MeasStsTk4 0 "No Object" 1 "New Object" 2 "Latent Track Not Detected This Cycle" 3 "Measured This Cycle" ;
VAL_ 512 ALOI1_RltvLnTk1 0 "Unknown" 1 "Host Lane" 2 "Right Lane" 3 "Left Lane" ;
VAL_ 512 ALOI1_RltvLnTk4 0 "Unknown" 1 "Host Lane" 2 "Right Lane" 3 "Left Lane" ;
VAL_ 512 ALOI1_RltvLnTk3 0 "Unknown" 1 "Host Lane" 2 "Right Lane" 3 "Left Lane" ;
VAL_ 512 ALOI1_RltvLnTk2 0 "Unknown" 1 "Host Lane" 2 "Right Lane" 3 "Left Lane" ;
VAL_ 512 ALOI1_RngTk1_Inv 0 "FALSE" 1 "TRUE" ;
VAL_ 512 ALOI1_RngTk2_Inv 0 "FALSE" 1 "TRUE" ;
VAL_ 512 ALOI1_RngTk3_Inv 0 "FALSE" 1 "TRUE" ;
VAL_ 512 ALOI1_TypTk2 0 "UNKNOWN" 1 "4 WHEEL VEHICLE" 2 "LARGE VEHICLE" 3 "MOTORCYCLE/BICYCLE" 4 "PEDESTRIAN" 5 "FIXED OVERHEAD OBJECT" 6 "FIXED ROADSIDE OBJECT" 7 "NO OBJECT PRESENT" 8 "PEDESTRIAN STANDING OUTSIDE DANGER ZONE" 9 "PEDESTRIAN MOVING OUT OF DANGER ZONE" 10 "PEDESTRIAN MOVING INTO DANGER ZONE" 11 "CHILD CLOSE TO DANGER ZONE" 12 "CLUSTER OBJECT" ;
VAL_ 512 ALOI1_TypTk1 0 "UNKNOWN" 1 "4 WHEEL VEHICLE" 2 "LARGE VEHICLE" 3 "MOTORCYCLE/BICYCLE" 4 "PEDESTRIAN" 5 "FIXED OVERHEAD OBJECT" 6 "FIXED ROADSIDE OBJECT" 7 "NO OBJECT PRESENT" 8 "PEDESTRIAN STANDING OUTSIDE DANGER ZONE" 9 "PEDESTRIAN MOVING OUT OF DANGER ZONE" 10 "PEDESTRIAN MOVING INTO DANGER ZONE" 11 "CHILD CLOSE TO DANGER ZONE" 12 "CLUSTER OBJECT" ;
VAL_ 512 ALOI1_RngTk4_Inv 0 "FALSE" 1 "TRUE" ;
VAL_ 512 ALOI1_TypTk4 0 "UNKNOWN" 1 "4 WHEEL VEHICLE" 2 "LARGE VEHICLE" 3 "MOTORCYCLE/BICYCLE" 4 "PEDESTRIAN" 5 "FIXED OVERHEAD OBJECT" 6 "FIXED ROADSIDE OBJECT" 7 "NO OBJECT PRESENT" 8 "PEDESTRIAN STANDING OUTSIDE DANGER ZONE" 9 "PEDESTRIAN MOVING OUT OF DANGER ZONE" 10 "PEDESTRIAN MOVING INTO DANGER ZONE" 11 "CHILD CLOSE TO DANGER ZONE" 12 "CLUSTER OBJECT" ;
VAL_ 512 ALOI1_TypTk3 0 "UNKNOWN" 1 "4 WHEEL VEHICLE" 2 "LARGE VEHICLE" 3 "MOTORCYCLE/BICYCLE" 4 "PEDESTRIAN" 5 "FIXED OVERHEAD OBJECT" 6 "FIXED ROADSIDE OBJECT" 7 "NO OBJECT PRESENT" 8 "PEDESTRIAN STANDING OUTSIDE DANGER ZONE" 9 "PEDESTRIAN MOVING OUT OF DANGER ZONE" 10 "PEDESTRIAN MOVING INTO DANGER ZONE" 11 "CHILD CLOSE TO DANGER ZONE" 12 "CLUSTER OBJECT" ;
VAL_ 514 ALOI2_AcqTmStm_Inv 0 "FALSE" 1 "TRUE" ;
VAL_ 514 ALOI2_CnfdTk5 0 "Highly Speculative" 1 "Speculative" 2 "Confident" 3 "Highly Confident" ;
VAL_ 514 ALOI2_DirTk5 0 "Following" 1 "Oncoming" 2 "Following Goup" 3 "Oncoming Group" 4 "Unknown" ;
VAL_ 514 ALOI2_CnfdTk8 0 "Highly Speculative" 1 "Speculative" 2 "Confident" 3 "Highly Confident" ;
VAL_ 514 ALOI2_CnfdTk7 0 "Highly Speculative" 1 "Speculative" 2 "Confident" 3 "Highly Confident" ;
VAL_ 514 ALOI2_CnfdTk6 0 "Highly Speculative" 1 "Speculative" 2 "Confident" 3 "Highly Confident" ;
VAL_ 514 ALOI2_DirTk8 0 "Following" 1 "Oncoming" 2 "Following Goup" 3 "Oncoming Group" 4 "Unknown" ;
VAL_ 514 ALOI2_DirTk7 0 "Following" 1 "Oncoming" 2 "Following Goup" 3 "Oncoming Group" 4 "Unknown" ;
VAL_ 514 ALOI2_DirTk6 0 "Following" 1 "Oncoming" 2 "Following Goup" 3 "Oncoming Group" 4 "Unknown" ;
VAL_ 514 ALOI2_MeasStsTk7 0 "No Object" 1 "New Object" 2 "Latent Track Not Detected This Cycle" 3 "Measured This Cycle" ;
VAL_ 514 ALOI2_MeasStsTk6 0 "No Object" 1 "New Object" 2 "Latent Track Not Detected This Cycle" 3 "Measured This Cycle" ;
VAL_ 514 ALOI2_MeasStsTk5 0 "No Object" 1 "New Object" 2 "Latent Track Not Detected This Cycle" 3 "Measured This Cycle" ;
VAL_ 514 ALOI2_MeasStsTk8 0 "No Object" 1 "New Object" 2 "Latent Track Not Detected This Cycle" 3 "Measured This Cycle" ;
VAL_ 514 ALOI2_RltvLnTk5 0 "Unknown" 1 "Host Lane" 2 "Right Lane" 3 "Left Lane" ;
VAL_ 514 ALOI2_RltvLnTk8 0 "Unknown" 1 "Host Lane" 2 "Right Lane" 3 "Left Lane" ;
VAL_ 514 ALOI2_RltvLnTk7 0 "Unknown" 1 "Host Lane" 2 "Right Lane" 3 "Left Lane" ;
VAL_ 514 ALOI2_RltvLnTk6 0 "Unknown" 1 "Host Lane" 2 "Right Lane" 3 "Left Lane" ;
VAL_ 514 ALOI2_RngTk5_Inv 0 "FALSE" 1 "TRUE" ;
VAL_ 514 ALOI2_RngTk6_Inv 0 "FALSE" 1 "TRUE" ;
VAL_ 514 ALOI2_RngTk7_Inv 0 "FALSE" 1 "TRUE" ;
VAL_ 514 ALOI2_TypTk6 0 "UNKNOWN" 1 "4 WHEEL VEHICLE" 2 "LARGE VEHICLE" 3 "MOTORCYCLE/BICYCLE" 4 "PEDESTRIAN" 5 "FIXED OVERHEAD OBJECT" 6 "FIXED ROADSIDE OBJECT" 7 "NO OBJECT PRESENT" 8 "PEDESTRIAN STANDING OUTSIDE DANGER ZONE" 9 "PEDESTRIAN MOVING OUT OF DANGER ZONE" 10 "PEDESTRIAN MOVING INTO DANGER ZONE" 11 "CHILD CLOSE TO DANGER ZONE" 12 "CLUSTER OBJECT" ;
VAL_ 514 ALOI2_TypTk5 0 "UNKNOWN" 1 "4 WHEEL VEHICLE" 2 "LARGE VEHICLE" 3 "MOTORCYCLE/BICYCLE" 4 "PEDESTRIAN" 5 "FIXED OVERHEAD OBJECT" 6 "FIXED ROADSIDE OBJECT" 7 "NO OBJECT PRESENT" 8 "PEDESTRIAN STANDING OUTSIDE DANGER ZONE" 9 "PEDESTRIAN MOVING OUT OF DANGER ZONE" 10 "PEDESTRIAN MOVING INTO DANGER ZONE" 11 "CHILD CLOSE TO DANGER ZONE" 12 "CLUSTER OBJECT" ;
VAL_ 514 ALOI2_RngTk8_Inv 0 "FALSE" 1 "TRUE" ;
VAL_ 514 ALOI2_TypTk8 0 "UNKNOWN" 1 "4 WHEEL VEHICLE" 2 "LARGE VEHICLE" 3 "MOTORCYCLE/BICYCLE" 4 "PEDESTRIAN" 5 "FIXED OVERHEAD OBJECT" 6 "FIXED ROADSIDE OBJECT" 7 "NO OBJECT PRESENT" 8 "PEDESTRIAN STANDING OUTSIDE DANGER ZONE" 9 "PEDESTRIAN MOVING OUT OF DANGER ZONE" 10 "PEDESTRIAN MOVING INTO DANGER ZONE" 11 "CHILD CLOSE TO DANGER ZONE" 12 "CLUSTER OBJECT" ;
VAL_ 514 ALOI2_TypTk7 0 "UNKNOWN" 1 "4 WHEEL VEHICLE" 2 "LARGE VEHICLE" 3 "MOTORCYCLE/BICYCLE" 4 "PEDESTRIAN" 5 "FIXED OVERHEAD OBJECT" 6 "FIXED ROADSIDE OBJECT" 7 "NO OBJECT PRESENT" 8 "PEDESTRIAN STANDING OUTSIDE DANGER ZONE" 9 "PEDESTRIAN MOVING OUT OF DANGER ZONE" 10 "PEDESTRIAN MOVING INTO DANGER ZONE" 11 "CHILD CLOSE TO DANGER ZONE" 12 "CLUSTER OBJECT" ;
VAL_ 206 ARDG1_HstLnLtTyp 0 "Undecided" 1 "Solid" 2 "Dashed" 3 "Road Edge" 4 "Double Line" 5 "Botts Dots" 6 "Virtual" 7 "Triple Line" ;
VAL_ 206 ARDG1_HstLnLtQlty 0 "Very Low Quality" 1 "Low Quality" 2 "Prediction" 3 "High Quality" ;
VAL_ 206 ARDG1_HstNxtLnLtTyp 0 "Undecided" 1 "Solid" 2 "Dashed" 3 "Road Edge" 4 "Double Line" 5 "Botts Dots" 6 "Virtual" 7 "Triple Line" ;
VAL_ 206 ARDG1_HstNxtLnLtQlty 0 "Very Low Quality" 1 "Low Quality" 2 "Prediction" 3 "High Quality" ;
VAL_ 206 ARDG1_LtVehAhdMeasSts 0 "No Object" 1 "New Object" 2 "Latent Track Not Detected this Cycle" 3 "Measured this Cycle" ;
VAL_ 206 ARDG2_AutfxOutOfCal 0 "Unknown" 1 "Yaw" 2 "Horizon" 3 "Both" ;
VAL_ 206 ARDG2_FrwdCamSysOprtgSts 0 "Unknown" 1 "Initializing" 2 "Inactive" 3 "Active" 4 "Programing" 5 "Reserved 1" 6 "Reserved 2" 7 "Failed" ;
VAL_ 206 ARDG2_HstVehAhdMeasSts 0 "No Object" 1 "New Object" 2 "Latent Track Not Detected this Cycle" 3 "Measured this Cycle" ;
VAL_ 206 ARDG2_FrwdVsnUnv 0 "FALSE" 1 "TRUE" ;
VAL_ 206 ARDG2_FrwdVsnTmStm_Inv 0 "FALSE" 1 "TRUE" ;
VAL_ 204 ARDG3_HstLnRtTyp 0 "Undecided" 1 "Solid" 2 "Dashed" 3 "Road Edge" 4 "Double Line" 5 "Botts Dots" 6 "Virtual" 7 "Triple Line" ;
VAL_ 204 ARDG3_HstLnRtQlty 0 "Very Low Quality" 1 "Low Quality" 2 "Prediction" 3 "High Quality" ;
VAL_ 204 ARDG3_HstNxtLnRtTyp 0 "Undecided" 1 "Solid" 2 "Dashed" 3 "Road Edge" 4 "Double Line" 5 "Botts Dots" 6 "Virtual" 7 "Triple Line" ;
VAL_ 204 ARDG3_HstNxtLnRtQlty 0 "Very Low Quality" 1 "Low Quality" 2 "Prediction" 3 "High Quality" ;
VAL_ 204 ARDG3_RtVehAhdMeasSts 0 "No Object" 1 "New Object" 2 "Latent Track Not Detected this Cycle" 3 "Measured this Cycle" ;
VAL_ 880 BSPMP_BkupSysPwrModeAuth_Inv 0 "FALSE" 1 "TRUE" ;
VAL_ 880 BSPMP_BkupSysPwrModeAuth 0 "Off" 1 "Accessory" 2 "Run" 3 "Start Request" 4 "Propulsion" ;
VAL_ 880 BSPMP_SecRunCrnkCmdActvAuth_Inv 0 "FALSE" 1 "TRUE" ;
VAL_ 880 BSPMP_SecRunCrnkCmdActvAuth 0 "FALSE" 1 "TRUE" ;
VAL_ 880 BSPMP_SecPwrModePBActvAuth_Inv 0 "FALSE" 1 "TRUE" ;
VAL_ 880 BSPMP_SecPwrModePBActvAuth 0 "FALSE" 1 "TRUE" ;
VAL_ 880 BSPMP_RmtProgmActvAuth 0 "FALSE" 1 "TRUE" ;
VAL_ 1446 DTCI_ACP2_MCU_CnfrmdDTC 0 "FALSE" 1 "TRUE" ;
VAL_ 1446 DTCI_ACP2_MCU_DTCFaultType 0 "Not Supported" 1 "Type A" 2 "Type B" 3 "Type C" ;
VAL_ 1446 DTCI_ACP2_MCU_TstNCmpltdOpCyc 0 "FALSE" 1 "TRUE" ;
VAL_ 1446 DTCI_ACP2_MCU_TstNCmpltdLstClr 0 "FALSE" 1 "TRUE" ;
VAL_ 1446 DTCI_ACP2_MCU_TstFldOpCyc 0 "FALSE" 1 "TRUE" ;
VAL_ 1446 DTCI_ACP2_MCU_TstFldLstClr 0 "FALSE" 1 "TRUE" ;
VAL_ 1446 DTCI_ACP2_MCU_TstFld 0 "FALSE" 1 "TRUE" ;
VAL_ 1446 DTCI_ACP2_MCU_PndngDTC 0 "FALSE" 1 "TRUE" ;
VAL_ 1446 DTCI_ACP2_MCU_DTCTriggered 0 "FALSE" 1 "TRUE" ;
VAL_ 1446 DTCI_ACP2_MCU_WrnIndTrggrd 0 "FALSE" 1 "TRUE" ;
VAL_ 1446 DTCI_ACP2_MCU_WrnIndRqd 0 "FALSE" 1 "TRUE" ;
VAL_ 1207 DTCI_ACP3_MCU_CnfrmdDTC 0 "FALSE" 1 "TRUE" ;
VAL_ 1207 DTCI_ACP3_MCU_DTCFaultType 0 "Not Supported" 1 "Type A" 2 "Type B" 3 "Type C" ;
VAL_ 1207 DTCI_ACP3_MCU_TstNCmpltdOpCyc 0 "FALSE" 1 "TRUE" ;
VAL_ 1207 DTCI_ACP3_MCU_TstNCmpltdLstClr 0 "FALSE" 1 "TRUE" ;
VAL_ 1207 DTCI_ACP3_MCU_TstFldOpCyc 0 "FALSE" 1 "TRUE" ;
VAL_ 1207 DTCI_ACP3_MCU_TstFldLstClr 0 "FALSE" 1 "TRUE" ;
VAL_ 1207 DTCI_ACP3_MCU_TstFld 0 "FALSE" 1 "TRUE" ;
VAL_ 1207 DTCI_ACP3_MCU_PndngDTC 0 "FALSE" 1 "TRUE" ;
VAL_ 1207 DTCI_ACP3_MCU_DTCTriggered 0 "FALSE" 1 "TRUE" ;
VAL_ 1207 DTCI_ACP3_MCU_WrnIndTrggrd 0 "FALSE" 1 "TRUE" ;
VAL_ 1207 DTCI_ACP3_MCU_WrnIndRqd 0 "FALSE" 1 "TRUE" ;
VAL_ 1448 DTCI_ACP4_MCU_CnfrmdDTC 0 "FALSE" 1 "TRUE" ;
VAL_ 1448 DTCI_ACP4_MCU_DTCFaultType 0 "Not Supported" 1 "Type A" 2 "Type B" 3 "Type C" ;
VAL_ 1448 DTCI_ACP4_MCU_TstNCmpltdOpCyc 0 "FALSE" 1 "TRUE" ;
VAL_ 1448 DTCI_ACP4_MCU_TstNCmpltdLstClr 0 "FALSE" 1 "TRUE" ;
VAL_ 1448 DTCI_ACP4_MCU_TstFldOpCyc 0 "FALSE" 1 "TRUE" ;
VAL_ 1448 DTCI_ACP4_MCU_TstFldLstClr 0 "FALSE" 1 "TRUE" ;
VAL_ 1448 DTCI_ACP4_MCU_TstFld 0 "FALSE" 1 "TRUE" ;
VAL_ 1448 DTCI_ACP4_MCU_PndngDTC 0 "FALSE" 1 "TRUE" ;
VAL_ 1448 DTCI_ACP4_MCU_DTCTriggered 0 "FALSE" 1 "TRUE" ;
VAL_ 1448 DTCI_ACP4_MCU_WrnIndTrggrd 0 "FALSE" 1 "TRUE" ;
VAL_ 1448 DTCI_ACP4_MCU_WrnIndRqd 0 "FALSE" 1 "TRUE" ;
VAL_ 1432 DTCI_EOCM_HCP2_CnfrmdDTC 0 "FALSE" 1 "TRUE" ;
VAL_ 1432 DTCI_EOCM_HCP2_DTCFaultType 0 "Not Supported" 1 "Type A" 2 "Type B" 3 "Type C" ;
VAL_ 1432 DTCI_EOCM_HCP2_TstNCmpltdOpCyc 0 "FALSE" 1 "TRUE" ;
VAL_ 1432 DTCI_EOCM_HCP2_TstNCmpltdLstClr 0 "FALSE" 1 "TRUE" ;
VAL_ 1432 DTCI_EOCM_HCP2_TstFldOpCyc 0 "FALSE" 1 "TRUE" ;
VAL_ 1432 DTCI_EOCM_HCP2_TstFldLstClr 0 "FALSE" 1 "TRUE" ;
VAL_ 1432 DTCI_EOCM_HCP2_TstFld 0 "FALSE" 1 "TRUE" ;
VAL_ 1432 DTCI_EOCM_HCP2_PndngDTC 0 "FALSE" 1 "TRUE" ;
VAL_ 1432 DTCI_EOCM_HCP2_DTCTriggered 0 "FALSE" 1 "TRUE" ;
VAL_ 1432 DTCI_EOCM_HCP2_WrnIndTrggrd 0 "FALSE" 1 "TRUE" ;
VAL_ 1432 DTCI_EOCM_HCP2_WrnIndRqd 0 "FALSE" 1 "TRUE" ;
VAL_ 1433 DTCI_FCM_LC_CnfrmdDTC 0 "FALSE" 1 "TRUE" ;
VAL_ 1433 DTCI_FCM_LC_DTCFaultType 0 "Not Supported" 1 "Type A" 2 "Type B" 3 "Type C" ;
VAL_ 1433 DTCI_FCM_LC_TstNCmpltdOpCyc 0 "FALSE" 1 "TRUE" ;
VAL_ 1433 DTCI_FCM_LC_TstNCmpltdLstClr 0 "FALSE" 1 "TRUE" ;
VAL_ 1433 DTCI_FCM_LC_TstFldOpCyc 0 "FALSE" 1 "TRUE" ;
VAL_ 1433 DTCI_FCM_LC_TstFldLstClr 0 "FALSE" 1 "TRUE" ;
VAL_ 1433 DTCI_FCM_LC_TstFld 0 "FALSE" 1 "TRUE" ;
VAL_ 1433 DTCI_FCM_LC_PndngDTC 0 "FALSE" 1 "TRUE" ;
VAL_ 1433 DTCI_FCM_LC_DTCTriggered 0 "FALSE" 1 "TRUE" ;
VAL_ 1433 DTCI_FCM_LC_WrnIndTrggrd 0 "FALSE" 1 "TRUE" ;
VAL_ 1433 DTCI_FCM_LC_WrnIndRqd 0 "FALSE" 1 "TRUE" ;
